VERSION "dbc-export 1 2026.26.6.5"

NS_ :

BS_:

BU_: APP APS BMS CC CMP CMPD CP DAS DI DIF DIR EPBL EPBR EVSE FC GTW HCML HCMR HVP ICR PCS PCS2 PLG PM PMF PMR PTC SCCM SCM SCS SDCR TAS UMC V2G VC VCBATT VCBATT0 VCBATT1 VCBATT2 VCFRONT VCFRONT1 VCFRONT2 VCLEFT VCRIGHT VCSEAT2L VCSEAT2R VCSEC

BO_ 946 BMS_log2: 8 BMS
 SG_ BMS_log2MuxId M : 0|7@1+ (1,0) [0|127] "" Vector__XXX
 SG_ BMS_maxChargeRestartNeededByVolt m0 : 7|1@1+ (1,0) [0|1] "" Vector__XXX
 SG_ BMS_cacAvg m0 : 8|13@1+ (0.1,0) [0|819.1] "Ah" Vector__XXX
 SG_ BMS_maxChargeNearComplete m0 : 21|1@1+ (1,0) [0|1] "" Vector__XXX
 SG_ BMS_cacMin m0 : 24|13@1+ (0.1,0) [0|819.1] "Ah" Vector__XXX
 SG_ BMS_cacMinBrickId m0 : 37|7@1+ (1,1) [1|128] "" Vector__XXX
 SG_ BMS_cacMax m0 : 44|13@1+ (0.1,0) [0|819.1] "Ah" Vector__XXX
 SG_ BMS_cacMaxBrickId m0 : 57|7@1+ (1,1) [1|128] "" Vector__XXX
 SG_ BMS_acRippleConfigNvramValid m18 : 7|1@1+ (1,0) [0|1] "" Vector__XXX
 SG_ BMS_hvChain_useLeakyBucket m18 : 8|1@1+ (1,0) [0|1] "" Vector__XXX
 SG_ BMS_hvChain_iLimit m18 : 9|14@1+ (0.2,0) [0|3275] "A" Vector__XXX
 SG_ BMS_hvChain_limitingState m18 : 23|9@1+ (1,1) [1|511] "" Vector__XXX
 SG_ BMS_hvChain_limitingStateTempera m18 : 32|13@1- (0.1,367.6) [-40|775] "DegC" Vector__XXX
 SG_ BMS_acRippleIsSupported m18 : 45|1@1+ (1,0) [0|1] "" Vector__XXX
 SG_ BMS_acRippleStartTemperatureMax m18 : 46|9@1+ (0.25,-25) [-25|100] "DegC" Vector__XXX
 SG_ BMS_acRippleStartTemperatureMin m18 : 55|9@1+ (0.25,-25) [-25|100] "DegC" Vector__XXX
 SG_ BMS_fcLinkTestDecayTime m20 : 8|10@1+ (2,0) [0|2044] "mS" Vector__XXX
 SG_ BMS_fcLinkTestTimeSinceLastRun m20 : 18|12@1+ (0.0175824183971,0) [0|71.99] "Hours" Vector__XXX
 SG_ BMS_pcsPrechargeRequest m20 : 30|2@1+ (1,0) [0|3] "" Vector__XXX
 SG_ BMS_pcsPrechargeTargetVoltage m20 : 32|16@1- (0.1,0) [-3276.8|3276.7] "V" Vector__XXX
 SG_ BMS_recentOvUvAlert m20 : 48|1@1+ (1,0) [0|1] "" Vector__XXX
 SG_ BMS_recentIsoAlert m20 : 49|1@1+ (1,0) [0|1] "" Vector__XXX
 SG_ BMS_recentBmbMiaAlert m20 : 50|1@1+ (1,0) [0|1] "" Vector__XXX
 SG_ BMS_cacBlendingConfigNvramValid m20 : 51|1@1+ (1,0) [0|1] "" Vector__XXX
 SG_ BMS_cacBlendingEnabled m20 : 52|1@1+ (1,0) [0|1] "" Vector__XXX
 SG_ BMS_cacBlendPercentPerCycle m20 : 53|10@1+ (0.001,0) [0|1.023] "%" Vector__XXX
 SG_ BMS_energyVariableChgRequested m21 : 8|1@1+ (1,0) [0|1] "" Vector__XXX
 SG_ BMS_packRestTime m21 : 9|12@1+ (0.0175824183971,0) [0|71.99] "Hours" Vector__XXX
 SG_ BMS_idealEnergyFloor m21 : 21|10@1+ (0.1,0) [0|102.2] "KWh" Vector__XXX
 SG_ BMS_thmGradientSlopeCondition m21 : 31|1@1+ (1,0) [0|1] "" Vector__XXX
 SG_ BMS_recentSlopeConditon m21 : 32|1@1+ (1,0) [0|1] "" Vector__XXX
 SG_ BMS_dynamicEnergyBuffer m21 : 33|10@1+ (0.1,0) [0|102.2] "KWh" Vector__XXX
 SG_ BMS_temperatureCondition m21 : 43|1@1+ (1,0) [0|1] "" Vector__XXX
 SG_ BMS_thmGradientSlope m21 : 44|10@1- (0.01,0) [-5.12|5.11] "C/min" Vector__XXX
 SG_ BMS_thmGradient m21 : 56|8@1+ (0.1,0) [0|25.5] "C" Vector__XXX
 SG_ BMS_epochTimeEstimate m29 : 8|32@1+ (1,0) [0|4294967295] "s" Vector__XXX
 SG_ BMS_histogramStartTimeIrrational m30 : 57|1@1+ (1,0) [0|1] "" Vector__XXX
 SG_ BMS_histogramDischargeThroughput m30 : 58|1@1+ (1,0) [0|1] "" Vector__XXX
 SG_ BMS_histogramChargeThroughputIrr m30 : 59|1@1+ (1,0) [0|1] "" Vector__XXX
 SG_ BMS_histogramTotalTimeIrrational m30 : 60|1@1+ (1,0) [0|1] "" Vector__XXX
 SG_ BMS_histogramStorageDataIsLow m30 : 61|1@1+ (1,0) [0|1] "" Vector__XXX
 SG_ BMS_tempVsSocTotalChgEnergy m31 : 7|25@1+ (0.000149011611938,0) [0|4999.99985097] "wh/wh" Vector__XXX
 SG_ BMS_powerVsVoltageTotalChgEnergy m31 : 32|25@1+ (0.000149011611938,0) [0|4999.99985097] "wh/wh" Vector__XXX
 SG_ BMS_lifeModelOutputsAreTrustwort m31 : 57|1@1+ (1,0) [0|1] "" Vector__XXX
 SG_ BMS_dSocNormalizedMin m33 : 8|12@1+ (0.0030517578125,-12.4969482422) [-12.4969482422|-0.003051757825] "%" Vector__XXX
 SG_ BMS_dSocNormalizedFiltMin m33 : 20|12@1+ (0.0030517578125,-12.4969482422) [-12.4969482422|-0.003051757825] "%" Vector__XXX
 SG_ BMS_dSocMinAlpha m33 : 32|12@1+ (0.0030517578125,-12.4969482422) [-12.4969482422|-0.003051757825] "%" Vector__XXX
 SG_ BMS_dSocMaxLowAlphaCounter m33 : 44|4@1+ (1,0) [0|15] "" Vector__XXX
 SG_ BMS_dSocMinAlphaBrickID m33 : 48|7@1+ (1,1) [1|128] "" Vector__XXX
 SG_ BMS_dSocCacMargin m33 : 55|9@1+ (0.0030517578125,0) [0|1.55639648438] "%" Vector__XXX
 SG_ BMS_lifeModelNoCurrentStorageCap m54 : 7|9@1+ (0.1,0) [0|51] "%" Vector__XXX
 SG_ BMS_lifeModelShortDcr m54 : 16|8@1+ (0.01,0) [0|2.54] "mOhm" Vector__XXX
 SG_ BMS_lifeModelLongDcr m54 : 24|13@1- (0.1,309.6) [-100|719] "mOhm" Vector__XXX
 SG_ BMS_lifeModelStorageCapacityLoss m54 : 37|9@1+ (0.1,0) [0|51] "%" Vector__XXX
 SG_ BMS_lifeModelThroughputCapacityL m54 : 46|9@1+ (0.1,0) [0|51] "%" Vector__XXX
 SG_ BMS_passiveCoolCellTargetT m54 : 55|9@1+ (0.25,-25) [-25|100] "DegC" Vector__XXX
 SG_ BMS_lifeModelAvgTempSeverity m55 : 8|5@1+ (0.1,0) [0|3] "-" Vector__XXX
 SG_ BMS_lifeModelDepthOfDischargeSev m55 : 16|8@1+ (0.01,0) [0|1.5] "-" Vector__XXX
 SG_ BMS_lifeModelHistogramCapacityLo m55 : 24|9@1+ (0.1,0) [0|51] "%" Vector__XXX
 SG_ BMS_lifeModelHistogramBrickCapac m55 : 33|13@1+ (0.1,0) [0|819] "Ah" Vector__XXX
 SG_ BMS_lifeModelDcrGrowthPercent m55 : 48|14@1- (0.1,200) [-100|500] "%" Vector__XXX
 SG_ BMS_nominalFullPackEnergyRaw m56 : 8|16@1+ (0.02,0) [0|1310.68] "kWh" Vector__XXX
 SG_ BMS_nominalEnergyRemainingBuffer m56 : 24|16@1+ (0.02,0) [0|1310.68] "kWh" Vector__XXX
 SG_ BMS_idealEnergyRemainingBuffered m56 : 40|16@1+ (0.02,0) [0|1310.68] "kWh" Vector__XXX
 SG_ BMS_largestSynchronizedCacErrorP m56 : 56|8@1+ (0.1,0) [0|25.4] "%" Vector__XXX
 SG_ BMS_lifeModelSpreadMinOffset m60 : 8|10@1- (0.1,0) [-51.1|51.1] "Ah" Vector__XXX
 SG_ BMS_lifeModelSpreadMaxOffset m60 : 18|10@1- (0.1,0) [-51.1|51.1] "Ah" Vector__XXX
 SG_ BMS_largestCacSpreadErrorLower m64 : 8|12@1+ (0.1,0) [0|409.4] "Ah" Vector__XXX
 SG_ BMS_lifeModelAverageCac m64 : 20|12@1+ (0.1,0) [0|409.4] "Ah" Vector__XXX
 SG_ BMS_lifeModelCacBrick1 m64 : 32|12@1+ (0.1,0) [0|409.4] "Ah" Vector__XXX
 SG_ BMS_lifeModelAverageOffset m64 : 44|10@1- (0.1,0) [-51.1|51.1] "Ah" Vector__XXX
 SG_ BMS_percentCacUpdatesInTimeWindo m64 : 54|10@1+ (0.1,0) [0|100] "%" Vector__XXX
 SG_ BMS_lifeModelMaxCacBrickId m65 : 8|8@1+ (1,1) [1|255] "" Vector__XXX
 SG_ BMS_lifeModelMaxCac m65 : 16|12@1+ (0.1,0) [0|409.4] "Ah" Vector__XXX
 SG_ BMS_lifeModelMinCacBrickId m65 : 28|8@1+ (1,1) [1|255] "" Vector__XXX
 SG_ BMS_lifeModelMinCac m65 : 36|12@1+ (0.1,0) [0|409.4] "Ah" Vector__XXX
 SG_ BMS_restingPointCacAvg m65 : 48|12@1+ (0.1,0) [0|409.4] "Ah" Vector__XXX
 SG_ BMS_cacEstimationSource m65 : 60|2@1+ (1,0) [0|3] "" Vector__XXX
 SG_ BMS_packCalibrationBirthDateBinn m67 : 26|32@1+ (1,0) [0|4294967295] "" Vector__XXX
 SG_ BMS_synchronizedCacMaxRaw m71 : 8|12@1+ (0.1,0) [0|409.4] "Ah" Vector__XXX
 SG_ BMS_synchronizedCacMinRaw m71 : 20|12@1+ (0.1,0) [0|409.4] "Ah" Vector__XXX
 SG_ BMS_largestSyncCacErrorStartSoc m71 : 32|10@1+ (0.1,0) [0|102.2] "%" Vector__XXX
 SG_ BMS_largestSyncCacErrorEndSoc m71 : 42|10@1+ (0.1,0) [0|102.2] "%" Vector__XXX
 SG_ BMS_runtimeSocConfigNvramValid m71 : 52|1@1+ (1,0) [0|1] "" Vector__XXX
 SG_ BMS_runtimeSocCorrectionsEnabled m71 : 53|1@1+ (1,0) [0|1] "" Vector__XXX
 SG_ BMS_rubberBandingEnabled m71 : 54|1@1+ (1,0) [0|1] "" Vector__XXX
 SG_ BMS_rubberBandingConfigNvramVali m71 : 55|1@1+ (1,0) [0|1] "" Vector__XXX
 SG_ BMS_runtimeSocMinTempForModel m71 : 56|6@1+ (0.5,0) [0|20] "DegC" Vector__XXX
 SG_ BMS_energyBufferConfigNvramValid m71 : 62|1@1+ (1,0) [0|1] "" Vector__XXX
 SG_ BMS_thermalEvent1pDetectConfigDi m71 : 63|1@1+ (1,0) [0|1] "" Vector__XXX
 SG_ BMS_sohEnergy m79 : 8|11@1+ (0.1,0) [0|204.6] "KWh" Vector__XXX
 SG_ BMS_fullCapacitySohEnergy m79 : 19|11@1+ (0.1,0) [0|204.6] "KWh" Vector__XXX
 SG_ BMS_calibratedCapacitySohEnergy m79 : 30|11@1+ (0.1,0) [0|204.6] "KWh" Vector__XXX
 SG_ BMS_estimatedCapacitySohEnergy m79 : 41|11@1+ (0.1,0) [0|204.6] "KWh" Vector__XXX
 SG_ BMS_prevUserFacingSohEnergy m79 : 52|11@1+ (0.1,0) [0|204.6] "KWh" Vector__XXX
 SG_ BMS_stateOfHealthMinCac m80 : 8|13@1+ (0.1,0) [0|819] "Ah" Vector__XXX
 SG_ BMS_lifeModelStorageLossPackAge m80 : 24|14@1+ (1,0) [0|16382] "days" Vector__XXX
 SG_ BMS_lifeModelThroughputDcrCycleC m80 : 38|12@1+ (1,0) [0|4094] "Cycles" Vector__XXX
 SG_ BMS_stateOfHealthMinCacLowerBoun m80 : 50|13@1+ (0.1,0) [0|819] "Ah" Vector__XXX
 SG_ BMS_energyWalkCounter m83 : 8|8@1+ (1,0) [0|255] "" Vector__XXX
 SG_ BMS_energyWalkTimeoutCounter m83 : 16|8@1+ (1,0) [0|255] "" Vector__XXX
 SG_ BMS_dynamicCcvEnabled m83 : 24|1@1+ (1,0) [0|1] "" Vector__XXX
 SG_ BMS_chargeTargetLookupSoc m83 : 25|10@1+ (0.1,0) [0|102.2] "%" Vector__XXX
 SG_ BMS_stateOfHealth m83 : 35|10@1+ (0.1,0) [0|100] "%" Vector__XXX
 SG_ BMS_avgShuntAsicCurrentOffset m83 : 48|15@1- (0.2,0) [-3276.6|3276.6] "mA" Vector__XXX
 SG_ BMS_cellAttributesGeneralAttribu m85 : 7|32@1+ (1,0) [1|4294967295] "" Vector__XXX
 SG_ BMS_cellAttributesPackManufactur m85 : 39|3@1+ (1,0) [1|7] "" Vector__XXX
 SG_ BMS_cellAttributesRemanufactured m85 : 42|1@1+ (1,0) [0|1] "" Vector__XXX
 SG_ BMS_cellAttributesConfigNvramVal m85 : 43|1@1+ (1,0) [0|1] "" Vector__XXX
 SG_ BMS_cellAttributesCellType m85 : 44|6@1+ (1,0) [1|63] "" Vector__XXX
 SG_ BMS_cellAttributesAutocloseAndSc m85 : 50|1@1+ (1,0) [0|1] "" Vector__XXX
 SG_ BMS_cellAttributesShipPackForFai m85 : 51|1@1+ (1,0) [0|1] "" Vector__XXX
 SG_ BMS_lifeModelThroughputCycleCoun m85 : 52|12@1+ (1,0) [0|4094] "Cycles" Vector__XXX
 SG_ BMS_limpChargeCurrentLimit m89 : 8|10@1+ (1,0) [0|1022] "A" Vector__XXX
 SG_ BMS_energyRemainingDisplayError m89 : 18|10@1- (0.1,0) [-50|50] "kWh" Vector__XXX
 SG_ BMS_energyRemainingTDisplayError m89 : 28|10@1- (0.1,0) [-50|50] "kWh" Vector__XXX
 SG_ BMS_numOfThermistors m89 : 38|5@1+ (1,0) [0|31] "" Vector__XXX
 SG_ BMS_numOfBricks m89 : 43|8@1+ (1,0) [0|255] "" Vector__XXX
 SG_ BMS_cellChargeDcCurrentLimit m89 : 51|12@1+ (0.5,0) [0|2047.5] "A" Vector__XXX
 SG_ BMS_socByDeltaVEnabled m90 : 8|1@1+ (1,0) [0|1] "" Vector__XXX
 SG_ BMS_socByDvMaxSocLimit m90 : 9|10@1+ (0.1,0) [0|102.2] "%" Vector__XXX
 SG_ BMS_socByDvVoltageChangeOverAh m90 : 19|9@1+ (0.002,0) [0|1] "V" Vector__XXX
 SG_ BMS_socByDvMaxSocByAhCorrected m90 : 28|10@1+ (0.1,0) [0|102.2] "%" Vector__XXX
 SG_ BMS_socByDvMaxBrickVoltage m90 : 40|12@1+ (0.002,0) [0|5] "V" Vector__XXX
 SG_ BMS_socByDvMaxBrickId m90 : 56|8@1+ (1,1) [1|256] "" Vector__XXX
 SG_ BMS_socByDvMaxSocByAhRaw m91 : 8|10@1+ (0.1,0) [0|102.2] "%" Vector__XXX
 SG_ BMS_voltageInstabilityExcessNois m91 : 18|12@1+ (0.1,0) [0|408] "counts" Vector__XXX
 SG_ BMS_maxModelThermistorTempDelta m91 : 30|10@1- (0.1,0) [-51.2|51.1] "C" Vector__XXX
 SG_ BMS_activeCoolCellTargetT m91 : 40|9@1+ (0.25,-25) [-25|100] "DegC" Vector__XXX
 SG_ BMS_cellTempTargetMode m91 : 49|4@1+ (1,0) [0|15] "" Vector__XXX
 SG_ BMS_minPackTempForChargeToStart m91 : 56|7@1+ (0.5,-40) [-40|23.5] "C" Vector__XXX

BO_ 914 BMS_packConfig: 8 BMS
 SG_ BMS_packConfigMultiplexer M : 0|8@1+ (1,0) [0|255] "" Vector__XXX
 SG_ BMS_reservedConfig_0 m0 : 8|6@1+ (1,0) [0|63] "" Vector__XXX
 SG_ BMS_moduleType m1 : 8|3@1+ (1,0) [0|7] "" Vector__XXX
 SG_ BMS_thermalPackType m1 : 11|4@1+ (1,0) [0|15] "" Vector__XXX
 SG_ BMS_packMass m1 : 16|8@1+ (1,300) [342|540] "kg" Vector__XXX
 SG_ BMS_platformMaxBusVoltage m1 : 24|10@1+ (1,300) [300|1300] "V" Vector__XXX
 SG_ BMS_standbySupplyContinuousPower m1 : 36|2@1+ (1,0) [0|3] "" Vector__XXX
 SG_ BMS_beginningOfLifePackEnergy m1 : 40|10@1+ (0.1,0) [0|102.2] "KWh" Vector__XXX

BO_ 1810 BMS_packTemperatureMeasurements: 8 BMS
 SG_ BMS_packTemperatureMultiplexer M : 0|8@1+ (1,0) [0|255] "" Vector__XXX
 SG_ BMS_packTemperatureCounter : 14|2@1+ (1,0) [0|3] "" Vector__XXX
 SG_ BMS_packTemperatureStatus1 m0 : 8|2@1+ (1,0) [0|3] "" Vector__XXX
 SG_ BMS_packTemperatureStatus2 m0 : 10|2@1+ (1,0) [0|3] "" Vector__XXX
 SG_ BMS_packTemperatureStatus3 m0 : 12|2@1+ (1,0) [0|3] "" Vector__XXX
 SG_ BMS_packTemperature1 m0 : 16|16@1- (0.01,0) [-327.68|327.67] "C" Vector__XXX
 SG_ BMS_packTemperature2 m0 : 32|16@1- (0.01,0) [-327.68|327.67] "C" Vector__XXX
 SG_ BMS_packTemperature3 m0 : 48|16@1- (0.01,0) [-327.68|327.67] "C" Vector__XXX
 SG_ BMS_packTemperatureStatus4 m1 : 8|2@1+ (1,0) [0|3] "" Vector__XXX
 SG_ BMS_packTemperatureStatus5 m1 : 10|2@1+ (1,0) [0|3] "" Vector__XXX
 SG_ BMS_packTemperatureStatus6 m1 : 12|2@1+ (1,0) [0|3] "" Vector__XXX
 SG_ BMS_packTemperature4 m1 : 16|16@1- (0.01,0) [-327.68|327.67] "C" Vector__XXX
 SG_ BMS_packTemperature5 m1 : 32|16@1- (0.01,0) [-327.68|327.67] "C" Vector__XXX
 SG_ BMS_packTemperature6 m1 : 48|16@1- (0.01,0) [-327.68|327.67] "C" Vector__XXX
 SG_ BMS_packTemperatureStatus7 m2 : 8|2@1+ (1,0) [0|3] "" Vector__XXX
 SG_ BMS_packTemperatureStatus8 m2 : 10|2@1+ (1,0) [0|3] "" Vector__XXX
 SG_ BMS_packTemperatureStatus9 m2 : 12|2@1+ (1,0) [0|3] "" Vector__XXX
 SG_ BMS_packTemperature7 m2 : 16|16@1- (0.01,0) [-327.68|327.67] "C" Vector__XXX
 SG_ BMS_packTemperature8 m2 : 32|16@1- (0.01,0) [-327.68|327.67] "C" Vector__XXX
 SG_ BMS_packTemperature9 m2 : 48|16@1- (0.01,0) [-327.68|327.67] "C" Vector__XXX
 SG_ BMS_packTemperatureStatus10 m3 : 8|2@1+ (1,0) [0|3] "" Vector__XXX
 SG_ BMS_packTemperatureStatus11 m3 : 10|2@1+ (1,0) [0|3] "" Vector__XXX
 SG_ BMS_packTemperatureStatus12 m3 : 12|2@1+ (1,0) [0|3] "" Vector__XXX
 SG_ BMS_packTemperature10 m3 : 16|16@1- (0.01,0) [-327.68|327.67] "C" Vector__XXX
 SG_ BMS_packTemperature11 m3 : 32|16@1- (0.01,0) [-327.68|327.67] "C" Vector__XXX
 SG_ BMS_packTemperature12 m3 : 48|16@1- (0.01,0) [-327.68|327.67] "C" Vector__XXX
 SG_ BMS_packTemperatureStatus13 m4 : 8|2@1+ (1,0) [0|3] "" Vector__XXX
 SG_ BMS_packTemperatureStatus14 m4 : 10|2@1+ (1,0) [0|3] "" Vector__XXX
 SG_ BMS_packTemperatureStatus15 m4 : 12|2@1+ (1,0) [0|3] "" Vector__XXX
 SG_ BMS_packTemperature13 m4 : 16|16@1- (0.01,0) [-327.68|327.67] "C" Vector__XXX
 SG_ BMS_packTemperature14 m4 : 32|16@1- (0.01,0) [-327.68|327.67] "C" Vector__XXX
 SG_ BMS_packTemperature15 m4 : 48|16@1- (0.01,0) [-327.68|327.67] "C" Vector__XXX
 SG_ BMS_packTemperatureStatus16 m5 : 8|2@1+ (1,0) [0|3] "" Vector__XXX
 SG_ BMS_packTemperatureStatus17 m5 : 10|2@1+ (1,0) [0|3] "" Vector__XXX
 SG_ BMS_packTemperatureStatus18 m5 : 12|2@1+ (1,0) [0|3] "" Vector__XXX
 SG_ BMS_packTemperature16 m5 : 16|16@1- (0.01,0) [-327.68|327.67] "C" Vector__XXX
 SG_ BMS_packTemperature17 m5 : 32|16@1- (0.01,0) [-327.68|327.67] "C" Vector__XXX
 SG_ BMS_packTemperature18 m5 : 48|16@1- (0.01,0) [-327.68|327.67] "C" Vector__XXX

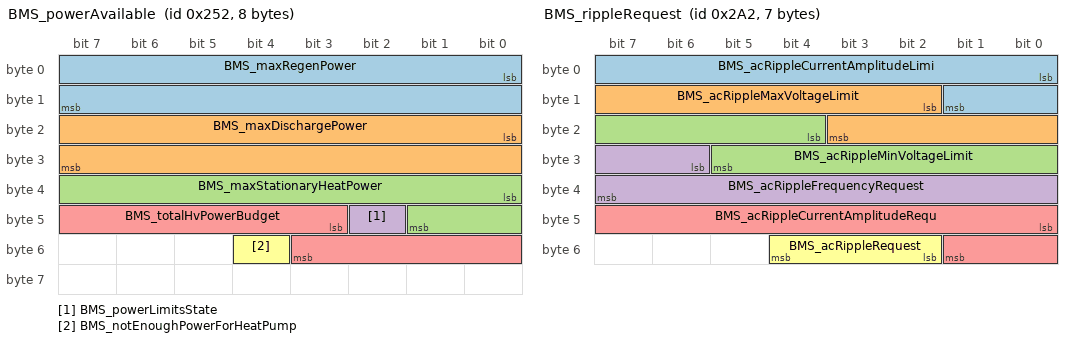
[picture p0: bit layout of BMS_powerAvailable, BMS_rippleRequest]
BO_ 594 BMS_powerAvailable: 8 BMS
 SG_ BMS_maxRegenPower : 0|16@1+ (0.01,0) [0|655.35] "kW" Vector__XXX
 SG_ BMS_maxDischargePower : 16|16@1+ (0.013,0) [0|850] "kW" Vector__XXX
 SG_ BMS_maxStationaryHeatPower : 32|10@1+ (0.01,0) [0|10.23] "kW" Vector__XXX
 SG_ BMS_powerLimitsState : 42|1@1+ (1,0) [0|1] "" Vector__XXX
 SG_ BMS_totalHvPowerBudget : 43|9@1+ (0.1,0) [0|51.1] "kW" Vector__XXX
 SG_ BMS_notEnoughPowerForHeatPump : 52|1@1+ (1,0) [0|1] "" Vector__XXX

BO_ 674 BMS_rippleRequest: 7 BMS
 SG_ BMS_acRippleCurrentAmplitudeLimi : 0|10@1+ (1,0) [0|1023] "A" Vector__XXX
 SG_ BMS_acRippleMaxVoltageLimit : 10|10@1+ (1,0) [0|1023] "V" Vector__XXX
 SG_ BMS_acRippleMinVoltageLimit : 20|10@1+ (1,0) [0|1023] "V" Vector__XXX
 SG_ BMS_acRippleFrequencyRequest : 30|10@1+ (1,0) [0|1022] "Hz" Vector__XXX
 SG_ BMS_acRippleCurrentAmplitudeRequ : 40|10@1+ (1,0) [0|1023] "A" Vector__XXX
 SG_ BMS_acRippleRequest : 50|3@1+ (1,0) [0|7] "" Vector__XXX

BO_ 1834 BMS_serialNumber: 8 BMS
 SG_ BMS_serialNumberMultiplexer M : 0|2@1+ (1,0) [0|2] "" Vector__XXX
 SG_ BMS_packSerialNumberByte01 m0 : 8|8@1+ (1,0) [0|255] "" Vector__XXX
 SG_ BMS_packSerialNumberByte02 m0 : 16|8@1+ (1,0) [0|255] "" Vector__XXX
 SG_ BMS_packSerialNumberByte03 m0 : 24|8@1+ (1,0) [0|255] "" Vector__XXX
 SG_ BMS_packSerialNumberByte04 m0 : 32|8@1+ (1,0) [0|255] "" Vector__XXX
 SG_ BMS_packSerialNumberByte05 m0 : 40|8@1+ (1,0) [0|255] "" Vector__XXX
 SG_ BMS_packSerialNumberByte06 m0 : 48|8@1+ (1,0) [0|255] "" Vector__XXX
 SG_ BMS_packSerialNumberByte07 m0 : 56|8@1+ (1,0) [0|255] "" Vector__XXX
 SG_ BMS_packSerialNumberByte08 m1 : 8|8@1+ (1,0) [0|255] "" Vector__XXX
 SG_ BMS_packSerialNumberByte09 m1 : 16|8@1+ (1,0) [0|255] "" Vector__XXX
 SG_ BMS_packSerialNumberByte10 m1 : 24|8@1+ (1,0) [0|255] "" Vector__XXX
 SG_ BMS_packSerialNumberByte11 m1 : 32|8@1+ (1,0) [0|255] "" Vector__XXX
 SG_ BMS_packSerialNumberByte12 m1 : 40|8@1+ (1,0) [0|255] "" Vector__XXX
 SG_ BMS_packSerialNumberByte13 m1 : 48|8@1+ (1,0) [0|255] "" Vector__XXX
 SG_ BMS_packSerialNumberByte14 m1 : 56|8@1+ (1,0) [0|255] "" Vector__XXX
 SG_ BMS_packSerialBirthDateBinned m2 : 8|32@1+ (1,0) [0|4294967295] "" Vector__XXX

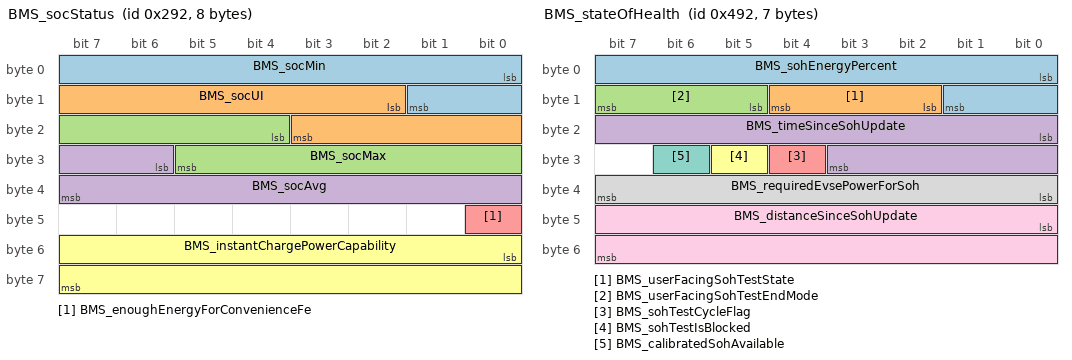
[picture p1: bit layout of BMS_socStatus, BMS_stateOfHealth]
BO_ 658 BMS_socStatus: 8 BMS
 SG_ BMS_socMin : 0|10@1+ (0.1,0) [0|102.2] "%" Vector__XXX
 SG_ BMS_socUI : 10|10@1+ (0.1,0) [0|100] "%" Vector__XXX
 SG_ BMS_socMax : 20|10@1+ (0.1,0) [0|102.2] "%" Vector__XXX
 SG_ BMS_socAvg : 30|10@1+ (0.1,0) [0|102.2] "%" Vector__XXX
 SG_ BMS_enoughEnergyForConvenienceFe : 40|1@1+ (1,0) [0|1] "" Vector__XXX
 SG_ BMS_instantChargePowerCapability : 48|16@1+ (0.05,0) [0|3276.7] "kW" Vector__XXX

BO_ 1170 BMS_stateOfHealth: 7 BMS
 SG_ BMS_sohEnergyPercent : 0|10@1+ (0.1,0) [0|100] "%" Vector__XXX
 SG_ BMS_userFacingSohTestState : 10|3@1+ (1,0) [0|7] "" Vector__XXX
 SG_ BMS_userFacingSohTestEndMode : 13|3@1+ (1,0) [0|7] "" Vector__XXX
 SG_ BMS_timeSinceSohUpdate : 16|12@1+ (1,0) [0|3650] "days" Vector__XXX
 SG_ BMS_sohTestCycleFlag : 28|1@1+ (1,0) [0|1] "" Vector__XXX
 SG_ BMS_sohTestIsBlocked : 29|1@1+ (1,0) [0|1] "" Vector__XXX
 SG_ BMS_calibratedSohAvailable : 30|1@1+ (1,0) [0|1] "" Vector__XXX
 SG_ BMS_requiredEvsePowerForSoh : 32|8@1+ (0.125,0) [0|31.75] "kW" Vector__XXX
 SG_ BMS_distanceSinceSohUpdate : 40|16@1+ (1,0) [0|65534] "km" Vector__XXX

BO_ 530 BMS_status: 8 BMS
 SG_ BMS_hvacPowerRequest : 0|1@1+ (1,0) [0|1] "" Vector__XXX
 SG_ BMS_notEnoughPowerForDrive : 1|1@1+ (1,0) [0|1] "" Vector__XXX
 SG_ BMS_notEnoughPowerForSupport : 2|1@1+ (1,0) [0|1] "" Vector__XXX
 SG_ BMS_preconditionAllowed : 3|1@1+ (1,0) [0|1] "" Vector__XXX
 SG_ BMS_updateAllowed : 4|1@1+ (1,0) [0|1] "" Vector__XXX
 SG_ BMS_cpMiaOnHvs : 5|1@1+ (1,0) [0|1] "" Vector__XXX
 SG_ BMS_pcsPwmEnabled : 6|1@1+ (1,0) [0|1] "" Vector__XXX
 SG_ BMS_contactorState : 8|3@1+ (1,0) [1|7] "" Vector__XXX
 SG_ BMS_userChargeStatus : 11|3@1+ (1,0) [0|7] "" Vector__XXX
 SG_ BMS_batteryInputPower : 14|16@1+ (0.05,0) [0|3276.7] "kW" Vector__XXX
 SG_ BMS_chargeRequest : 30|1@1+ (1,0) [0|1] "" Vector__XXX
 SG_ BMS_state : 32|4@1+ (1,0) [0|15] "" Vector__XXX
 SG_ BMS_diLimpRequest : 36|1@1+ (1,0) [0|1] "" Vector__XXX
 SG_ BMS_okToShipByAir : 37|1@1+ (1,0) [0|1] "" Vector__XXX
 SG_ BMS_okToShipByLand : 38|1@1+ (1,0) [0|1] "" Vector__XXX
 SG_ BMS_chgPowerAvailable : 39|12@1+ (0.125,0) [0|511.75] "kW" Vector__XXX
 SG_ BMS_acManagerState : 52|4@1+ (1,0) [0|15] "" Vector__XXX
 SG_ BMS_conditioningRequest : 56|1@1+ (1,0) [0|1] "" Vector__XXX
 SG_ BMS_smStateRequest : 57|4@1+ (1,0) [0|15] "" Vector__XXX
 SG_ BMS_hvState : 61|3@1+ (1,0) [0|7] "" Vector__XXX

BO_ 786 BMS_thermalStatus: 8 BMS
 SG_ BMS_thermalStatusMultiplexer M : 0|2@1+ (1,0) [0|3] "" Vector__XXX
 SG_ BMS_inletActiveCoolTargetT m0 : 2|9@1+ (0.25,-25) [-25|100] "DegC" Vector__XXX
 SG_ BMS_inletPassiveTargetT m0 : 11|9@1+ (0.25,-25) [-25|100] "DegC" Vector__XXX
 SG_ BMS_inletActiveHeatTargetT m0 : 20|9@1+ (0.25,-25) [-25|100] "DegC" Vector__XXX
 SG_ BMS_requestDischarge m0 : 29|1@1+ (1,0) [0|1] "" Vector__XXX
 SG_ BMS_activeHeatingWorthwhile m0 : 30|1@1+ (1,0) [0|1] "" Vector__XXX
 SG_ BMS_pcsNoFlowRequest m0 : 31|1@1+ (1,0) [0|1] "" Vector__XXX
 SG_ BMS_minPackTemperature m0 : 32|10@1+ (0.2,-40) [-40|164.6] "DegC" Vector__XXX
 SG_ BMS_noFlowRequest m0 : 42|1@1+ (1,0) [0|1] "" Vector__XXX
 SG_ BMS_maxPackTemperature m0 : 43|11@1+ (0.1,-40) [-40|164.7] "DegC" Vector__XXX
 SG_ BMS_flowRequest m0 : 56|8@1+ (0.25,0) [0|60] "LPM" Vector__XXX
 SG_ BMS_coldStagnationLimit m1 : 2|9@1+ (0.25,-25) [-25|100] "DegC" Vector__XXX
 SG_ BMS_hotStagnationLimit m1 : 11|9@1+ (0.25,-25) [-25|100] "DegC" Vector__XXX
 SG_ BMS_hotCellTempLimit m1 : 20|9@1+ (0.25,-25) [-25|100] "DegC" Vector__XXX
 SG_ BMS_i2tDeratingEnabled m1 : 29|1@1+ (1,0) [0|1] "" Vector__XXX
 SG_ BMS_activeCoolCellReferenceT m1 : 32|9@1+ (0.25,-25) [-25|100] "DegC" Vector__XXX
 SG_ BMS_activeHeatCellTargetT m1 : 41|9@1+ (0.25,-25) [-25|100] "DegC" Vector__XXX
 SG_ BMS_powerDissipation m1 : 50|10@1+ (0.02,0) [0|20] "kW" Vector__XXX

BO_ 1554 BMS_udsResponse: 8 BMS
 SG_ BMS_udsResponseData : 7|64@0+ (1,0) [0|1.84467440737e+19] "" Vector__XXX

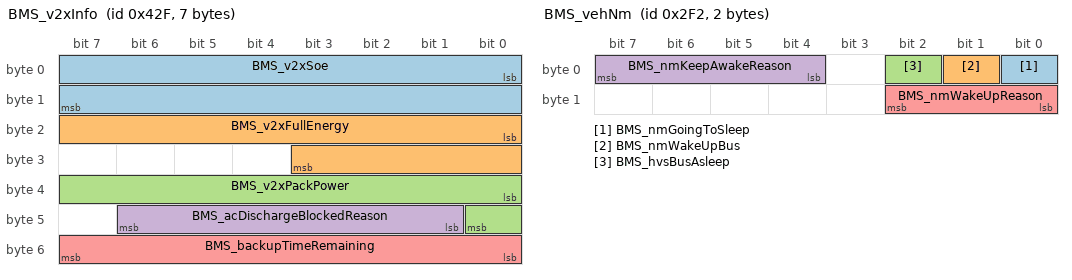
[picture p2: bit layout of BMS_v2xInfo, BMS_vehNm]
BO_ 1071 BMS_v2xInfo: 7 BMS
 SG_ BMS_v2xSoe : 0|16@1+ (0.002,0) [0|100] "%" Vector__XXX
 SG_ BMS_v2xFullEnergy : 16|12@1+ (0.05,0) [0|200] "kWh" Vector__XXX
 SG_ BMS_v2xPackPower : 32|9@1+ (0.1,-25) [-25|25] "kW" Vector__XXX
 SG_ BMS_acDischargeBlockedReason : 41|6@1+ (1,0) [0|63] "" Vector__XXX
 SG_ BMS_backupTimeRemaining : 48|8@1+ (1,0) [0|254] "Hours" Vector__XXX

BO_ 754 BMS_vehNm: 2 BMS
 SG_ BMS_nmGoingToSleep : 0|1@1+ (1,0) [0|1] "" Vector__XXX
 SG_ BMS_nmWakeUpBus : 1|1@1+ (1,0) [0|1] "" Vector__XXX
 SG_ BMS_hvsBusAsleep : 2|1@1+ (1,0) [0|1] "" Vector__XXX
 SG_ BMS_nmKeepAwakeReason : 4|4@1+ (1,0) [1|15] "" Vector__XXX
 SG_ BMS_nmWakeUpReason : 8|3@1+ (1,0) [0|7] "" Vector__XXX

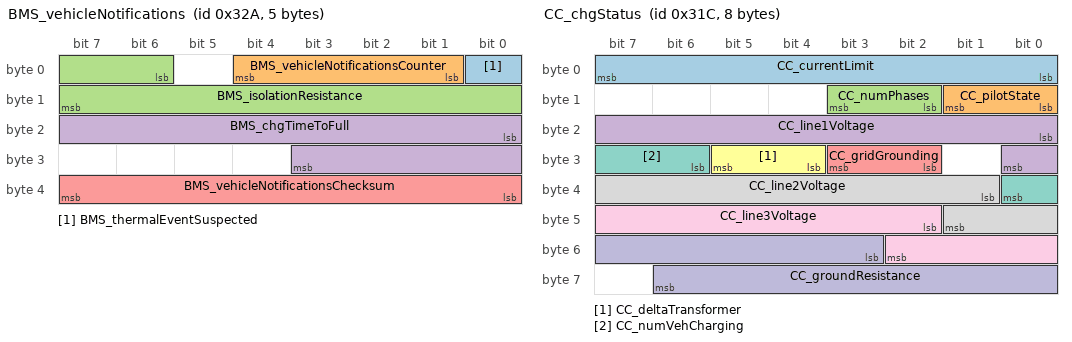
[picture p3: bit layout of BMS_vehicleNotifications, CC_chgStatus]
BO_ 810 BMS_vehicleNotifications: 5 BMS
 SG_ BMS_thermalEventSuspected : 0|1@1+ (1,0) [0|1] "" Vector__XXX
 SG_ BMS_vehicleNotificationsCounter : 1|4@1+ (1,0) [0|15] "" Vector__XXX
 SG_ BMS_isolationResistance : 6|10@1+ (10,0) [0|10000] "kOhm" Vector__XXX
 SG_ BMS_chgTimeToFull : 16|12@1+ (0.01666667,0) [0|68.23334698] "Hours" Vector__XXX
 SG_ BMS_vehicleNotificationsChecksum : 32|8@1+ (1,0) [0|255] "" Vector__XXX

BO_ 1116 CC_alertLog: 8 CC
 SG_ CC_alertID M : 0|15@1+ (1,0) [0|32767] "" Vector__XXX
 SG_ CC_alertType : 15|1@1+ (1,0) [0|1] "" Vector__XXX
 SG_ CC_a001_groundResistance m1 : 16|12@1+ (1000,0) [0|4094000] "Ohm" Vector__XXX
 SG_ CC_a003_gfciRmsCurrent m3 : 16|12@1+ (0.001,0) [0|4.095] "A" Vector__XXX
 SG_ CC_a003_gfciRmsCurrentAvg m3 : 28|12@1+ (0.001,0) [0|4.095] "A" Vector__XXX
 SG_ CC_a003_dcGfciCurrent m3 : 40|10@1- (0.001,0) [-0.512|0.511] "A" Vector__XXX
 SG_ CC_a003_gfciFaultReason m3 : 50|4@1+ (1,0) [1|15] "" Vector__XXX
 SG_ CC_a003_gfciFaultBucket m3 : 56|4@1+ (1,0) [0|15] "" Vector__XXX
 SG_ CC_a004_gfciErrorReason m4 : 16|8@1+ (1,0) [1|255] "" Vector__XXX
 SG_ CC_a004_gfciAsicErrorBitfield m4 : 24|8@1+ (1,0) [0|255] "" Vector__XXX
 SG_ CC_a004_gfciSelfTestDuty m4 : 32|16@1- (0.0001,50) [46.7232|53.2767] "A" Vector__XXX
 SG_ CC_a004_gfciSelfTestCurrent m4 : 48|16@1- (0.0001,0) [-3.2768|3.2767] "A" Vector__XXX
 SG_ CC_a006_line1Current m6 : 16|16@1+ (0.01,0) [0|655.35] "A" Vector__XXX
 SG_ CC_a006_line2Current m6 : 32|16@1+ (0.01,0) [0|655.35] "A" Vector__XXX
 SG_ CC_a006_line3Current m6 : 48|16@1+ (0.01,0) [0|655.35] "A" Vector__XXX
 SG_ CC_a007_inputVoltage m7 : 16|16@1+ (0.01,0) [0|655.35] "V" Vector__XXX
 SG_ CC_a007_inputLineVoltage m7 : 32|16@1+ (0.01,0) [0|655.35] "V" Vector__XXX
 SG_ CC_a007_inputNeutralVoltage m7 : 48|16@1+ (0.01,0) [0|655.35] "V" Vector__XXX
 SG_ CC_a008_inputVoltage m8 : 16|16@1+ (0.01,0) [0|655.35] "V" Vector__XXX
 SG_ CC_a008_inputLineVoltage m8 : 32|16@1+ (0.01,0) [0|655.35] "V" Vector__XXX
 SG_ CC_a008_inputNeutralVoltage m8 : 48|16@1+ (0.01,0) [0|655.35] "V" Vector__XXX
 SG_ CC_a010_line1Voltage m10 : 16|12@1+ (0.1,0) [0|409.5] "V" Vector__XXX
 SG_ CC_a010_line2Voltage m10 : 28|12@1+ (0.1,0) [0|409.5] "V" Vector__XXX
 SG_ CC_a010_line3Voltage m10 : 40|12@1+ (0.1,0) [0|409.5] "V" Vector__XXX
 SG_ CC_a010_line1StuckClosed m10 : 52|1@1+ (1,0) [0|1] "" Vector__XXX
 SG_ CC_a010_line2StuckClosed m10 : 53|1@1+ (1,0) [0|1] "" Vector__XXX
 SG_ CC_a010_line3StuckClosed m10 : 54|1@1+ (1,0) [0|1] "" Vector__XXX
 SG_ CC_a011_pcbaTemp m11 : 16|9@1- (1,88) [-168|343] "DegC" Vector__XXX
 SG_ CC_a012_inputThermopile m12 : 16|12@1+ (1.0e-06,0) [0|0.004095] "V" Vector__XXX
 SG_ CC_a012_inputThermopileDvdt m12 : 28|12@1+ (1.0e-06,0) [0|0.004095] "V/sec" Vector__XXX
 SG_ CC_a013_handleTemp m13 : 16|9@1- (1,88) [-168|343] "DegC" Vector__XXX
 SG_ CC_a014_failureCause m14 : 16|9@1+ (1,0) [0|511] "" Vector__XXX
 SG_ CC_a014_meterFaultAddress m14 : 25|16@1+ (1,0) [0|65535] "" Vector__XXX
 SG_ CC_a014_meterFaultData m14 : 41|16@1+ (1,0) [0|65535] "" Vector__XXX
 SG_ CC_a014_meterRetryCount m14 : 57|4@1+ (1,0) [0|15] "" Vector__XXX
 SG_ CC_a015_pilotHighVolage m15 : 16|16@1+ (0.001,0) [0|65.535] "V" Vector__XXX
 SG_ CC_a015_smState m15 : 32|8@1+ (1,0) [0|255] "" Vector__XXX
 SG_ CC_a027_handleTemperature m27 : 16|12@1- (0.1,0) [-204.8|204.7] "DegC" Vector__XXX
 SG_ CC_a027_handleTempFaultReason m27 : 28|4@1+ (1,0) [0|15] "" Vector__XXX
 SG_ CC_a032_meteringSpiCommsFailure m32 : 16|1@1+ (1,0) [0|1] "" Vector__XXX
 SG_ CC_a032_meteringConfigMismatch m32 : 17|1@1+ (1,0) [0|1] "" Vector__XXX
 SG_ CC_a033_nominalVoltage m33 : 16|9@1+ (0.01,0) [0|5.11] "V" Vector__XXX
 SG_ CC_a033_measuredVoltage m33 : 25|9@1+ (0.01,0) [0|5.11] "V" Vector__XXX
 SG_ CC_a036_line1Voltage m36 : 16|12@1+ (0.1,0) [0|409.5] "V" Vector__XXX
 SG_ CC_a036_line2Voltage m36 : 28|12@1+ (0.1,0) [0|409.5] "V" Vector__XXX
 SG_ CC_a036_line3Voltage m36 : 40|12@1+ (0.1,0) [0|409.5] "V" Vector__XXX
 SG_ CC_a036_line1StuckOpen m36 : 52|1@1+ (1,0) [0|1] "" Vector__XXX
 SG_ CC_a036_line2StuckOpen m36 : 53|1@1+ (1,0) [0|1] "" Vector__XXX
 SG_ CC_a036_line3StuckOpen m36 : 54|1@1+ (1,0) [0|1] "" Vector__XXX
 SG_ CC_a037_expiredWatchdogModuleId m37 : 16|8@1+ (1,0) [0|255] "" Vector__XXX
 SG_ CC_a037_expiredWatchdogTaskId m37 : 24|8@1+ (1,0) [0|255] "" Vector__XXX
 SG_ CC_a037_expiredWatchdogAppCRC m37 : 32|32@1+ (1,0) [0|4294967295] "" Vector__XXX
 SG_ CC_a038_moduleMiaModuleId m38 : 16|8@1+ (1,0) [0|255] "" Vector__XXX
 SG_ CC_a038_moduleMiaTaskId m38 : 24|8@1+ (1,0) [0|255] "" Vector__XXX
 SG_ CC_a038_moduleMiaAppCRC m38 : 32|32@1+ (1,0) [0|4294967295] "" Vector__XXX
 SG_ CC_a039_intModuleTemperature m39 : 16|9@1- (1,88) [-168|343] "DegC" Vector__XXX
 SG_ CC_a040_handleTemperature m40 : 16|9@1- (1,88) [-168|343] "DegC" Vector__XXX
 SG_ CC_a041_inputThermopile m41 : 16|16@1- (1.0e-06,0) [-0.032768|0.032767] "V" Vector__XXX
 SG_ CC_a041_inputThermopileDvdt m41 : 32|16@1- (1.0e-06,0) [-0.032768|0.032767] "V/sec" Vector__XXX
 SG_ CC_a042_pcbaTemperature m42 : 16|9@1- (1,88) [-168|343] "DegC" Vector__XXX
 SG_ CC_a044_relayCoilVoltage m44 : 16|8@1+ (0.14,0) [0|35.7] "V" Vector__XXX
 SG_ CC_a044_pcbaTemperature m44 : 24|9@1- (1,88) [-168|343] "DegC" Vector__XXX

BO_ 1132 CC_alertMatrix1: 8 CC
 SG_ CC_a001_gndMonIntrptLineSide : 0|1@1+ (1,0) [0|1] "" Vector__XXX
 SG_ CC_a002_gndMonIntrptLoadSide : 1|1@1+ (1,0) [0|1] "" Vector__XXX
 SG_ CC_a003_CCIDTripped : 2|1@1+ (1,0) [0|1] "" Vector__XXX
 SG_ CC_a004_CCIDSelfTestFault : 3|1@1+ (1,0) [0|1] "" Vector__XXX
 SG_ CC_a005_groundedNeutral : 4|1@1+ (1,0) [0|1] "" Vector__XXX
 SG_ CC_a006_inputOverCurrent : 5|1@1+ (1,0) [0|1] "" Vector__XXX
 SG_ CC_a007_inputOverVoltage : 6|1@1+ (1,0) [0|1] "" Vector__XXX
 SG_ CC_a008_inputUnderVoltage : 7|1@1+ (1,0) [0|1] "" Vector__XXX
 SG_ CC_a009_inputMiswired : 8|1@1+ (1,0) [0|1] "" Vector__XXX
 SG_ CC_a010_contactorWelded : 9|1@1+ (1,0) [0|1] "" Vector__XXX
 SG_ CC_a011_ambientOT : 10|1@1+ (1,0) [0|1] "" Vector__XXX
 SG_ CC_a012_wallPlugOT : 11|1@1+ (1,0) [0|1] "" Vector__XXX
 SG_ CC_a013_vehConnOT : 12|1@1+ (1,0) [0|1] "" Vector__XXX
 SG_ CC_a014_mcuSelfTestFault : 13|1@1+ (1,0) [0|1] "" Vector__XXX
 SG_ CC_a015_PilotAFault : 14|1@1+ (1,0) [0|1] "" Vector__XXX
 SG_ CC_a016_PilotBFault : 15|1@1+ (1,0) [0|1] "" Vector__XXX
 SG_ CC_a017_PilotCFault : 16|1@1+ (1,0) [0|1] "" Vector__XXX
 SG_ CC_a018_PilotDFault : 17|1@1+ (1,0) [0|1] "" Vector__XXX
 SG_ CC_a019_proxDisconnected : 18|1@1+ (1,0) [0|1] "" Vector__XXX
 SG_ CC_a020_3vRailIncorrect : 19|1@1+ (1,0) [0|1] "" Vector__XXX
 SG_ CC_a021_CB_noMaster : 20|1@1+ (1,0) [0|1] "" Vector__XXX
 SG_ CC_a022_CB_tooManyMasters : 21|1@1+ (1,0) [0|1] "" Vector__XXX
 SG_ CC_a023_CB_tooManySlaves : 22|1@1+ (1,0) [0|1] "" Vector__XXX
 SG_ CC_a024_CB_masterISetTooLow : 23|1@1+ (1,0) [0|1] "" Vector__XXX
 SG_ CC_a025_evseTemp : 24|1@1+ (1,0) [0|1] "" Vector__XXX
 SG_ CC_a026_wallPlugTemp : 25|1@1+ (1,0) [0|1] "" Vector__XXX
 SG_ CC_a027_vehicleHandleTemp : 26|1@1+ (1,0) [0|1] "" Vector__XXX
 SG_ CC_a028_CB_rotarySelect : 27|1@1+ (1,0) [0|1] "" Vector__XXX
 SG_ CC_a029_PilotFFault : 28|1@1+ (1,0) [0|1] "" Vector__XXX
 SG_ CC_a030_masterSlaveMismatch : 29|1@1+ (1,0) [0|1] "" Vector__XXX
 SG_ CC_a031_pllLockLost : 30|1@1+ (1,0) [0|1] "" Vector__XXX
 SG_ CC_a032_meteringFailure : 31|1@1+ (1,0) [0|1] "" Vector__XXX
 SG_ CC_a033_vRefOutOfRange : 32|1@1+ (1,0) [0|1] "" Vector__XXX
 SG_ CC_a034_bootAlert : 33|1@1+ (1,0) [0|1] "" Vector__XXX
 SG_ CC_a035_CCIDCalibration : 34|1@1+ (1,0) [0|1] "" Vector__XXX
 SG_ CC_a036_contactorStuckOpen : 35|1@1+ (1,0) [0|1] "" Vector__XXX
 SG_ CC_a037_internalModuleWatchdogEx : 36|1@1+ (1,0) [0|1] "" Vector__XXX
 SG_ CC_a038_internalModuleMia : 37|1@1+ (1,0) [0|1] "" Vector__XXX
 SG_ CC_a039_internalModuleOverTemp : 38|1@1+ (1,0) [0|1] "" Vector__XXX
 SG_ CC_a040_handleTempFoldback : 39|1@1+ (1,0) [0|1] "" Vector__XXX
 SG_ CC_a041_inputWiringFoldback : 40|1@1+ (1,0) [0|1] "" Vector__XXX
 SG_ CC_a042_pcbaTempFoldback : 41|1@1+ (1,0) [0|1] "" Vector__XXX
 SG_ CC_a043_configurationRequired : 42|1@1+ (1,0) [0|1] "" Vector__XXX
 SG_ CC_a044_relayCoilVoltageRational : 43|1@1+ (1,0) [0|1] "" Vector__XXX
 SG_ CC_a045_ACPowerLoss : 44|1@1+ (1,0) [0|1] "" Vector__XXX
 SG_ CC_a046_GFCIConfigInvalid : 45|1@1+ (1,0) [0|1] "" Vector__XXX
 SG_ CC_a047_MDMotorContFault : 46|1@1+ (1,0) [0|1] "" Vector__XXX
 SG_ CC_a048_ACMDAdapterFault : 47|1@1+ (1,0) [0|1] "" Vector__XXX
 SG_ CC_a049_rs485Fault : 48|1@1+ (1,0) [0|1] "" Vector__XXX
 SG_ CC_a050_eFuseFault : 49|1@1+ (1,0) [0|1] "" Vector__XXX
 SG_ CC_a051_chcCriticalFault : 50|1@1+ (1,0) [0|1] "" Vector__XXX
 SG_ CC_a052_vRefOutOfRangePWM : 51|1@1+ (1,0) [0|1] "" Vector__XXX
 SG_ CC_a057_chcVitalsRequestFailure : 56|1@1+ (1,0) [0|1] "" Vector__XXX
 SG_ CC_a060_persistenceFault : 59|1@1+ (1,0) [0|1] "" Vector__XXX
 SG_ CC_a061_unfinishedCommissioning : 60|1@1+ (1,0) [0|1] "" Vector__XXX

BO_ 796 CC_chgStatus: 8 CC
 SG_ CC_currentLimit : 0|8@1+ (0.5,0) [0|127] "A" Vector__XXX
 SG_ CC_pilotState : 8|2@1+ (1,0) [0|2] "" Vector__XXX
 SG_ CC_numPhases : 10|2@1+ (1,0) [1|3] "" Vector__XXX
 SG_ CC_line1Voltage : 16|9@1+ (1,0) [0|510] "V" Vector__XXX
 SG_ CC_gridGrounding : 26|2@1+ (1,0) [0|3] "" Vector__XXX
 SG_ CC_deltaTransformer : 28|2@1+ (1,0) [0|3] "" Vector__XXX
 SG_ CC_numVehCharging : 30|3@1+ (1,0) [0|7] "" Vector__XXX
 SG_ CC_line2Voltage : 33|9@1+ (1,0) [0|510] "V" Vector__XXX
 SG_ CC_line3Voltage : 42|9@1+ (1,0) [0|510] "V" Vector__XXX
 SG_ CC_groundResistance : 51|12@1+ (1,0) [0|4094] "kOhm" Vector__XXX

BO_ 797 CC_chgStatus2: 8 CC
 SG_ CC_chgStatus2Index M : 0|8@1+ (1,0) [0|255] "" Vector__XXX
 SG_ CC_buttonState m0 : 8|1@1+ (1,0) [0|1] "" Vector__XXX
 SG_ EVSE_v2xSupport m0 : 9|2@1+ (1,0) [0|3] "" Vector__XXX
 SG_ EVSE_v2xHandshakeStart m0 : 12|1@1+ (1,0) [0|1] "" Vector__XXX
 SG_ EVSE_v2xSessionType m0 : 13|2@1+ (1,0) [1|3] "" Vector__XXX

BO_ 812 CC_logData: 8 CC
 SG_ CC_logIndex M : 0|8@1+ (1,0) [0|255] "" Vector__XXX
 SG_ CC_activeConnectorID m0 : 8|8@1+ (1,0) [0|255] "" Vector__XXX
 SG_ CC_temperature1 m0 : 16|8@1- (1,88) [-40|215] "DegC" Vector__XXX
 SG_ CC_temperature2 m0 : 24|8@1- (1,88) [-40|215] "DegC" Vector__XXX
 SG_ CC_temperature3 m0 : 32|8@1- (1,88) [-40|215] "DegC" Vector__XXX
 SG_ CC_contactor1Closed m0 : 40|2@1+ (1,0) [0|3] "" Vector__XXX
 SG_ CC_contactor2Closed m0 : 42|2@1+ (1,0) [0|3] "" Vector__XXX
 SG_ CC_temperature4 m0 : 44|8@1- (1,88) [-40|215] "DegC" Vector__XXX
 SG_ CC_conn1Current m1 : 8|8@1+ (0.5,0) [0|127] "A" Vector__XXX
 SG_ CC_conn2Current m2 : 8|8@1+ (0.5,0) [0|127] "A" Vector__XXX
 SG_ CC_conn3Current m3 : 8|8@1+ (0.5,0) [0|127] "A" Vector__XXX
 SG_ CC_conn4Current m4 : 8|8@1+ (0.5,0) [0|127] "A" Vector__XXX
 SG_ CC_lifetimei2t m10 : 32|32@1+ (0.1,0) [0|429496729.5] "A2h" Vector__XXX
 SG_ CC_lifetimeCtrCycles m11 : 8|28@1+ (1,0) [0|268435455] "" Vector__XXX
 SG_ CC_lifetimeCtrCyclesLoaded m11 : 36|28@1+ (1,0) [0|268435455] "" Vector__XXX
 SG_ CC_lifetimeAlertCount m12 : 8|28@1+ (1,0) [0|268435455] "" Vector__XXX
 SG_ CC_lifetimeThermalFoldbacks m12 : 36|28@1+ (1,0) [0|268435455] "" Vector__XXX
 SG_ CC_lifetimeAvgStartupTemp m13 : 36|28@1- (0.1,0) [-13421772.8|13421772.7] "degC" Vector__XXX

BO_ 870 CMPD_info: 8 CMPD
 SG_ CMPD_infoIndex M : 0|8@1+ (1,0) [0|255] "" Vector__XXX
 SG_ CMPD_infoBuildType m10 : 8|8@1+ (1,0) [0|255] "" Vector__XXX
 SG_ CMPD_infoBuildConfigId m10 : 16|16@1+ (1,0) [0|65535] "" Vector__XXX
 SG_ CMPD_infoHardwareId m10 : 32|16@1+ (1,0) [0|65535] "" Vector__XXX
 SG_ CMPD_infoComponentId m10 : 48|16@1+ (1,0) [0|65535] "" Vector__XXX
 SG_ CMPD_infoPcbaId m11 : 16|8@1+ (1,0) [0|255] "" Vector__XXX
 SG_ CMPD_infoAssemblyId m11 : 24|8@1+ (1,0) [0|254] "" Vector__XXX
 SG_ CMPD_infoUsageId m11 : 32|16@1+ (1,0) [0|65535] "" Vector__XXX
 SG_ CMPD_infoSubUsageId m11 : 48|16@1+ (1,0) [0|65535] "" Vector__XXX

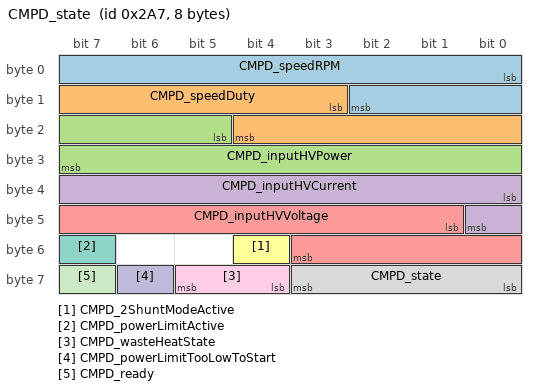
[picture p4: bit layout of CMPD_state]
BO_ 679 CMPD_state: 8 CMPD
 SG_ CMPD_speedRPM : 0|11@1+ (10,0) [0|20000] "RPM" Vector__XXX
 SG_ CMPD_speedDuty : 11|10@1+ (0.1,0) [0|100] "%" Vector__XXX
 SG_ CMPD_inputHVPower : 21|11@1+ (10,0) [0|20000] "W" Vector__XXX
 SG_ CMPD_inputHVCurrent : 32|9@1+ (0.1,0) [0|50] "A" Vector__XXX
 SG_ CMPD_inputHVVoltage : 41|11@1+ (0.5,0) [0|1000] "V" Vector__XXX
 SG_ CMPD_2ShuntModeActive : 52|1@1+ (1,0) [0|1] "" Vector__XXX
 SG_ CMPD_powerLimitActive : 55|1@1+ (1,0) [0|1] "" Vector__XXX
 SG_ CMPD_state : 56|4@1+ (1,0) [0|14] "" Vector__XXX
 SG_ CMPD_wasteHeatState : 60|2@1+ (1,0) [0|3] "" Vector__XXX
 SG_ CMPD_powerLimitTooLowToStart : 62|1@1+ (1,0) [0|1] "" Vector__XXX
 SG_ CMPD_ready : 63|1@1+ (1,0) [0|1] "" Vector__XXX

BO_ 1559 CMPD_udsResponse: 8 CMPD
 SG_ CMPD_udsResponseData : 7|64@0+ (1,0) [0|1.84467440737e+19] "" Vector__XXX

BO_ 867 CMP_info: 8 CMP
 SG_ CMP_infoIndex M : 0|8@1+ (1,0) [0|255] "" Vector__XXX
 SG_ CMP_infoBuildType m10 : 8|8@1+ (1,0) [0|255] "" Vector__XXX
 SG_ CMP_infoBuildConfigId m10 : 16|16@1+ (1,0) [0|65535] "" Vector__XXX
 SG_ CMP_infoHardwareId m10 : 32|16@1+ (1,0) [0|65535] "" Vector__XXX
 SG_ CMP_infoComponentId m10 : 48|16@1+ (1,0) [0|65535] "" Vector__XXX
 SG_ CMP_infoPcbaId m11 : 16|8@1+ (1,0) [0|255] "" Vector__XXX
 SG_ CMP_infoAssemblyId m11 : 24|8@1+ (1,0) [0|254] "" Vector__XXX
 SG_ CMP_infoUsageId m11 : 32|16@1+ (1,0) [0|65535] "" Vector__XXX
 SG_ CMP_infoSubUsageId m11 : 48|16@1+ (1,0) [0|65535] "" Vector__XXX
 SG_ CMP_infoPlatformType m13 : 8|8@1+ (1,0) [0|255] "" Vector__XXX
 SG_ CMP_infoAppCrc m13 : 32|32@1+ (1,0) [0|4294967295] "" Vector__XXX
 SG_ CMP_infoBootUdsProtoVersion m20 : 8|8@1+ (1,0) [0|255] "" Vector__XXX
 SG_ CMP_infoBootCrc m20 : 32|32@1+ (1,0) [0|4294967295] "" Vector__XXX

BO_ 1555 CMP_udsResponse: 8 CMP
 SG_ CMP_udsResponseData : 7|64@0+ (1,0) [0|1.84467440737e+19] "" Vector__XXX

BO_ 1767 CP_IsoTpPipeToPncd: 8 CP
 SG_ CP_isoTpToPncdData : 0|64@1+ (1,0) [0|1.84467440737e+19] "" Vector__XXX

BO_TX_BU_ 946 : BMS;
BO_TX_BU_ 914 : BMS;
BO_TX_BU_ 1810 : BMS;
BO_TX_BU_ 594 : BMS;
BO_TX_BU_ 674 : BMS;
BO_TX_BU_ 1834 : BMS;
BO_TX_BU_ 658 : BMS;
BO_TX_BU_ 1170 : BMS;
BO_TX_BU_ 530 : BMS;
BO_TX_BU_ 786 : BMS;
BO_TX_BU_ 1554 : BMS;
BO_TX_BU_ 1071 : BMS;
BO_TX_BU_ 754 : BMS;
BO_TX_BU_ 810 : BMS;
BO_TX_BU_ 1116 : CC;
BO_TX_BU_ 1132 : CC;
BO_TX_BU_ 796 : CC;
BO_TX_BU_ 797 : CC;
BO_TX_BU_ 812 : CC;
BO_TX_BU_ 870 : CMPD;
BO_TX_BU_ 679 : CMPD;
BO_TX_BU_ 1559 : CMPD;
BO_TX_BU_ 867 : CMP;
BO_TX_BU_ 1555 : CMP;
BO_TX_BU_ 1767 : CP;
CM_ BO_ 946 "High-voltage battery management system message: log2; frame length from the layout, not yet observed on a vehicle bus";
CM_ SG_ 946 BMS_log2MuxId "High-voltage battery management system: log2 mux id";
CM_ SG_ 946 BMS_maxChargeRestartNeededByVolt "High-voltage battery management system: max charge restart needed by voltage";
CM_ SG_ 946 BMS_cacAvg "BMS Calculated Ah Capacity (CAC). This is the average of all the brick CACs";
CM_ SG_ 946 BMS_maxChargeNearComplete "High-voltage battery management system: max charge near complete";
CM_ SG_ 946 BMS_cacMin "BMS Calculated Ah Capacity (CAC). This is the min of all the brick CACs";
CM_ SG_ 946 BMS_cacMinBrickId "High-voltage battery management system: cac min brick id";
CM_ SG_ 946 BMS_cacMax "BMS Calculated Ah Capacity (CAC). This is the max of all the brick CACs";
CM_ SG_ 946 BMS_cacMaxBrickId "High-voltage battery management system: cac max brick id";
CM_ SG_ 946 BMS_acRippleConfigNvramValid "High-voltage battery management system: ac ripple config nvram valid";
CM_ SG_ 946 BMS_hvChain_useLeakyBucket "Is the leaky bucket being used - an indicator of the HV Chain Model health";
CM_ SG_ 946 BMS_hvChain_iLimit "High-voltage battery management system: hv chain i limit; raw 16383 = signal not available (SNA)";
CM_ SG_ 946 BMS_hvChain_limitingState "High-voltage battery management system: hv chain limiting state; raw 511 = signal not available (SNA)";
CM_ SG_ 946 BMS_hvChain_limitingStateTempera "High-voltage battery management system: hv chain limiting state temperature; raw 4096 = signal not available (SNA)";
CM_ SG_ 946 BMS_acRippleIsSupported "High-voltage battery management system: ac ripple is supported";
CM_ SG_ 946 BMS_acRippleStartTemperatureMax "High-voltage battery management system: ac ripple start temperature max";
CM_ SG_ 946 BMS_acRippleStartTemperatureMin "High-voltage battery management system: ac ripple start temperature min";
CM_ SG_ 946 BMS_fcLinkTestDecayTime "High-voltage battery management system: fc link test decay time; raw 1023 = signal not available (SNA)";
CM_ SG_ 946 BMS_fcLinkTestTimeSinceLastRun "High-voltage battery management system: fc link test time since last run";
CM_ SG_ 946 BMS_pcsPrechargeRequest "Enum indicating the active precharge request type from BMS to PCS";
CM_ SG_ 946 BMS_pcsPrechargeTargetVoltage "Target voltage for precharging HV bus";
CM_ SG_ 946 BMS_recentOvUvAlert "At least one of the Brick OV or UV alerts has been active recently; consumed by BMS_a049_SW_Thermal_Event set condition";
CM_ SG_ 946 BMS_recentIsoAlert "At least one of the isolation alerts has been active recently; consumed by BMS_a049_SW_Thermal_Event set condition";
CM_ SG_ 946 BMS_recentBmbMiaAlert "At least one of the BMB communication alerts has been active recently; consumed by BMS_a049_SW_Thermal_Event set condition";
CM_ SG_ 946 BMS_cacBlendingConfigNvramValid "High-voltage battery management system: cac blending config nvram valid";
CM_ SG_ 946 BMS_cacBlendingEnabled "High-voltage battery management system: cac blending enabled";
CM_ SG_ 946 BMS_cacBlendPercentPerCycle "High-voltage battery management system: cac blend percent per cycle";
CM_ SG_ 946 BMS_energyVariableChgRequested "High-voltage battery management system: energy variable chg requested";
CM_ SG_ 946 BMS_packRestTime "Minimum resting time of all bricks";
CM_ SG_ 946 BMS_idealEnergyFloor "Ideal energy estimate based on the min bounded SOC that accounts for accumulated shunt error; raw 1023 = signal not available (SNA)";
CM_ SG_ 946 BMS_thmGradientSlopeCondition "High-voltage battery management system: thm gradient slope condition";
CM_ SG_ 946 BMS_recentSlopeConditon "High-voltage battery management system: recent slope conditon";
CM_ SG_ 946 BMS_dynamicEnergyBuffer "BMS estimate of energy error based on SOC measurement inaccuracy; raw 1023 = signal not available (SNA)";
CM_ SG_ 946 BMS_temperatureCondition "High-voltage battery management system: temperature condition";
CM_ SG_ 946 BMS_thmGradientSlope "High-voltage battery management system: thm gradient slope";
CM_ SG_ 946 BMS_thmGradient "High-voltage battery management system: thm gradient";
CM_ SG_ 946 BMS_epochTimeEstimate "High-voltage battery management system: epoch time estimate";
CM_ SG_ 946 BMS_histogramStartTimeIrrational "High-voltage battery management system: histogram start time irrational";
CM_ SG_ 946 BMS_histogramDischargeThroughput "High-voltage battery management system: histogram discharge throughput irrational";
CM_ SG_ 946 BMS_histogramChargeThroughputIrr "High-voltage battery management system: histogram charge throughput irrational";
CM_ SG_ 946 BMS_histogramTotalTimeIrrational "High-voltage battery management system: histogram total time irrational";
CM_ SG_ 946 BMS_histogramStorageDataIsLow "High-voltage battery management system: histogram storage data is low";
CM_ SG_ 946 BMS_tempVsSocTotalChgEnergy "High-voltage battery management system: temp vs soc total chg energy";
CM_ SG_ 946 BMS_powerVsVoltageTotalChgEnergy "High-voltage battery management system: power vs voltage total chg energy";
CM_ SG_ 946 BMS_lifeModelOutputsAreTrustwort "High-voltage battery management system: life model outputs are trustworthy";
CM_ SG_ 946 BMS_dSocNormalizedMin "High-voltage battery management system: d soc normalized min; raw 4095 = signal not available (SNA)";
CM_ SG_ 946 BMS_dSocNormalizedFiltMin "High-voltage battery management system: d soc normalized filt min; raw 4095 = signal not available (SNA)";
CM_ SG_ 946 BMS_dSocMinAlpha "minimum calculated alpha value across all bricks and all dSOC calculations; raw 4095 = signal not available (SNA)";
CM_ SG_ 946 BMS_dSocMaxLowAlphaCounter "High-voltage battery management system: d soc max low alpha counter";
CM_ SG_ 946 BMS_dSocMinAlphaBrickID "High-voltage battery management system: d soc min alpha brick ID";
CM_ SG_ 946 BMS_dSocCacMargin "High-voltage battery management system: d soc cac margin; raw 511 = signal not available (SNA)";
CM_ SG_ 946 BMS_lifeModelNoCurrentStorageCap "High-voltage battery management system: life model no current storage capacity loss; raw 511 = signal not available (SNA)";
CM_ SG_ 946 BMS_lifeModelShortDcr "High-voltage battery management system: life model short dcr; raw 255 = signal not available (SNA)";
CM_ SG_ 946 BMS_lifeModelLongDcr "High-voltage battery management system: life model long dcr; raw 4096 = signal not available (SNA)";
CM_ SG_ 946 BMS_lifeModelStorageCapacityLoss "High-voltage battery management system: life model storage capacity loss; raw 511 = signal not available (SNA)";
CM_ SG_ 946 BMS_lifeModelThroughputCapacityL "High-voltage battery management system: life model throughput capacity loss; raw 511 = signal not available (SNA)";
CM_ SG_ 946 BMS_passiveCoolCellTargetT "High-voltage battery management system: passive cool cell target t";
CM_ SG_ 946 BMS_lifeModelAvgTempSeverity "High-voltage battery management system: life model avg temp severity; raw 31 = signal not available (SNA)";
CM_ SG_ 946 BMS_lifeModelDepthOfDischargeSev "High-voltage battery management system: life model depth of discharge severity; raw 255 = signal not available (SNA)";
CM_ SG_ 946 BMS_lifeModelHistogramCapacityLo "High-voltage battery management system: life model histogram capacity loss; raw 511 = signal not available (SNA)";
CM_ SG_ 946 BMS_lifeModelHistogramBrickCapac "High-voltage battery management system: life model histogram brick capacity; raw 8191 = signal not available (SNA)";
CM_ SG_ 946 BMS_lifeModelDcrGrowthPercent "High-voltage battery management system: life model dcr growth percent; raw 8192 = signal not available (SNA)";
CM_ SG_ 946 BMS_nominalFullPackEnergyRaw "Non-latched version of BMS_nominalEnergyRemaining; raw 65535 = signal not available (SNA)";
CM_ SG_ 946 BMS_nominalEnergyRemainingBuffer "Buffered version of BMS_nominalEnergyRemaining; raw 65535 = signal not available (SNA)";
CM_ SG_ 946 BMS_idealEnergyRemainingBuffered "Buffered version of BMS_idealEnergyRemaining; raw 65535 = signal not available (SNA)";
CM_ SG_ 946 BMS_largestSynchronizedCacErrorP "High-voltage battery management system: largest synchronized cac error pct; raw 255 = signal not available (SNA)";
CM_ SG_ 946 BMS_lifeModelSpreadMinOffset "High-voltage battery management system: life model spread min offset";
CM_ SG_ 946 BMS_lifeModelSpreadMaxOffset "High-voltage battery management system: life model spread max offset";
CM_ SG_ 946 BMS_largestCacSpreadErrorLower "High-voltage battery management system: largest cac spread error lower; raw 4095 = signal not available (SNA)";
CM_ SG_ 946 BMS_lifeModelAverageCac "High-voltage battery management system: life model average cac; raw 4095 = signal not available (SNA)";
CM_ SG_ 946 BMS_lifeModelCacBrick1 "High-voltage battery management system: life model cac brick1; raw 4095 = signal not available (SNA)";
CM_ SG_ 946 BMS_lifeModelAverageOffset "High-voltage battery management system: life model average offset; raw 512 = signal not available (SNA)";
CM_ SG_ 946 BMS_percentCacUpdatesInTimeWindo "High-voltage battery management system: percent cac updates in time window";
CM_ SG_ 946 BMS_lifeModelMaxCacBrickId "High-voltage battery management system: life model max cac brick id; raw 255 = signal not available (SNA)";
CM_ SG_ 946 BMS_lifeModelMaxCac "High-voltage battery management system: life model max cac; raw 4095 = signal not available (SNA)";
CM_ SG_ 946 BMS_lifeModelMinCacBrickId "High-voltage battery management system: life model min cac brick id; raw 255 = signal not available (SNA)";
CM_ SG_ 946 BMS_lifeModelMinCac "High-voltage battery management system: life model min cac; raw 4095 = signal not available (SNA)";
CM_ SG_ 946 BMS_restingPointCacAvg "High-voltage battery management system: resting point cac avg; raw 4095 = signal not available (SNA)";
CM_ SG_ 946 BMS_cacEstimationSource "High-voltage battery management system: cac estimation source";
CM_ SG_ 946 BMS_packCalibrationBirthDateBinn "High-voltage battery management system: pack calibration birth date binned";
CM_ SG_ 946 BMS_synchronizedCacMaxRaw "High-voltage battery management system: synchronized cac max raw; raw 4095 = signal not available (SNA)";
CM_ SG_ 946 BMS_synchronizedCacMinRaw "High-voltage battery management system: synchronized cac min raw; raw 4095 = signal not available (SNA)";
CM_ SG_ 946 BMS_largestSyncCacErrorStartSoc "Start SOC for CAC update from the brick with the highest synchronized CAC error";
CM_ SG_ 946 BMS_largestSyncCacErrorEndSoc "Start SOC for CAC update from the brick with the highest synchronized CAC error";
CM_ SG_ 946 BMS_runtimeSocConfigNvramValid "High-voltage battery management system: runtime soc config nvram valid";
CM_ SG_ 946 BMS_runtimeSocCorrectionsEnabled "High-voltage battery management system: runtime soc corrections enabled";
CM_ SG_ 946 BMS_rubberBandingEnabled "Reports whether rubber banding of output energy corrections is enabled.";
CM_ SG_ 946 BMS_rubberBandingConfigNvramVali "High-voltage battery management system: rubber banding config nvram valid";
CM_ SG_ 946 BMS_runtimeSocMinTempForModel "High-voltage battery management system: runtime soc min temp for model";
CM_ SG_ 946 BMS_energyBufferConfigNvramValid "High-voltage battery management system: energy buffer config nvram valid";
CM_ SG_ 946 BMS_thermalEvent1pDetectConfigDi "High-voltage battery management system: thermal event1p detect config disabled";
CM_ SG_ 946 BMS_sohEnergy "Battery SOH energy estimate. If calibrated SOH capacity is unavailable, this value is a filtered result from brick CACs; raw 2047 = signal not available (SNA)";
CM_ SG_ 946 BMS_fullCapacitySohEnergy "Energy estimate using nominal brick capacity at maximum SOC using SOH retention test conditions; raw 2047 = signal not available (SNA)";
CM_ SG_ 946 BMS_calibratedCapacitySohEnergy "Energy estimate using CAC from the most recent valid SOH test at maximum SOC using SOH retention test conditions; raw 2047 = signal not available (SNA)";
CM_ SG_ 946 BMS_estimatedCapacitySohEnergy "Energy estimate using filtered brick capacities at maximum SOC using SOH retention test conditions; raw 2047 = signal not available (SNA)";
CM_ SG_ 946 BMS_prevUserFacingSohEnergy "The last soh energy stored in NVM for rate limiting purposes; raw 2047 = signal not available (SNA)";
CM_ SG_ 946 BMS_stateOfHealthMinCac "Reports the minimum Calculated Amp-hour Capacity (CAC) by aged Open Circuit Voltage (OCV) raw values across bricks that could be used in State of Health (SOH) calculations; raw 8191 = signal not available (SNA)";
CM_ SG_ 946 BMS_lifeModelStorageLossPackAge "High-voltage battery management system: life model storage loss pack age; raw 16383 = signal not available (SNA)";
CM_ SG_ 946 BMS_lifeModelThroughputDcrCycleC "High-voltage battery management system: life model throughput dcr cycle count; raw 4095 = signal not available (SNA)";
CM_ SG_ 946 BMS_stateOfHealthMinCacLowerBoun "Reports the minimum Calculated Amp-hour Capacity (CAC) by aged Open Circuit Voltage (OCV) raw lower bound values across bricks that could be used in State of Health (SOH) calculations; raw 8191 = signal not available (SNA)";
CM_ SG_ 946 BMS_energyWalkCounter "High-voltage battery management system: energy walk counter";
CM_ SG_ 946 BMS_energyWalkTimeoutCounter "High-voltage battery management system: energy walk timeout counter";
CM_ SG_ 946 BMS_dynamicCcvEnabled "High-voltage battery management system: dynamic ccv enabled";
CM_ SG_ 946 BMS_chargeTargetLookupSoc "High-voltage battery management system: charge target lookup soc";
CM_ SG_ 946 BMS_stateOfHealth "Most recent battery capacity estimate, from a successful SOH test in %; raw 1023 = signal not available (SNA)";
CM_ SG_ 946 BMS_avgShuntAsicCurrentOffset "High-voltage battery management system: avg shunt asic current offset; raw 16384 = signal not available (SNA)";
CM_ SG_ 946 BMS_cellAttributesGeneralAttribu "High-voltage battery management system: cell attributes general attributes; raw 0 = signal not available (SNA)";
CM_ SG_ 946 BMS_cellAttributesPackManufactur "High-voltage battery management system: cell attributes pack manufacturing location; raw 0 = signal not available (SNA)";
CM_ SG_ 946 BMS_cellAttributesRemanufactured "High-voltage battery management system: cell attributes remanufactured pack";
CM_ SG_ 946 BMS_cellAttributesConfigNvramVal "High-voltage battery management system: cell attributes config nvram valid";
CM_ SG_ 946 BMS_cellAttributesCellType "High-voltage battery management system: cell attributes cell type; raw 0 = signal not available (SNA)";
CM_ SG_ 946 BMS_cellAttributesAutocloseAndSc "High-voltage battery management system: cell attributes autoclose and scrap pack on field return";
CM_ SG_ 946 BMS_cellAttributesShipPackForFai "High-voltage battery management system: cell attributes ship pack for failure analysis";
CM_ SG_ 946 BMS_lifeModelThroughputCycleCoun "High-voltage battery management system: life model throughput cycle count; raw 4095 = signal not available (SNA)";
CM_ SG_ 946 BMS_limpChargeCurrentLimit "DC current limit based on limp mode; raw 1023 = signal not available (SNA)";
CM_ SG_ 946 BMS_energyRemainingDisplayError "High-voltage battery management system: energy remaining display error";
CM_ SG_ 946 BMS_energyRemainingTDisplayError "High-voltage battery management system: energy remaining t display error";
CM_ SG_ 946 BMS_numOfThermistors "Measures the number of thermistors in the battery pack for temperature monitoring.";
CM_ SG_ 946 BMS_numOfBricks "Measures the number of battery bricks (modules or cell groups) in the pack.";
CM_ SG_ 946 BMS_cellChargeDcCurrentLimit "DC current target based on cell voltage & temp tables";
CM_ SG_ 946 BMS_socByDeltaVEnabled "High-voltage battery management system: soc by delta v enabled";
CM_ SG_ 946 BMS_socByDvMaxSocLimit "High-voltage battery management system: soc by dv max soc limit";
CM_ SG_ 946 BMS_socByDvVoltageChangeOverAh "High-voltage battery management system: soc by dv voltage change over ah";
CM_ SG_ 946 BMS_socByDvMaxSocByAhCorrected "High-voltage battery management system: soc by dv max soc by ah corrected";
CM_ SG_ 946 BMS_socByDvMaxBrickVoltage "High-voltage battery management system: soc by dv max brick voltage";
CM_ SG_ 946 BMS_socByDvMaxBrickId "High-voltage battery management system: soc by dv max brick id";
CM_ SG_ 946 BMS_socByDvMaxSocByAhRaw "High-voltage battery management system: soc by dv max soc by ah raw";
CM_ SG_ 946 BMS_voltageInstabilityExcessNois "High-voltage battery management system: voltage instability excess noise log";
CM_ SG_ 946 BMS_maxModelThermistorTempDelta "High-voltage battery management system: max model thermistor temp delta; raw 512 = signal not available (SNA)";
CM_ SG_ 946 BMS_activeCoolCellTargetT "High-voltage battery management system: active cool cell target t";
CM_ SG_ 946 BMS_cellTempTargetMode "Operating mode of the thermal controls for the Battery Management System (BMS)";
CM_ SG_ 946 BMS_minPackTempForChargeToStart "High-voltage battery management system: min pack temp for charge to start";
CM_ BO_ 914 "High-voltage battery management system message: pack config; frame length from the layout, not yet observed on a vehicle bus";
CM_ SG_ 914 BMS_packConfigMultiplexer "High-voltage battery management system: pack config multiplexer";
CM_ SG_ 914 BMS_reservedConfig_0 "High-voltage battery management system: reserved config 0";
CM_ SG_ 914 BMS_moduleType "High-voltage battery management system: module type";
CM_ SG_ 914 BMS_thermalPackType "High-voltage battery management system: thermal pack type";
CM_ SG_ 914 BMS_packMass "High-voltage battery management system: pack mass";
CM_ SG_ 914 BMS_platformMaxBusVoltage "High-voltage battery management system: platform max bus voltage";
CM_ SG_ 914 BMS_standbySupplyContinuousPower "High-voltage battery management system: standby supply continuous power limit";
CM_ SG_ 914 BMS_beginningOfLifePackEnergy "High-voltage battery management system: beginning of life pack energy; raw 1023 = signal not available (SNA)";
CM_ BO_ 1810 "High-voltage battery management system message: pack temperature measurements; frame length from the layout, not yet observed on a vehicle bus";
CM_ SG_ 1810 BMS_packTemperatureMultiplexer "High-voltage battery management system: pack temperature multiplexer";
CM_ SG_ 1810 BMS_packTemperatureCounter "High-voltage battery management system: pack temperature counter";
CM_ SG_ 1810 BMS_packTemperatureStatus1 "High-voltage battery management system: pack temperature status1";
CM_ SG_ 1810 BMS_packTemperatureStatus2 "High-voltage battery management system: pack temperature status2";
CM_ SG_ 1810 BMS_packTemperatureStatus3 "High-voltage battery management system: pack temperature status3";
CM_ SG_ 1810 BMS_packTemperature1 "Measured temperature of location within the pack";
CM_ SG_ 1810 BMS_packTemperature2 "Measured temperature of location within the pack";
CM_ SG_ 1810 BMS_packTemperature3 "Measured temperature of location within the pack";
CM_ SG_ 1810 BMS_packTemperatureStatus4 "High-voltage battery management system: pack temperature status4";
CM_ SG_ 1810 BMS_packTemperatureStatus5 "High-voltage battery management system: pack temperature status5";
CM_ SG_ 1810 BMS_packTemperatureStatus6 "High-voltage battery management system: pack temperature status6";
CM_ SG_ 1810 BMS_packTemperature4 "Measured temperature of location within the pack";
CM_ SG_ 1810 BMS_packTemperature5 "Measured temperature of location within the pack";
CM_ SG_ 1810 BMS_packTemperature6 "Measured temperature of location within the pack";
CM_ SG_ 1810 BMS_packTemperatureStatus7 "High-voltage battery management system: pack temperature status7";
CM_ SG_ 1810 BMS_packTemperatureStatus8 "High-voltage battery management system: pack temperature status8";
CM_ SG_ 1810 BMS_packTemperatureStatus9 "High-voltage battery management system: pack temperature status9";
CM_ SG_ 1810 BMS_packTemperature7 "Measured temperature of location within the pack";
CM_ SG_ 1810 BMS_packTemperature8 "Measured temperature of location within the pack";
CM_ SG_ 1810 BMS_packTemperature9 "Measured temperature of location within the pack";
CM_ SG_ 1810 BMS_packTemperatureStatus10 "High-voltage battery management system: pack temperature status10";
CM_ SG_ 1810 BMS_packTemperatureStatus11 "High-voltage battery management system: pack temperature status11";
CM_ SG_ 1810 BMS_packTemperatureStatus12 "High-voltage battery management system: pack temperature status12";
CM_ SG_ 1810 BMS_packTemperature10 "Measured temperature of location within the pack";
CM_ SG_ 1810 BMS_packTemperature11 "Measured temperature of location within the pack";
CM_ SG_ 1810 BMS_packTemperature12 "Measured temperature of location within the pack";
CM_ SG_ 1810 BMS_packTemperatureStatus13 "High-voltage battery management system: pack temperature status13";
CM_ SG_ 1810 BMS_packTemperatureStatus14 "High-voltage battery management system: pack temperature status14";
CM_ SG_ 1810 BMS_packTemperatureStatus15 "High-voltage battery management system: pack temperature status15";
CM_ SG_ 1810 BMS_packTemperature13 "Measured temperature of location within the pack";
CM_ SG_ 1810 BMS_packTemperature14 "Measured temperature of location within the pack";
CM_ SG_ 1810 BMS_packTemperature15 "Measured temperature of location within the pack";
CM_ SG_ 1810 BMS_packTemperatureStatus16 "High-voltage battery management system: pack temperature status16";
CM_ SG_ 1810 BMS_packTemperatureStatus17 "High-voltage battery management system: pack temperature status17";
CM_ SG_ 1810 BMS_packTemperatureStatus18 "High-voltage battery management system: pack temperature status18";
CM_ SG_ 1810 BMS_packTemperature16 "Measured temperature of location within the pack";
CM_ SG_ 1810 BMS_packTemperature17 "Measured temperature of location within the pack";
CM_ SG_ 1810 BMS_packTemperature18 "Measured temperature of location within the pack";
CM_ BO_ 594 "High-voltage battery management system message: power available; frame length from the layout, not yet observed on a vehicle bus";
CM_ SG_ 594 BMS_maxRegenPower "Calculated max regen power";
CM_ SG_ 594 BMS_maxDischargePower "Calculated max discharge power possible based on max discharge current and sum of loaded voltages";
CM_ SG_ 594 BMS_maxStationaryHeatPower "Maximum heating power the DI can produce when in stationary heating mode";
CM_ SG_ 594 BMS_powerLimitsState "High-voltage battery management system: power limits state";
CM_ SG_ 594 BMS_totalHvPowerBudget "Maximum total power that the High Voltage (HV) battery and Electric Vehicle Supply Equipment (EVSE) (if present) can safely produce";
CM_ SG_ 594 BMS_notEnoughPowerForHeatPump "Flag indicating the min pack power is lower than specified threshold to support heating with the heat pump";
CM_ BO_ 674 "High-voltage battery management system message: ripple request; frame length from the layout, not yet observed on a vehicle bus";
CM_ SG_ 674 BMS_acRippleCurrentAmplitudeLimi "Transmits the Battery Management System (BMS) AC ripple current amplitude limit to the Electric Vehicle Supply Equipment (EVSE).";
CM_ SG_ 674 BMS_acRippleMaxVoltageLimit "Reports the maximum voltage limit when the Electric Vehicle Supply Equipment (EVSE) is performing the AC ripple.";
CM_ SG_ 674 BMS_acRippleMinVoltageLimit "Reports the minimum voltage limit when the Electric Vehicle Supply Equipment (EVSE) is performing the AC ripple.";
CM_ SG_ 674 BMS_acRippleFrequencyRequest "Transmits the Battery Management System (BMS) AC ripple frequency request to the Electric Vehicle Supply Equipment (EVSE); raw 1023 = signal not available (SNA)";
CM_ SG_ 674 BMS_acRippleCurrentAmplitudeRequ "Transmits the Battery Management System (BMS) AC ripple current amplitude request to the Electric Vehicle Supply Equipment (EVSE).";
CM_ SG_ 674 BMS_acRippleRequest "High-voltage battery management system: ac ripple request";
CM_ BO_ 1834 "High-voltage battery management system message: serial number; frame length from the layout, not yet observed on a vehicle bus";
CM_ SG_ 1834 BMS_serialNumberMultiplexer "High-voltage battery management system: serial number multiplexer";
CM_ SG_ 1834 BMS_packSerialNumberByte01 "Pack serial number, character 1 (ASCII)";
CM_ SG_ 1834 BMS_packSerialNumberByte02 "Pack serial number, character 2 (ASCII)";
CM_ SG_ 1834 BMS_packSerialNumberByte03 "Pack serial number, character 3 (ASCII)";
CM_ SG_ 1834 BMS_packSerialNumberByte04 "Pack serial number, character 4 (ASCII)";
CM_ SG_ 1834 BMS_packSerialNumberByte05 "Pack serial number, character 5 (ASCII)";
CM_ SG_ 1834 BMS_packSerialNumberByte06 "Pack serial number, character 6 (ASCII)";
CM_ SG_ 1834 BMS_packSerialNumberByte07 "Pack serial number, character 7 (ASCII)";
CM_ SG_ 1834 BMS_packSerialNumberByte08 "Pack serial number, character 8 (ASCII)";
CM_ SG_ 1834 BMS_packSerialNumberByte09 "Pack serial number, character 9 (ASCII)";
CM_ SG_ 1834 BMS_packSerialNumberByte10 "Pack serial number, character 10 (ASCII)";
CM_ SG_ 1834 BMS_packSerialNumberByte11 "Pack serial number, character 11 (ASCII)";
CM_ SG_ 1834 BMS_packSerialNumberByte12 "Pack serial number, character 12 (ASCII)";
CM_ SG_ 1834 BMS_packSerialNumberByte13 "Pack serial number, character 13 (ASCII)";
CM_ SG_ 1834 BMS_packSerialNumberByte14 "Pack serial number, character 14 (ASCII)";
CM_ SG_ 1834 BMS_packSerialBirthDateBinned "High-voltage battery management system: pack serial birth date binned";
CM_ BO_ 658 "High-voltage battery management system message: soc status; frame length from the layout, not yet observed on a vehicle bus";
CM_ SG_ 658 BMS_socMin "BMS State Of Charge (SOC). This is the minimum brick SOC.";
CM_ SG_ 658 BMS_socUI "BMS State Of Energy (SOE) for the UI. This is ideal discharge energy from present state / ideal discharge energy from full.";
CM_ SG_ 658 BMS_socMax "BMS State Of Charge (SOC). This is the maximum brick SOC.";
CM_ SG_ 658 BMS_socAvg "BMS State Of Charge (SOC). This is the average of all the brick SOCs";
CM_ SG_ 658 BMS_enoughEnergyForConvenienceFe "Flag to indicate if there is enough energy for user facing features that are function of the UI discharge limit";
CM_ SG_ 658 BMS_instantChargePowerCapability "Indicates the instantaneous charge power capability of the high voltage battery; raw 65535 = signal not available (SNA)";
CM_ BO_ 1170 "High-voltage battery management system message: state of health; frame length from the layout, not yet observed on a vehicle bus";
CM_ SG_ 1170 BMS_sohEnergyPercent "Estimate of battery SOH Energy % based on the most accurate capacity estimates the BMS has available; raw 1023 = signal not available (SNA)";
CM_ SG_ 1170 BMS_userFacingSohTestState "High-voltage battery management system: user facing soh test state";
CM_ SG_ 1170 BMS_userFacingSohTestEndMode "High-voltage battery management system: user facing soh test end mode";
CM_ SG_ 1170 BMS_timeSinceSohUpdate "Days since last successful SOH test; raw 4095 = signal not available (SNA)";
CM_ SG_ 1170 BMS_sohTestCycleFlag "Flag that is True from the start of an SOH test until it ends and all relevant signals have been logged";
CM_ SG_ 1170 BMS_sohTestIsBlocked "High-voltage battery management system: soh test is blocked";
CM_ SG_ 1170 BMS_calibratedSohAvailable "SOH Energy is based on valid results from the SOH capacity test";
CM_ SG_ 1170 BMS_requiredEvsePowerForSoh "High-voltage battery management system: required evse power for soh; raw 255 = signal not available (SNA)";
CM_ SG_ 1170 BMS_distanceSinceSohUpdate "Distance since the last State of Health update in km; raw 65535 = signal not available (SNA)";
CM_ BO_ 530 "High-voltage battery management system message: status; frame length from the layout, not yet observed on a vehicle bus";
CM_ SG_ 530 BMS_hvacPowerRequest "High-voltage battery management system: hvac power request";
CM_ SG_ 530 BMS_notEnoughPowerForDrive "Flag indicating the min pack power is lower than specified threshold to support drive";
CM_ SG_ 530 BMS_notEnoughPowerForSupport "Flag indicating if the system can support a new request for 12V battery support";
CM_ SG_ 530 BMS_preconditionAllowed "High-voltage battery management system: precondition allowed";
CM_ SG_ 530 BMS_updateAllowed "High-voltage battery management system: update allowed";
CM_ SG_ 530 BMS_cpMiaOnHvs "Flag indicating that BMS is no longer receiving comms from CP on HVS bus";
CM_ SG_ 530 BMS_pcsPwmEnabled "Reports the state of the PCS_PWM_ENABLE input on the HVBMS, which is derived from the P1-12-DCDC-ENABLE input, which comes from VCFRONT";
CM_ SG_ 530 BMS_contactorState "BMS Contactor Status; raw 0 = signal not available (SNA)";
CM_ SG_ 530 BMS_userChargeStatus "BMS charge status for UI display. Renamed from BMS_uiChargeStatus";
CM_ SG_ 530 BMS_batteryInputPower "High-voltage battery management system: battery input power; raw 65535 = signal not available (SNA)";
CM_ SG_ 530 BMS_chargeRequest "Indicates charge is available and charge is desired";
CM_ SG_ 530 BMS_state "BMS operating state; raw 9 = signal not available (SNA)";
CM_ SG_ 530 BMS_diLimpRequest "BMS request to DI to enter limp mode";
CM_ SG_ 530 BMS_okToShipByAir "High-voltage battery management system: ok to ship by air";
CM_ SG_ 530 BMS_okToShipByLand "High-voltage battery management system: ok to ship by land";
CM_ SG_ 530 BMS_chgPowerAvailable "BMS available charge power; raw 4095 = signal not available (SNA)";
CM_ SG_ 530 BMS_acManagerState "High-voltage battery management system: ac manager state";
CM_ SG_ 530 BMS_conditioningRequest "BMS request to enable conditioning so it can attempt FEIM recovery";
CM_ SG_ 530 BMS_smStateRequest "BMS high level state request; raw 9 = signal not available (SNA)";
CM_ SG_ 530 BMS_hvState "BMS high voltage state";
CM_ BO_ 786 "High-voltage battery management system message: thermal status; frame length from the layout, not yet observed on a vehicle bus";
CM_ SG_ 786 BMS_thermalStatusMultiplexer "High-voltage battery management system: thermal status multiplexer";
CM_ SG_ 786 BMS_inletActiveCoolTargetT "Calculated active cooling temperature target at the inlet";
CM_ SG_ 786 BMS_inletPassiveTargetT "Calculated passive temperature target at the inlet";
CM_ SG_ 786 BMS_inletActiveHeatTargetT "Calculated active heating temperature target at the inlet";
CM_ SG_ 786 BMS_requestDischarge "Flag identifying when the Battery Management System (BMS) is requesting the battery pack to be discharged";
CM_ SG_ 786 BMS_activeHeatingWorthwhile "Determination by the Battery Management System (BMS) if active heating is worthwhile";
CM_ SG_ 786 BMS_pcsNoFlowRequest "High-voltage battery management system: pcs no flow request";
CM_ SG_ 786 BMS_minPackTemperature "Minimum pack temperature for consumption by external entities";
CM_ SG_ 786 BMS_noFlowRequest "High-voltage battery management system: no flow request";
CM_ SG_ 786 BMS_maxPackTemperature "Maximum pack temperature for consumption by external entities";
CM_ SG_ 786 BMS_flowRequest "Requested coolant flow rate in liters per minute (LPM) from the Battery Management System (BMS) to the thermal module";
CM_ SG_ 786 BMS_coldStagnationLimit "Minimum temperature at which the pack is allowed to be used as a heat-energy source";
CM_ SG_ 786 BMS_hotStagnationLimit "Maximum temperature at which we allow the pack to be used for heat-energy storage";
CM_ SG_ 786 BMS_hotCellTempLimit "Maximum temperature at which the pack will allow limp mode levels of current";
CM_ SG_ 786 BMS_i2tDeratingEnabled "High-voltage battery management system: i2t derating enabled";
CM_ SG_ 786 BMS_activeCoolCellReferenceT "Desired cell temperature reference which composes the temperature trajectory portion of the active cooling target temperature controls";
CM_ SG_ 786 BMS_activeHeatCellTargetT "Desired cell temperature which feeds as an input to the active heating target temperature, before any additional controls calculations";
CM_ SG_ 786 BMS_powerDissipation "High-voltage battery management system: power dissipation";
CM_ BO_ 1554 "High-voltage battery management system message: uds response; frame length from the layout, not yet observed on a vehicle bus";
CM_ SG_ 1554 BMS_udsResponseData "High-voltage battery management system: uds response data";
CM_ BO_ 1071 "High-voltage battery management system message: v2x info; frame length from the layout, not yet observed on a vehicle bus";
CM_ SG_ 1071 BMS_v2xSoe "High-voltage battery management system: v2x soe; raw 65535 = signal not available (SNA)";
CM_ SG_ 1071 BMS_v2xFullEnergy "High-voltage battery management system: v2x full energy; raw 4095 = signal not available (SNA)";
CM_ SG_ 1071 BMS_v2xPackPower "High-voltage battery management system: v2x pack power; raw 511 = signal not available (SNA)";
CM_ SG_ 1071 BMS_acDischargeBlockedReason "The enumerated reason why the ECU is blocking AC discharge";
CM_ SG_ 1071 BMS_backupTimeRemaining "High-voltage battery management system: backup time remaining; raw 255 = signal not available (SNA)";
CM_ BO_ 754 "High-voltage battery management system message: veh nm; frame length from the layout, not yet observed on a vehicle bus";
CM_ SG_ 754 BMS_nmGoingToSleep "High-voltage battery management system: nm going to sleep";
CM_ SG_ 754 BMS_nmWakeUpBus "High-voltage battery management system: nm wake up bus";
CM_ SG_ 754 BMS_hvsBusAsleep "HVS bus reported as off";
CM_ SG_ 754 BMS_nmKeepAwakeReason "BMS' determined reason to keep CAN awake; raw 0 = signal not available (SNA)";
CM_ SG_ 754 BMS_nmWakeUpReason "BMS' determined reason to wake up CAN";
CM_ BO_ 810 "High-voltage battery management system message: vehicle notifications; frame length from the layout, not yet observed on a vehicle bus";
CM_ SG_ 810 BMS_thermalEventSuspected "Indicates the Battery Management System (BMS) has detected conditions that reflect a possible battery thermal event";
CM_ SG_ 810 BMS_vehicleNotificationsCounter "High-voltage battery management system: vehicle notifications counter";
CM_ SG_ 810 BMS_isolationResistance "Resistance between HV bus and chassis; raw 1023 = signal not available (SNA)";
CM_ SG_ 810 BMS_chgTimeToFull "Estimated time remaining until charge termination percent will be reached; raw 4095 = signal not available (SNA)";
CM_ SG_ 810 BMS_vehicleNotificationsChecksum "High-voltage battery management system: vehicle notifications checksum";
CM_ BO_ 1116 "Charge cable controller message: alert log; frame length from the layout, not yet observed on a vehicle bus";
CM_ SG_ 1116 CC_alertID "Charge cable controller: alert ID";
CM_ SG_ 1116 CC_alertType "Charge cable controller: alert type";
CM_ SG_ 1116 CC_a001_groundResistance "Charge cable controller: a001 ground resistance; raw 4095 = signal not available (SNA)";
CM_ SG_ 1116 CC_a003_gfciRmsCurrent "Charge cable controller: a003 gfci rms current";
CM_ SG_ 1116 CC_a003_gfciRmsCurrentAvg "Charge cable controller: a003 gfci rms current avg";
CM_ SG_ 1116 CC_a003_dcGfciCurrent "Charge cable controller: a003 dc gfci current";
CM_ SG_ 1116 CC_a003_gfciFaultReason "Charge cable controller: a003 gfci fault reason; raw 0 = signal not available (SNA)";
CM_ SG_ 1116 CC_a003_gfciFaultBucket "Charge cable controller: a003 gfci fault bucket";
CM_ SG_ 1116 CC_a004_gfciErrorReason "Charge cable controller: a004 gfci error reason; raw 0 = signal not available (SNA)";
CM_ SG_ 1116 CC_a004_gfciAsicErrorBitfield "Charge cable controller: a004 gfci asic error bitfield";
CM_ SG_ 1116 CC_a004_gfciSelfTestDuty "Charge cable controller: a004 gfci self test duty";
CM_ SG_ 1116 CC_a004_gfciSelfTestCurrent "Charge cable controller: a004 gfci self test current";
CM_ SG_ 1116 CC_a006_line1Current "Charge cable controller: a006 line1 current";
CM_ SG_ 1116 CC_a006_line2Current "Charge cable controller: a006 line2 current";
CM_ SG_ 1116 CC_a006_line3Current "Charge cable controller: a006 line3 current";
CM_ SG_ 1116 CC_a007_inputVoltage "Charge cable controller: a007 input voltage";
CM_ SG_ 1116 CC_a007_inputLineVoltage "Charge cable controller: a007 input line voltage";
CM_ SG_ 1116 CC_a007_inputNeutralVoltage "Charge cable controller: a007 input neutral voltage";
CM_ SG_ 1116 CC_a008_inputVoltage "Charge cable controller: a008 input voltage";
CM_ SG_ 1116 CC_a008_inputLineVoltage "Charge cable controller: a008 input line voltage";
CM_ SG_ 1116 CC_a008_inputNeutralVoltage "Charge cable controller: a008 input neutral voltage";
CM_ SG_ 1116 CC_a010_line1Voltage "Charge cable controller: a010 line1 voltage";
CM_ SG_ 1116 CC_a010_line2Voltage "Charge cable controller: a010 line2 voltage";
CM_ SG_ 1116 CC_a010_line3Voltage "Charge cable controller: a010 line3 voltage";
CM_ SG_ 1116 CC_a010_line1StuckClosed "Charge cable controller: a010 line1 stuck closed";
CM_ SG_ 1116 CC_a010_line2StuckClosed "Charge cable controller: a010 line2 stuck closed";
CM_ SG_ 1116 CC_a010_line3StuckClosed "Charge cable controller: a010 line3 stuck closed";
CM_ SG_ 1116 CC_a011_pcbaTemp "Charge cable controller: a011 pcba temp";
CM_ SG_ 1116 CC_a012_inputThermopile "Charge cable controller: a012 input thermopile";
CM_ SG_ 1116 CC_a012_inputThermopileDvdt "Charge cable controller: a012 input thermopile dvdt";
CM_ SG_ 1116 CC_a013_handleTemp "Charge cable controller: a013 handle temp";
CM_ SG_ 1116 CC_a014_failureCause "Charge cable controller: a014 failure cause";
CM_ SG_ 1116 CC_a014_meterFaultAddress "Charge cable controller: a014 meter fault address";
CM_ SG_ 1116 CC_a014_meterFaultData "Charge cable controller: a014 meter fault data";
CM_ SG_ 1116 CC_a014_meterRetryCount "Charge cable controller: a014 meter retry count";
CM_ SG_ 1116 CC_a015_pilotHighVolage "Charge cable controller: a015 pilot high volage";
CM_ SG_ 1116 CC_a015_smState "Charge cable controller: a015 sm state";
CM_ SG_ 1116 CC_a027_handleTemperature "Charge cable controller: a027 handle temperature";
CM_ SG_ 1116 CC_a027_handleTempFaultReason "Charge cable controller: a027 handle temp fault reason";
CM_ SG_ 1116 CC_a032_meteringSpiCommsFailure "Charge cable controller: a032 metering spi comms failure";
CM_ SG_ 1116 CC_a032_meteringConfigMismatch "Charge cable controller: a032 metering config mismatch";
CM_ SG_ 1116 CC_a033_nominalVoltage "Charge cable controller: a033 nominal voltage";
CM_ SG_ 1116 CC_a033_measuredVoltage "Charge cable controller: a033 measured voltage";
CM_ SG_ 1116 CC_a036_line1Voltage "Charge cable controller: a036 line1 voltage";
CM_ SG_ 1116 CC_a036_line2Voltage "Charge cable controller: a036 line2 voltage";
CM_ SG_ 1116 CC_a036_line3Voltage "Charge cable controller: a036 line3 voltage";
CM_ SG_ 1116 CC_a036_line1StuckOpen "Charge cable controller: a036 line1 stuck open";
CM_ SG_ 1116 CC_a036_line2StuckOpen "Charge cable controller: a036 line2 stuck open";
CM_ SG_ 1116 CC_a036_line3StuckOpen "Charge cable controller: a036 line3 stuck open";
CM_ SG_ 1116 CC_a037_expiredWatchdogModuleId "Charge cable controller: a037 expired watchdog module id";
CM_ SG_ 1116 CC_a037_expiredWatchdogTaskId "Charge cable controller: a037 expired watchdog task id";
CM_ SG_ 1116 CC_a037_expiredWatchdogAppCRC "Charge cable controller: a037 expired watchdog app CRC";
CM_ SG_ 1116 CC_a038_moduleMiaModuleId "Charge cable controller: a038 module mia module id";
CM_ SG_ 1116 CC_a038_moduleMiaTaskId "Charge cable controller: a038 module mia task id";
CM_ SG_ 1116 CC_a038_moduleMiaAppCRC "Charge cable controller: a038 module mia app CRC";
CM_ SG_ 1116 CC_a039_intModuleTemperature "Charge cable controller: a039 int module temperature";
CM_ SG_ 1116 CC_a040_handleTemperature "Charge cable controller: a040 handle temperature";
CM_ SG_ 1116 CC_a041_inputThermopile "Charge cable controller: a041 input thermopile";
CM_ SG_ 1116 CC_a041_inputThermopileDvdt "Charge cable controller: a041 input thermopile dvdt";
CM_ SG_ 1116 CC_a042_pcbaTemperature "Charge cable controller: a042 pcba temperature";
CM_ SG_ 1116 CC_a044_relayCoilVoltage "Charge cable controller: a044 relay coil voltage";
CM_ SG_ 1116 CC_a044_pcbaTemperature "Charge cable controller: a044 pcba temperature";
CM_ BO_ 1132 "Charge cable controller message: alert matrix1; frame length from the layout, not yet observed on a vehicle bus";
CM_ SG_ 1132 CC_a001_gndMonIntrptLineSide "Charge cable controller: a001 gnd mon intrpt line side";
CM_ SG_ 1132 CC_a002_gndMonIntrptLoadSide "Charge cable controller: a002 gnd mon intrpt load side";
CM_ SG_ 1132 CC_a003_CCIDTripped "Charge cable controller: a003 CCID tripped";
CM_ SG_ 1132 CC_a004_CCIDSelfTestFault "Charge cable controller: a004 CCID self test fault";
CM_ SG_ 1132 CC_a005_groundedNeutral "Charge cable controller: a005 grounded neutral";
CM_ SG_ 1132 CC_a006_inputOverCurrent "Charge cable controller: a006 input over current";
CM_ SG_ 1132 CC_a007_inputOverVoltage "Charge cable controller: a007 input over voltage";
CM_ SG_ 1132 CC_a008_inputUnderVoltage "Charge cable controller: a008 input under voltage";
CM_ SG_ 1132 CC_a009_inputMiswired "Charge cable controller: a009 input miswired";
CM_ SG_ 1132 CC_a010_contactorWelded "Charge cable controller: a010 contactor welded";
CM_ SG_ 1132 CC_a011_ambientOT "Charge cable controller: a011 ambient OT";
CM_ SG_ 1132 CC_a012_wallPlugOT "Charge cable controller: a012 wall plug OT";
CM_ SG_ 1132 CC_a013_vehConnOT "Charge cable controller: a013 veh conn OT";
CM_ SG_ 1132 CC_a014_mcuSelfTestFault "Charge cable controller: a014 mcu self test fault";
CM_ SG_ 1132 CC_a015_PilotAFault "Charge cable controller: a015 pilot a fault";
CM_ SG_ 1132 CC_a016_PilotBFault "Charge cable controller: a016 pilot b fault";
CM_ SG_ 1132 CC_a017_PilotCFault "Charge cable controller: a017 pilot c fault";
CM_ SG_ 1132 CC_a018_PilotDFault "Charge cable controller: a018 pilot d fault";
CM_ SG_ 1132 CC_a019_proxDisconnected "Charge cable controller: a019 prox disconnected";
CM_ SG_ 1132 CC_a020_3vRailIncorrect "Charge cable controller: a020 3v rail incorrect";
CM_ SG_ 1132 CC_a021_CB_noMaster "Charge cable controller: a021 CB no master";
CM_ SG_ 1132 CC_a022_CB_tooManyMasters "Charge cable controller: a022 CB too many masters";
CM_ SG_ 1132 CC_a023_CB_tooManySlaves "Charge cable controller: a023 CB too many slaves";
CM_ SG_ 1132 CC_a024_CB_masterISetTooLow "Charge cable controller: a024 CB master i set too low";
CM_ SG_ 1132 CC_a025_evseTemp "Charge cable controller: a025 evse temp";
CM_ SG_ 1132 CC_a026_wallPlugTemp "Charge cable controller: a026 wall plug temp";
CM_ SG_ 1132 CC_a027_vehicleHandleTemp "Charge cable controller: a027 vehicle handle temp";
CM_ SG_ 1132 CC_a028_CB_rotarySelect "Charge cable controller: a028 CB rotary select";
CM_ SG_ 1132 CC_a029_PilotFFault "Charge cable controller: a029 pilot f fault";
CM_ SG_ 1132 CC_a030_masterSlaveMismatch "Charge cable controller: a030 master slave mismatch";
CM_ SG_ 1132 CC_a031_pllLockLost "Charge cable controller: a031 pll lock lost";
CM_ SG_ 1132 CC_a032_meteringFailure "Charge cable controller: a032 metering failure";
CM_ SG_ 1132 CC_a033_vRefOutOfRange "Charge cable controller: a033 v ref out of range";
CM_ SG_ 1132 CC_a034_bootAlert "Charge cable controller: a034 boot alert";
CM_ SG_ 1132 CC_a035_CCIDCalibration "Charge cable controller: a035 CCID calibration";
CM_ SG_ 1132 CC_a036_contactorStuckOpen "Charge cable controller: a036 contactor stuck open";
CM_ SG_ 1132 CC_a037_internalModuleWatchdogEx "Charge cable controller: a037 internal module watchdog expired";
CM_ SG_ 1132 CC_a038_internalModuleMia "Charge cable controller: a038 internal module mia";
CM_ SG_ 1132 CC_a039_internalModuleOverTemp "Charge cable controller: a039 internal module over temp";
CM_ SG_ 1132 CC_a040_handleTempFoldback "Charge cable controller: a040 handle temp foldback";
CM_ SG_ 1132 CC_a041_inputWiringFoldback "Charge cable controller: a041 input wiring foldback";
CM_ SG_ 1132 CC_a042_pcbaTempFoldback "Charge cable controller: a042 pcba temp foldback";
CM_ SG_ 1132 CC_a043_configurationRequired "Charge cable controller: a043 configuration required";
CM_ SG_ 1132 CC_a044_relayCoilVoltageRational "Charge cable controller: a044 relay coil voltage rationality";
CM_ SG_ 1132 CC_a045_ACPowerLoss "Charge cable controller: a045 AC power loss";
CM_ SG_ 1132 CC_a046_GFCIConfigInvalid "Charge cable controller: a046 GFCI config invalid";
CM_ SG_ 1132 CC_a047_MDMotorContFault "Charge cable controller: a047 MD motor cont fault";
CM_ SG_ 1132 CC_a048_ACMDAdapterFault "Charge cable controller: a048 ACMD adapter fault";
CM_ SG_ 1132 CC_a049_rs485Fault "Charge cable controller: a049 rs485 fault";
CM_ SG_ 1132 CC_a050_eFuseFault "Charge cable controller: a050 e fuse fault";
CM_ SG_ 1132 CC_a051_chcCriticalFault "Charge cable controller: a051 chc critical fault";
CM_ SG_ 1132 CC_a052_vRefOutOfRangePWM "Charge cable controller: a052 v ref out of range PWM";
CM_ SG_ 1132 CC_a057_chcVitalsRequestFailure "Charge cable controller: a057 chc vitals request failure";
CM_ SG_ 1132 CC_a060_persistenceFault "Charge cable controller: a060 persistence fault";
CM_ SG_ 1132 CC_a061_unfinishedCommissioning "Charge cable controller: a061 unfinished commissioning";
CM_ BO_ 796 "Charge cable controller message: chg status; frame length from the layout, not yet observed on a vehicle bus";
CM_ SG_ 796 CC_currentLimit "Maximum allowable AC current the wall connector is willing to provide; raw 255 = signal not available (SNA)";
CM_ SG_ 796 CC_pilotState "State of pilot signal reported by the wall connector; raw 3 = signal not available (SNA)";
CM_ SG_ 796 CC_numPhases "Number of AC phases expected by wall connector; raw 0 = signal not available (SNA)";
CM_ SG_ 796 CC_line1Voltage "RMS voltage on L1 terminal of wall connector; raw 511 = signal not available (SNA)";
CM_ SG_ 796 CC_gridGrounding "Grouding scheme expected by the wall connector; raw 2 = signal not available (SNA)";
CM_ SG_ 796 CC_deltaTransformer "Grid configuration expected by the wall connector";
CM_ SG_ 796 CC_numVehCharging "Number of vehicles charging in wall connector load sharing group";
CM_ SG_ 796 CC_line2Voltage "RMS voltage on L2 terminal of wall connector; raw 511 = signal not available (SNA)";
CM_ SG_ 796 CC_line3Voltage "RMS voltage on L3 terminal of wall connector; raw 511 = signal not available (SNA)";
CM_ SG_ 796 CC_groundResistance "Charge cable controller: ground resistance; raw 4095 = signal not available (SNA)";
CM_ BO_ 797 "Charge cable controller message: chg status2; frame length from the layout, not yet observed on a vehicle bus";
CM_ SG_ 797 CC_chgStatus2Index "Charge cable controller: chg status2 index";
CM_ SG_ 797 CC_buttonState "Charge cable controller: button state";
CM_ SG_ 797 EVSE_v2xSupport "Charge cable controller: v2x support";
CM_ SG_ 797 EVSE_v2xHandshakeStart "Charge cable controller: v2x handshake start";
CM_ SG_ 797 EVSE_v2xSessionType "Charge cable controller: v2x session type; raw 0 = signal not available (SNA)";
CM_ BO_ 812 "Charge cable controller message: log data; frame length from the layout, not yet observed on a vehicle bus";
CM_ SG_ 812 CC_logIndex "Charge cable controller: log index";
CM_ SG_ 812 CC_activeConnectorID "Site identifier of active charge connector";
CM_ SG_ 812 CC_temperature1 "Charge cable vehicle connector temperature";
CM_ SG_ 812 CC_temperature2 "Charge cable vehicle connector temperature";
CM_ SG_ 812 CC_temperature3 "Charge cable vehicle connector temperature";
CM_ SG_ 812 CC_contactor1Closed "State of contactor 1 in wall connector";
CM_ SG_ 812 CC_contactor2Closed "State of contactor 1 in wall connector";
CM_ SG_ 812 CC_temperature4 "Charge cable vehicle connector temperature";
CM_ SG_ 812 CC_conn1Current "AC current on connector 1 in wall charger load sharing group; raw 255 = signal not available (SNA)";
CM_ SG_ 812 CC_conn2Current "AC current on connector 2 in wall charger load sharing group; raw 255 = signal not available (SNA)";
CM_ SG_ 812 CC_conn3Current "AC current on connector 3 in wall charger load sharing group; raw 255 = signal not available (SNA)";
CM_ SG_ 812 CC_conn4Current "AC current on connector 4 in wall charger load sharing group; raw 255 = signal not available (SNA)";
CM_ SG_ 812 CC_lifetimei2t "Charge cable controller: lifetimei2t";
CM_ SG_ 812 CC_lifetimeCtrCycles "Charge cable controller: lifetime ctr cycles";
CM_ SG_ 812 CC_lifetimeCtrCyclesLoaded "Charge cable controller: lifetime ctr cycles loaded";
CM_ SG_ 812 CC_lifetimeAlertCount "Charge cable controller: lifetime alert count";
CM_ SG_ 812 CC_lifetimeThermalFoldbacks "Charge cable controller: lifetime thermal foldbacks";
CM_ SG_ 812 CC_lifetimeAvgStartupTemp "Charge cable controller: lifetime avg startup temp";
CM_ BO_ 870 "CMPD ECU message: info; frame length from the layout, not yet observed on a vehicle bus";
CM_ SG_ 870 CMPD_infoIndex "CMPD ECU: info index";
CM_ SG_ 870 CMPD_infoBuildType "CMPD ECU: info build type";
CM_ SG_ 870 CMPD_infoBuildConfigId "CMPD ECU: info build config id";
CM_ SG_ 870 CMPD_infoHardwareId "CMPD ECU: info hardware id";
CM_ SG_ 870 CMPD_infoComponentId "CMPD ECU: info component id";
CM_ SG_ 870 CMPD_infoPcbaId "CMPD ECU: info pcba id";
CM_ SG_ 870 CMPD_infoAssemblyId "CMPD ECU: info assembly id; raw 255 = signal not available (SNA)";
CM_ SG_ 870 CMPD_infoUsageId "CMPD ECU: info usage id";
CM_ SG_ 870 CMPD_infoSubUsageId "CMPD ECU: info sub usage id";
CM_ BO_ 679 "CMPD ECU message: state; frame length from the layout, not yet observed on a vehicle bus";
CM_ SG_ 679 CMPD_speedRPM "Reports compressor speed.";
CM_ SG_ 679 CMPD_speedDuty "Reports compressor speed duty cycle percentage.";
CM_ SG_ 679 CMPD_inputHVPower "Measures compressor input high voltage (HV) power consumption.";
CM_ SG_ 679 CMPD_inputHVCurrent "Measures compressor input high voltage (HV) current draw.";
CM_ SG_ 679 CMPD_inputHVVoltage "Measures compressor input high voltage (HV) level.";
CM_ SG_ 679 CMPD_2ShuntModeActive "Indicates the compressor motor control is running using only two current shunt resistors instead of three.";
CM_ SG_ 679 CMPD_powerLimitActive "Indicates the compressor power limit is active.";
CM_ SG_ 679 CMPD_state "Reports compressor operational state; raw 15 = signal not available (SNA)";
CM_ SG_ 679 CMPD_wasteHeatState "Reports compressor waste heat recovery state.";
CM_ SG_ 679 CMPD_powerLimitTooLowToStart "Indicates the compressor power limit is too low to start the compressor.";
CM_ SG_ 679 CMPD_ready "Indicates the compressor is ready to start.";
CM_ BO_ 1559 "CMPD ECU message: uds response; frame length from the layout, not yet observed on a vehicle bus";
CM_ SG_ 1559 CMPD_udsResponseData "CMPD ECU: uds response data";
CM_ BO_ 867 "A/C compressor message: info; frame length from the layout, not yet observed on a vehicle bus";
CM_ SG_ 867 CMP_infoIndex "A/C compressor: info index";
CM_ SG_ 867 CMP_infoBuildType "A/C compressor: info build type";
CM_ SG_ 867 CMP_infoBuildConfigId "A/C compressor: info build config id";
CM_ SG_ 867 CMP_infoHardwareId "A/C compressor: info hardware id";
CM_ SG_ 867 CMP_infoComponentId "A/C compressor: info component id";
CM_ SG_ 867 CMP_infoPcbaId "A/C compressor: info pcba id";
CM_ SG_ 867 CMP_infoAssemblyId "A/C compressor: info assembly id; raw 255 = signal not available (SNA)";
CM_ SG_ 867 CMP_infoUsageId "A/C compressor: info usage id";
CM_ SG_ 867 CMP_infoSubUsageId "A/C compressor: info sub usage id";
CM_ SG_ 867 CMP_infoPlatformType "A/C compressor: info platform type";
CM_ SG_ 867 CMP_infoAppCrc "A/C compressor: info app crc";
CM_ SG_ 867 CMP_infoBootUdsProtoVersion "A/C compressor: info boot uds proto version";
CM_ SG_ 867 CMP_infoBootCrc "A/C compressor: info boot crc";
CM_ BO_ 1555 "A/C compressor message: uds response; frame length from the layout, not yet observed on a vehicle bus";
CM_ SG_ 1555 CMP_udsResponseData "A/C compressor: uds response data";
CM_ BO_ 1767 "Charge port controller message: iso tp pipe to pncd; frame length from the layout, not yet observed on a vehicle bus";
CM_ SG_ 1767 CP_isoTpToPncdData "Charge port controller: iso tp to pncd data";
BA_DEF_ BO_ "GenMsgCycleTime" INT 0 3600000;
BA_DEF_ BO_ "GenMsgSendType" ENUM "Cyclic","NotUsed","NotUsed","NotUsed","NotUsed","NotUsed","NotUsed","IfActive","NoMsgSendType","NotUsed";
BA_DEF_ BO_ "VFrameFormat" ENUM "StandardCAN","ExtendedCAN","reserved","J1939PG","reserved","reserved","reserved","reserved","reserved","reserved","reserved","reserved","reserved","reserved","StandardCAN_FD","ExtendedCAN_FD";
BA_DEF_ BO_ "CANFD_BRS" ENUM "0","1";
BA_DEF_ SG_ "GenSigSNA" STRING;
BA_DEF_ SG_ "SystemSignalLongSymbol" STRING;
BA_DEF_ SG_ "Confidence" ENUM "validated","plausible","layout-only","contradicted";
BA_DEF_DEF_ "GenMsgCycleTime" 0;
BA_DEF_DEF_ "GenMsgSendType" "NoMsgSendType";
BA_DEF_DEF_ "VFrameFormat" "StandardCAN";
BA_DEF_DEF_ "CANFD_BRS" "1";
BA_DEF_DEF_ "GenSigSNA" "";
BA_DEF_DEF_ "SystemSignalLongSymbol" "";
BA_DEF_DEF_ "Confidence" "layout-only";
BA_ "GenMsgCycleTime" BO_ 946 30000;
BA_ "GenMsgSendType" BO_ 946 0;
BA_ "GenMsgCycleTime" BO_ 914 1000;
BA_ "GenMsgSendType" BO_ 914 0;
BA_ "GenMsgCycleTime" BO_ 1810 1000;
BA_ "GenMsgSendType" BO_ 1810 0;
BA_ "GenMsgCycleTime" BO_ 594 100;
BA_ "GenMsgSendType" BO_ 594 0;
BA_ "GenMsgCycleTime" BO_ 674 1000;
BA_ "GenMsgSendType" BO_ 674 0;
BA_ "GenMsgCycleTime" BO_ 658 100;
BA_ "GenMsgSendType" BO_ 658 0;
BA_ "GenMsgCycleTime" BO_ 1170 1000;
BA_ "GenMsgSendType" BO_ 1170 0;
BA_ "GenMsgCycleTime" BO_ 530 100;
BA_ "GenMsgSendType" BO_ 530 0;
BA_ "GenMsgCycleTime" BO_ 786 1000;
BA_ "GenMsgSendType" BO_ 786 0;
BA_ "GenMsgCycleTime" BO_ 1071 1000;
BA_ "GenMsgSendType" BO_ 1071 0;
BA_ "GenMsgCycleTime" BO_ 754 100;
BA_ "GenMsgSendType" BO_ 754 0;
BA_ "GenMsgCycleTime" BO_ 810 5000;
BA_ "GenMsgSendType" BO_ 810 0;
BA_ "GenMsgCycleTime" BO_ 1132 1000;
BA_ "GenMsgSendType" BO_ 1132 0;
BA_ "GenMsgCycleTime" BO_ 796 100;
BA_ "GenMsgSendType" BO_ 796 0;
BA_ "GenMsgCycleTime" BO_ 797 100;
BA_ "GenMsgSendType" BO_ 797 0;
BA_ "GenMsgCycleTime" BO_ 812 1000;
BA_ "GenMsgSendType" BO_ 812 0;
BA_ "GenMsgCycleTime" BO_ 870 1000;
BA_ "GenMsgSendType" BO_ 870 0;
BA_ "GenMsgCycleTime" BO_ 679 100;
BA_ "GenMsgSendType" BO_ 679 0;
BA_ "GenMsgCycleTime" BO_ 867 1000;
BA_ "GenMsgSendType" BO_ 867 0;
BA_ "Confidence" SG_ 946 BMS_log2MuxId 1;
BA_ "Confidence" SG_ 946 BMS_maxChargeRestartNeededByVolt 0;
BA_ "SystemSignalLongSymbol" SG_ 946 BMS_maxChargeRestartNeededByVolt "BMS_maxChargeRestartNeededByVoltage";
BA_ "Confidence" SG_ 946 BMS_cacAvg 0;
BA_ "Confidence" SG_ 946 BMS_maxChargeNearComplete 0;
BA_ "Confidence" SG_ 946 BMS_cacMin 0;
BA_ "Confidence" SG_ 946 BMS_cacMinBrickId 0;
BA_ "Confidence" SG_ 946 BMS_cacMax 0;
BA_ "Confidence" SG_ 946 BMS_cacMaxBrickId 0;
BA_ "Confidence" SG_ 946 BMS_acRippleConfigNvramValid 0;
BA_ "Confidence" SG_ 946 BMS_hvChain_useLeakyBucket 0;
BA_ "Confidence" SG_ 946 BMS_hvChain_iLimit 0;
BA_ "GenSigSNA" SG_ 946 BMS_hvChain_iLimit "16383";
BA_ "Confidence" SG_ 946 BMS_hvChain_limitingState 0;
BA_ "GenSigSNA" SG_ 946 BMS_hvChain_limitingState "511";
BA_ "Confidence" SG_ 946 BMS_hvChain_limitingStateTempera 3;
BA_ "GenSigSNA" SG_ 946 BMS_hvChain_limitingStateTempera "4096";
BA_ "SystemSignalLongSymbol" SG_ 946 BMS_hvChain_limitingStateTempera "BMS_hvChain_limitingStateTemperature";
BA_ "Confidence" SG_ 946 BMS_acRippleIsSupported 0;
BA_ "Confidence" SG_ 946 BMS_acRippleStartTemperatureMax 0;
BA_ "Confidence" SG_ 946 BMS_acRippleStartTemperatureMin 0;
BA_ "Confidence" SG_ 946 BMS_fcLinkTestDecayTime 0;
BA_ "GenSigSNA" SG_ 946 BMS_fcLinkTestDecayTime "1023";
BA_ "Confidence" SG_ 946 BMS_fcLinkTestTimeSinceLastRun 0;
BA_ "Confidence" SG_ 946 BMS_pcsPrechargeRequest 0;
BA_ "Confidence" SG_ 946 BMS_pcsPrechargeTargetVoltage 0;
BA_ "Confidence" SG_ 946 BMS_recentOvUvAlert 0;
BA_ "Confidence" SG_ 946 BMS_recentIsoAlert 0;
BA_ "Confidence" SG_ 946 BMS_recentBmbMiaAlert 0;
BA_ "Confidence" SG_ 946 BMS_cacBlendingConfigNvramValid 0;
BA_ "Confidence" SG_ 946 BMS_cacBlendingEnabled 0;
BA_ "Confidence" SG_ 946 BMS_cacBlendPercentPerCycle 0;
BA_ "Confidence" SG_ 946 BMS_energyVariableChgRequested 0;
BA_ "Confidence" SG_ 946 BMS_packRestTime 0;
BA_ "Confidence" SG_ 946 BMS_idealEnergyFloor 0;
BA_ "GenSigSNA" SG_ 946 BMS_idealEnergyFloor "1023";
BA_ "Confidence" SG_ 946 BMS_thmGradientSlopeCondition 0;
BA_ "Confidence" SG_ 946 BMS_recentSlopeConditon 0;
BA_ "Confidence" SG_ 946 BMS_dynamicEnergyBuffer 0;
BA_ "GenSigSNA" SG_ 946 BMS_dynamicEnergyBuffer "1023";
BA_ "Confidence" SG_ 946 BMS_temperatureCondition 0;
BA_ "Confidence" SG_ 946 BMS_thmGradientSlope 0;
BA_ "Confidence" SG_ 946 BMS_thmGradient 0;
BA_ "Confidence" SG_ 946 BMS_epochTimeEstimate 1;
BA_ "Confidence" SG_ 946 BMS_histogramStartTimeIrrational 1;
BA_ "Confidence" SG_ 946 BMS_histogramDischargeThroughput 1;
BA_ "SystemSignalLongSymbol" SG_ 946 BMS_histogramDischargeThroughput "BMS_histogramDischargeThroughputIrrational";
BA_ "Confidence" SG_ 946 BMS_histogramChargeThroughputIrr 1;
BA_ "SystemSignalLongSymbol" SG_ 946 BMS_histogramChargeThroughputIrr "BMS_histogramChargeThroughputIrrational";
BA_ "Confidence" SG_ 946 BMS_histogramTotalTimeIrrational 1;
BA_ "Confidence" SG_ 946 BMS_histogramStorageDataIsLow 1;
BA_ "Confidence" SG_ 946 BMS_tempVsSocTotalChgEnergy 0;
BA_ "Confidence" SG_ 946 BMS_powerVsVoltageTotalChgEnergy 0;
BA_ "Confidence" SG_ 946 BMS_lifeModelOutputsAreTrustwort 0;
BA_ "SystemSignalLongSymbol" SG_ 946 BMS_lifeModelOutputsAreTrustwort "BMS_lifeModelOutputsAreTrustworthy";
BA_ "Confidence" SG_ 946 BMS_dSocNormalizedMin 0;
BA_ "GenSigSNA" SG_ 946 BMS_dSocNormalizedMin "4095";
BA_ "Confidence" SG_ 946 BMS_dSocNormalizedFiltMin 0;
BA_ "GenSigSNA" SG_ 946 BMS_dSocNormalizedFiltMin "4095";
BA_ "Confidence" SG_ 946 BMS_dSocMinAlpha 0;
BA_ "GenSigSNA" SG_ 946 BMS_dSocMinAlpha "4095";
BA_ "Confidence" SG_ 946 BMS_dSocMaxLowAlphaCounter 0;
BA_ "Confidence" SG_ 946 BMS_dSocMinAlphaBrickID 0;
BA_ "Confidence" SG_ 946 BMS_dSocCacMargin 0;
BA_ "GenSigSNA" SG_ 946 BMS_dSocCacMargin "511";
BA_ "Confidence" SG_ 946 BMS_lifeModelNoCurrentStorageCap 0;
BA_ "GenSigSNA" SG_ 946 BMS_lifeModelNoCurrentStorageCap "511";
BA_ "SystemSignalLongSymbol" SG_ 946 BMS_lifeModelNoCurrentStorageCap "BMS_lifeModelNoCurrentStorageCapacityLoss";
BA_ "Confidence" SG_ 946 BMS_lifeModelShortDcr 0;
BA_ "GenSigSNA" SG_ 946 BMS_lifeModelShortDcr "255";
BA_ "Confidence" SG_ 946 BMS_lifeModelLongDcr 0;
BA_ "GenSigSNA" SG_ 946 BMS_lifeModelLongDcr "4096";
BA_ "Confidence" SG_ 946 BMS_lifeModelStorageCapacityLoss 0;
BA_ "GenSigSNA" SG_ 946 BMS_lifeModelStorageCapacityLoss "511";
BA_ "Confidence" SG_ 946 BMS_lifeModelThroughputCapacityL 0;
BA_ "GenSigSNA" SG_ 946 BMS_lifeModelThroughputCapacityL "511";
BA_ "SystemSignalLongSymbol" SG_ 946 BMS_lifeModelThroughputCapacityL "BMS_lifeModelThroughputCapacityLoss";
BA_ "Confidence" SG_ 946 BMS_passiveCoolCellTargetT 0;
BA_ "Confidence" SG_ 946 BMS_lifeModelAvgTempSeverity 0;
BA_ "GenSigSNA" SG_ 946 BMS_lifeModelAvgTempSeverity "31";
BA_ "Confidence" SG_ 946 BMS_lifeModelDepthOfDischargeSev 0;
BA_ "GenSigSNA" SG_ 946 BMS_lifeModelDepthOfDischargeSev "255";
BA_ "SystemSignalLongSymbol" SG_ 946 BMS_lifeModelDepthOfDischargeSev "BMS_lifeModelDepthOfDischargeSeverity";
BA_ "Confidence" SG_ 946 BMS_lifeModelHistogramCapacityLo 0;
BA_ "GenSigSNA" SG_ 946 BMS_lifeModelHistogramCapacityLo "511";
BA_ "SystemSignalLongSymbol" SG_ 946 BMS_lifeModelHistogramCapacityLo "BMS_lifeModelHistogramCapacityLoss";
BA_ "Confidence" SG_ 946 BMS_lifeModelHistogramBrickCapac 0;
BA_ "GenSigSNA" SG_ 946 BMS_lifeModelHistogramBrickCapac "8191";
BA_ "SystemSignalLongSymbol" SG_ 946 BMS_lifeModelHistogramBrickCapac "BMS_lifeModelHistogramBrickCapacity";
BA_ "Confidence" SG_ 946 BMS_lifeModelDcrGrowthPercent 0;
BA_ "GenSigSNA" SG_ 946 BMS_lifeModelDcrGrowthPercent "8192";
BA_ "Confidence" SG_ 946 BMS_nominalFullPackEnergyRaw 0;
BA_ "GenSigSNA" SG_ 946 BMS_nominalFullPackEnergyRaw "65535";
BA_ "Confidence" SG_ 946 BMS_nominalEnergyRemainingBuffer 0;
BA_ "GenSigSNA" SG_ 946 BMS_nominalEnergyRemainingBuffer "65535";
BA_ "SystemSignalLongSymbol" SG_ 946 BMS_nominalEnergyRemainingBuffer "BMS_nominalEnergyRemainingBuffered";
BA_ "Confidence" SG_ 946 BMS_idealEnergyRemainingBuffered 0;
BA_ "GenSigSNA" SG_ 946 BMS_idealEnergyRemainingBuffered "65535";
BA_ "Confidence" SG_ 946 BMS_largestSynchronizedCacErrorP 0;
BA_ "GenSigSNA" SG_ 946 BMS_largestSynchronizedCacErrorP "255";
BA_ "SystemSignalLongSymbol" SG_ 946 BMS_largestSynchronizedCacErrorP "BMS_largestSynchronizedCacErrorPct";
BA_ "Confidence" SG_ 946 BMS_lifeModelSpreadMinOffset 1;
BA_ "Confidence" SG_ 946 BMS_lifeModelSpreadMaxOffset 1;
BA_ "Confidence" SG_ 946 BMS_largestCacSpreadErrorLower 0;
BA_ "GenSigSNA" SG_ 946 BMS_largestCacSpreadErrorLower "4095";
BA_ "Confidence" SG_ 946 BMS_lifeModelAverageCac 0;
BA_ "GenSigSNA" SG_ 946 BMS_lifeModelAverageCac "4095";
BA_ "Confidence" SG_ 946 BMS_lifeModelCacBrick1 0;
BA_ "GenSigSNA" SG_ 946 BMS_lifeModelCacBrick1 "4095";
BA_ "Confidence" SG_ 946 BMS_lifeModelAverageOffset 0;
BA_ "GenSigSNA" SG_ 946 BMS_lifeModelAverageOffset "512";
BA_ "Confidence" SG_ 946 BMS_percentCacUpdatesInTimeWindo 0;
BA_ "SystemSignalLongSymbol" SG_ 946 BMS_percentCacUpdatesInTimeWindo "BMS_percentCacUpdatesInTimeWindow";
BA_ "Confidence" SG_ 946 BMS_lifeModelMaxCacBrickId 0;
BA_ "GenSigSNA" SG_ 946 BMS_lifeModelMaxCacBrickId "255";
BA_ "Confidence" SG_ 946 BMS_lifeModelMaxCac 0;
BA_ "GenSigSNA" SG_ 946 BMS_lifeModelMaxCac "4095";
BA_ "Confidence" SG_ 946 BMS_lifeModelMinCacBrickId 0;
BA_ "GenSigSNA" SG_ 946 BMS_lifeModelMinCacBrickId "255";
BA_ "Confidence" SG_ 946 BMS_lifeModelMinCac 0;
BA_ "GenSigSNA" SG_ 946 BMS_lifeModelMinCac "4095";
BA_ "Confidence" SG_ 946 BMS_restingPointCacAvg 0;
BA_ "GenSigSNA" SG_ 946 BMS_restingPointCacAvg "4095";
BA_ "Confidence" SG_ 946 BMS_cacEstimationSource 0;
BA_ "Confidence" SG_ 946 BMS_packCalibrationBirthDateBinn 1;
BA_ "SystemSignalLongSymbol" SG_ 946 BMS_packCalibrationBirthDateBinn "BMS_packCalibrationBirthDateBinned";
BA_ "Confidence" SG_ 946 BMS_synchronizedCacMaxRaw 0;
BA_ "GenSigSNA" SG_ 946 BMS_synchronizedCacMaxRaw "4095";
BA_ "Confidence" SG_ 946 BMS_synchronizedCacMinRaw 0;
BA_ "GenSigSNA" SG_ 946 BMS_synchronizedCacMinRaw "4095";
BA_ "Confidence" SG_ 946 BMS_largestSyncCacErrorStartSoc 0;
BA_ "Confidence" SG_ 946 BMS_largestSyncCacErrorEndSoc 0;
BA_ "Confidence" SG_ 946 BMS_runtimeSocConfigNvramValid 0;
BA_ "Confidence" SG_ 946 BMS_runtimeSocCorrectionsEnabled 0;
BA_ "Confidence" SG_ 946 BMS_rubberBandingEnabled 0;
BA_ "Confidence" SG_ 946 BMS_rubberBandingConfigNvramVali 0;
BA_ "SystemSignalLongSymbol" SG_ 946 BMS_rubberBandingConfigNvramVali "BMS_rubberBandingConfigNvramValid";
BA_ "Confidence" SG_ 946 BMS_runtimeSocMinTempForModel 0;
BA_ "Confidence" SG_ 946 BMS_energyBufferConfigNvramValid 0;
BA_ "Confidence" SG_ 946 BMS_thermalEvent1pDetectConfigDi 0;
BA_ "SystemSignalLongSymbol" SG_ 946 BMS_thermalEvent1pDetectConfigDi "BMS_thermalEvent1pDetectConfigDisabled";
BA_ "Confidence" SG_ 946 BMS_sohEnergy 0;
BA_ "GenSigSNA" SG_ 946 BMS_sohEnergy "2047";
BA_ "Confidence" SG_ 946 BMS_fullCapacitySohEnergy 0;
BA_ "GenSigSNA" SG_ 946 BMS_fullCapacitySohEnergy "2047";
BA_ "Confidence" SG_ 946 BMS_calibratedCapacitySohEnergy 0;
BA_ "GenSigSNA" SG_ 946 BMS_calibratedCapacitySohEnergy "2047";
BA_ "Confidence" SG_ 946 BMS_estimatedCapacitySohEnergy 0;
BA_ "GenSigSNA" SG_ 946 BMS_estimatedCapacitySohEnergy "2047";
BA_ "Confidence" SG_ 946 BMS_prevUserFacingSohEnergy 0;
BA_ "GenSigSNA" SG_ 946 BMS_prevUserFacingSohEnergy "2047";
BA_ "Confidence" SG_ 946 BMS_stateOfHealthMinCac 0;
BA_ "GenSigSNA" SG_ 946 BMS_stateOfHealthMinCac "8191";
BA_ "Confidence" SG_ 946 BMS_lifeModelStorageLossPackAge 0;
BA_ "GenSigSNA" SG_ 946 BMS_lifeModelStorageLossPackAge "16383";
BA_ "Confidence" SG_ 946 BMS_lifeModelThroughputDcrCycleC 0;
BA_ "GenSigSNA" SG_ 946 BMS_lifeModelThroughputDcrCycleC "4095";
BA_ "SystemSignalLongSymbol" SG_ 946 BMS_lifeModelThroughputDcrCycleC "BMS_lifeModelThroughputDcrCycleCount";
BA_ "Confidence" SG_ 946 BMS_stateOfHealthMinCacLowerBoun 0;
BA_ "GenSigSNA" SG_ 946 BMS_stateOfHealthMinCacLowerBoun "8191";
BA_ "SystemSignalLongSymbol" SG_ 946 BMS_stateOfHealthMinCacLowerBoun "BMS_stateOfHealthMinCacLowerBound";
BA_ "Confidence" SG_ 946 BMS_energyWalkCounter 0;
BA_ "Confidence" SG_ 946 BMS_energyWalkTimeoutCounter 0;
BA_ "Confidence" SG_ 946 BMS_dynamicCcvEnabled 0;
BA_ "Confidence" SG_ 946 BMS_chargeTargetLookupSoc 0;
BA_ "Confidence" SG_ 946 BMS_stateOfHealth 0;
BA_ "GenSigSNA" SG_ 946 BMS_stateOfHealth "1023";
BA_ "Confidence" SG_ 946 BMS_avgShuntAsicCurrentOffset 0;
BA_ "GenSigSNA" SG_ 946 BMS_avgShuntAsicCurrentOffset "16384";
BA_ "Confidence" SG_ 946 BMS_cellAttributesGeneralAttribu 0;
BA_ "GenSigSNA" SG_ 946 BMS_cellAttributesGeneralAttribu "0";
BA_ "SystemSignalLongSymbol" SG_ 946 BMS_cellAttributesGeneralAttribu "BMS_cellAttributesGeneralAttributes";
BA_ "Confidence" SG_ 946 BMS_cellAttributesPackManufactur 0;
BA_ "GenSigSNA" SG_ 946 BMS_cellAttributesPackManufactur "0";
BA_ "SystemSignalLongSymbol" SG_ 946 BMS_cellAttributesPackManufactur "BMS_cellAttributesPackManufacturingLocation";
BA_ "Confidence" SG_ 946 BMS_cellAttributesRemanufactured 0;
BA_ "SystemSignalLongSymbol" SG_ 946 BMS_cellAttributesRemanufactured "BMS_cellAttributesRemanufacturedPack";
BA_ "Confidence" SG_ 946 BMS_cellAttributesConfigNvramVal 0;
BA_ "SystemSignalLongSymbol" SG_ 946 BMS_cellAttributesConfigNvramVal "BMS_cellAttributesConfigNvramValid";
BA_ "Confidence" SG_ 946 BMS_cellAttributesCellType 0;
BA_ "GenSigSNA" SG_ 946 BMS_cellAttributesCellType "0";
BA_ "Confidence" SG_ 946 BMS_cellAttributesAutocloseAndSc 0;
BA_ "SystemSignalLongSymbol" SG_ 946 BMS_cellAttributesAutocloseAndSc "BMS_cellAttributesAutocloseAndScrapPackOnFieldReturn";
BA_ "Confidence" SG_ 946 BMS_cellAttributesShipPackForFai 0;
BA_ "SystemSignalLongSymbol" SG_ 946 BMS_cellAttributesShipPackForFai "BMS_cellAttributesShipPackForFailureAnalysis";
BA_ "Confidence" SG_ 946 BMS_lifeModelThroughputCycleCoun 0;
BA_ "GenSigSNA" SG_ 946 BMS_lifeModelThroughputCycleCoun "4095";
BA_ "SystemSignalLongSymbol" SG_ 946 BMS_lifeModelThroughputCycleCoun "BMS_lifeModelThroughputCycleCount";
BA_ "Confidence" SG_ 946 BMS_limpChargeCurrentLimit 0;
BA_ "GenSigSNA" SG_ 946 BMS_limpChargeCurrentLimit "1023";
BA_ "Confidence" SG_ 946 BMS_energyRemainingDisplayError 0;
BA_ "Confidence" SG_ 946 BMS_energyRemainingTDisplayError 0;
BA_ "Confidence" SG_ 946 BMS_numOfThermistors 0;
BA_ "Confidence" SG_ 946 BMS_numOfBricks 0;
BA_ "Confidence" SG_ 946 BMS_cellChargeDcCurrentLimit 0;
BA_ "Confidence" SG_ 946 BMS_socByDeltaVEnabled 0;
BA_ "Confidence" SG_ 946 BMS_socByDvMaxSocLimit 0;
BA_ "Confidence" SG_ 946 BMS_socByDvVoltageChangeOverAh 0;
BA_ "Confidence" SG_ 946 BMS_socByDvMaxSocByAhCorrected 0;
BA_ "Confidence" SG_ 946 BMS_socByDvMaxBrickVoltage 0;
BA_ "Confidence" SG_ 946 BMS_socByDvMaxBrickId 0;
BA_ "Confidence" SG_ 946 BMS_socByDvMaxSocByAhRaw 0;
BA_ "Confidence" SG_ 946 BMS_voltageInstabilityExcessNois 0;
BA_ "SystemSignalLongSymbol" SG_ 946 BMS_voltageInstabilityExcessNois "BMS_voltageInstabilityExcessNoiseLog";
BA_ "Confidence" SG_ 946 BMS_maxModelThermistorTempDelta 0;
BA_ "GenSigSNA" SG_ 946 BMS_maxModelThermistorTempDelta "512";
BA_ "Confidence" SG_ 946 BMS_activeCoolCellTargetT 0;
BA_ "Confidence" SG_ 946 BMS_cellTempTargetMode 0;
BA_ "Confidence" SG_ 946 BMS_minPackTempForChargeToStart 0;
BA_ "Confidence" SG_ 914 BMS_packConfigMultiplexer 1;
BA_ "Confidence" SG_ 914 BMS_reservedConfig_0 0;
BA_ "Confidence" SG_ 914 BMS_moduleType 0;
BA_ "Confidence" SG_ 914 BMS_thermalPackType 0;
BA_ "Confidence" SG_ 914 BMS_packMass 0;
BA_ "Confidence" SG_ 914 BMS_platformMaxBusVoltage 0;
BA_ "Confidence" SG_ 914 BMS_standbySupplyContinuousPower 0;
BA_ "SystemSignalLongSymbol" SG_ 914 BMS_standbySupplyContinuousPower "BMS_standbySupplyContinuousPowerLimit";
BA_ "Confidence" SG_ 914 BMS_beginningOfLifePackEnergy 0;
BA_ "GenSigSNA" SG_ 914 BMS_beginningOfLifePackEnergy "1023";
BA_ "Confidence" SG_ 1810 BMS_packTemperatureMultiplexer 1;
BA_ "Confidence" SG_ 1810 BMS_packTemperatureCounter 0;
BA_ "Confidence" SG_ 1810 BMS_packTemperatureStatus1 0;
BA_ "Confidence" SG_ 1810 BMS_packTemperatureStatus2 0;
BA_ "Confidence" SG_ 1810 BMS_packTemperatureStatus3 0;
BA_ "Confidence" SG_ 1810 BMS_packTemperature1 0;
BA_ "Confidence" SG_ 1810 BMS_packTemperature2 0;
BA_ "Confidence" SG_ 1810 BMS_packTemperature3 0;
BA_ "Confidence" SG_ 1810 BMS_packTemperatureStatus4 0;
BA_ "Confidence" SG_ 1810 BMS_packTemperatureStatus5 0;
BA_ "Confidence" SG_ 1810 BMS_packTemperatureStatus6 0;
BA_ "Confidence" SG_ 1810 BMS_packTemperature4 0;
BA_ "Confidence" SG_ 1810 BMS_packTemperature5 0;
BA_ "Confidence" SG_ 1810 BMS_packTemperature6 0;
BA_ "Confidence" SG_ 1810 BMS_packTemperatureStatus7 0;
BA_ "Confidence" SG_ 1810 BMS_packTemperatureStatus8 0;
BA_ "Confidence" SG_ 1810 BMS_packTemperatureStatus9 0;
BA_ "Confidence" SG_ 1810 BMS_packTemperature7 0;
BA_ "Confidence" SG_ 1810 BMS_packTemperature8 0;
BA_ "Confidence" SG_ 1810 BMS_packTemperature9 0;
BA_ "Confidence" SG_ 1810 BMS_packTemperatureStatus10 0;
BA_ "Confidence" SG_ 1810 BMS_packTemperatureStatus11 0;
BA_ "Confidence" SG_ 1810 BMS_packTemperatureStatus12 0;
BA_ "Confidence" SG_ 1810 BMS_packTemperature10 0;
BA_ "Confidence" SG_ 1810 BMS_packTemperature11 0;
BA_ "Confidence" SG_ 1810 BMS_packTemperature12 0;
BA_ "Confidence" SG_ 1810 BMS_packTemperatureStatus13 0;
BA_ "Confidence" SG_ 1810 BMS_packTemperatureStatus14 0;
BA_ "Confidence" SG_ 1810 BMS_packTemperatureStatus15 0;
BA_ "Confidence" SG_ 1810 BMS_packTemperature13 0;
BA_ "Confidence" SG_ 1810 BMS_packTemperature14 0;
BA_ "Confidence" SG_ 1810 BMS_packTemperature15 0;
BA_ "Confidence" SG_ 1810 BMS_packTemperatureStatus16 0;
BA_ "Confidence" SG_ 1810 BMS_packTemperatureStatus17 0;
BA_ "Confidence" SG_ 1810 BMS_packTemperatureStatus18 0;
BA_ "Confidence" SG_ 1810 BMS_packTemperature16 0;
BA_ "Confidence" SG_ 1810 BMS_packTemperature17 0;
BA_ "Confidence" SG_ 1810 BMS_packTemperature18 0;
BA_ "Confidence" SG_ 594 BMS_maxRegenPower 0;
BA_ "Confidence" SG_ 594 BMS_maxDischargePower 0;
BA_ "Confidence" SG_ 594 BMS_maxStationaryHeatPower 0;
BA_ "Confidence" SG_ 594 BMS_powerLimitsState 0;
BA_ "Confidence" SG_ 594 BMS_totalHvPowerBudget 0;
BA_ "Confidence" SG_ 594 BMS_notEnoughPowerForHeatPump 0;
BA_ "Confidence" SG_ 674 BMS_acRippleCurrentAmplitudeLimi 0;
BA_ "SystemSignalLongSymbol" SG_ 674 BMS_acRippleCurrentAmplitudeLimi "BMS_acRippleCurrentAmplitudeLimit";
BA_ "Confidence" SG_ 674 BMS_acRippleMaxVoltageLimit 0;
BA_ "Confidence" SG_ 674 BMS_acRippleMinVoltageLimit 0;
BA_ "Confidence" SG_ 674 BMS_acRippleFrequencyRequest 0;
BA_ "GenSigSNA" SG_ 674 BMS_acRippleFrequencyRequest "1023";
BA_ "Confidence" SG_ 674 BMS_acRippleCurrentAmplitudeRequ 0;
BA_ "SystemSignalLongSymbol" SG_ 674 BMS_acRippleCurrentAmplitudeRequ "BMS_acRippleCurrentAmplitudeRequest";
BA_ "Confidence" SG_ 674 BMS_acRippleRequest 0;
BA_ "Confidence" SG_ 1834 BMS_serialNumberMultiplexer 1;
BA_ "Confidence" SG_ 1834 BMS_packSerialNumberByte01 0;
BA_ "Confidence" SG_ 1834 BMS_packSerialNumberByte02 0;
BA_ "Confidence" SG_ 1834 BMS_packSerialNumberByte03 0;
BA_ "Confidence" SG_ 1834 BMS_packSerialNumberByte04 0;
BA_ "Confidence" SG_ 1834 BMS_packSerialNumberByte05 0;
BA_ "Confidence" SG_ 1834 BMS_packSerialNumberByte06 0;
BA_ "Confidence" SG_ 1834 BMS_packSerialNumberByte07 0;
BA_ "Confidence" SG_ 1834 BMS_packSerialNumberByte08 0;
BA_ "Confidence" SG_ 1834 BMS_packSerialNumberByte09 0;
BA_ "Confidence" SG_ 1834 BMS_packSerialNumberByte10 0;
BA_ "Confidence" SG_ 1834 BMS_packSerialNumberByte11 0;
BA_ "Confidence" SG_ 1834 BMS_packSerialNumberByte12 0;
BA_ "Confidence" SG_ 1834 BMS_packSerialNumberByte13 0;
BA_ "Confidence" SG_ 1834 BMS_packSerialNumberByte14 0;
BA_ "Confidence" SG_ 1834 BMS_packSerialBirthDateBinned 1;
BA_ "Confidence" SG_ 658 BMS_socMin 0;
BA_ "Confidence" SG_ 658 BMS_socUI 0;
BA_ "Confidence" SG_ 658 BMS_socMax 0;
BA_ "Confidence" SG_ 658 BMS_socAvg 0;
BA_ "Confidence" SG_ 658 BMS_enoughEnergyForConvenienceFe 0;
BA_ "SystemSignalLongSymbol" SG_ 658 BMS_enoughEnergyForConvenienceFe "BMS_enoughEnergyForConvenienceFeatures";
BA_ "Confidence" SG_ 658 BMS_instantChargePowerCapability 0;
BA_ "GenSigSNA" SG_ 658 BMS_instantChargePowerCapability "65535";
BA_ "Confidence" SG_ 1170 BMS_sohEnergyPercent 0;
BA_ "GenSigSNA" SG_ 1170 BMS_sohEnergyPercent "1023";
BA_ "Confidence" SG_ 1170 BMS_userFacingSohTestState 0;
BA_ "Confidence" SG_ 1170 BMS_userFacingSohTestEndMode 0;
BA_ "Confidence" SG_ 1170 BMS_timeSinceSohUpdate 0;
BA_ "GenSigSNA" SG_ 1170 BMS_timeSinceSohUpdate "4095";
BA_ "Confidence" SG_ 1170 BMS_sohTestCycleFlag 0;
BA_ "Confidence" SG_ 1170 BMS_sohTestIsBlocked 0;
BA_ "Confidence" SG_ 1170 BMS_calibratedSohAvailable 0;
BA_ "Confidence" SG_ 1170 BMS_requiredEvsePowerForSoh 0;
BA_ "GenSigSNA" SG_ 1170 BMS_requiredEvsePowerForSoh "255";
BA_ "Confidence" SG_ 1170 BMS_distanceSinceSohUpdate 0;
BA_ "GenSigSNA" SG_ 1170 BMS_distanceSinceSohUpdate "65535";
BA_ "Confidence" SG_ 530 BMS_hvacPowerRequest 0;
BA_ "Confidence" SG_ 530 BMS_notEnoughPowerForDrive 0;
BA_ "Confidence" SG_ 530 BMS_notEnoughPowerForSupport 0;
BA_ "Confidence" SG_ 530 BMS_preconditionAllowed 0;
BA_ "Confidence" SG_ 530 BMS_updateAllowed 0;
BA_ "Confidence" SG_ 530 BMS_cpMiaOnHvs 0;
BA_ "Confidence" SG_ 530 BMS_pcsPwmEnabled 0;
BA_ "Confidence" SG_ 530 BMS_contactorState 0;
BA_ "GenSigSNA" SG_ 530 BMS_contactorState "0";
BA_ "Confidence" SG_ 530 BMS_userChargeStatus 0;
BA_ "Confidence" SG_ 530 BMS_batteryInputPower 0;
BA_ "GenSigSNA" SG_ 530 BMS_batteryInputPower "65535";
BA_ "Confidence" SG_ 530 BMS_chargeRequest 0;
BA_ "Confidence" SG_ 530 BMS_state 0;
BA_ "GenSigSNA" SG_ 530 BMS_state "9";
BA_ "Confidence" SG_ 530 BMS_diLimpRequest 0;
BA_ "Confidence" SG_ 530 BMS_okToShipByAir 0;
BA_ "Confidence" SG_ 530 BMS_okToShipByLand 0;
BA_ "Confidence" SG_ 530 BMS_chgPowerAvailable 0;
BA_ "GenSigSNA" SG_ 530 BMS_chgPowerAvailable "4095";
BA_ "Confidence" SG_ 530 BMS_acManagerState 0;
BA_ "Confidence" SG_ 530 BMS_conditioningRequest 0;
BA_ "Confidence" SG_ 530 BMS_smStateRequest 0;
BA_ "GenSigSNA" SG_ 530 BMS_smStateRequest "9";
BA_ "Confidence" SG_ 530 BMS_hvState 0;
BA_ "Confidence" SG_ 786 BMS_thermalStatusMultiplexer 1;
BA_ "Confidence" SG_ 786 BMS_inletActiveCoolTargetT 0;
BA_ "Confidence" SG_ 786 BMS_inletPassiveTargetT 0;
BA_ "Confidence" SG_ 786 BMS_inletActiveHeatTargetT 0;
BA_ "Confidence" SG_ 786 BMS_requestDischarge 0;
BA_ "Confidence" SG_ 786 BMS_activeHeatingWorthwhile 0;
BA_ "Confidence" SG_ 786 BMS_pcsNoFlowRequest 0;
BA_ "Confidence" SG_ 786 BMS_minPackTemperature 0;
BA_ "Confidence" SG_ 786 BMS_noFlowRequest 0;
BA_ "Confidence" SG_ 786 BMS_maxPackTemperature 0;
BA_ "Confidence" SG_ 786 BMS_flowRequest 0;
BA_ "Confidence" SG_ 786 BMS_coldStagnationLimit 0;
BA_ "Confidence" SG_ 786 BMS_hotStagnationLimit 0;
BA_ "Confidence" SG_ 786 BMS_hotCellTempLimit 0;
BA_ "Confidence" SG_ 786 BMS_i2tDeratingEnabled 0;
BA_ "Confidence" SG_ 786 BMS_activeCoolCellReferenceT 0;
BA_ "Confidence" SG_ 786 BMS_activeHeatCellTargetT 0;
BA_ "Confidence" SG_ 786 BMS_powerDissipation 0;
BA_ "Confidence" SG_ 1554 BMS_udsResponseData 1;
BA_ "Confidence" SG_ 1071 BMS_v2xSoe 0;
BA_ "GenSigSNA" SG_ 1071 BMS_v2xSoe "65535";
BA_ "Confidence" SG_ 1071 BMS_v2xFullEnergy 0;
BA_ "GenSigSNA" SG_ 1071 BMS_v2xFullEnergy "4095";
BA_ "Confidence" SG_ 1071 BMS_v2xPackPower 0;
BA_ "GenSigSNA" SG_ 1071 BMS_v2xPackPower "511";
BA_ "Confidence" SG_ 1071 BMS_acDischargeBlockedReason 0;
BA_ "Confidence" SG_ 1071 BMS_backupTimeRemaining 0;
BA_ "GenSigSNA" SG_ 1071 BMS_backupTimeRemaining "255";
BA_ "Confidence" SG_ 754 BMS_nmGoingToSleep 0;
BA_ "Confidence" SG_ 754 BMS_nmWakeUpBus 0;
BA_ "Confidence" SG_ 754 BMS_hvsBusAsleep 0;
BA_ "Confidence" SG_ 754 BMS_nmKeepAwakeReason 0;
BA_ "GenSigSNA" SG_ 754 BMS_nmKeepAwakeReason "0";
BA_ "Confidence" SG_ 754 BMS_nmWakeUpReason 0;
BA_ "Confidence" SG_ 810 BMS_thermalEventSuspected 0;
BA_ "Confidence" SG_ 810 BMS_vehicleNotificationsCounter 0;
BA_ "Confidence" SG_ 810 BMS_isolationResistance 0;
BA_ "GenSigSNA" SG_ 810 BMS_isolationResistance "1023";
BA_ "Confidence" SG_ 810 BMS_chgTimeToFull 0;
BA_ "GenSigSNA" SG_ 810 BMS_chgTimeToFull "4095";
BA_ "Confidence" SG_ 810 BMS_vehicleNotificationsChecksum 0;
BA_ "Confidence" SG_ 1116 CC_alertID 1;
BA_ "Confidence" SG_ 1116 CC_alertType 1;
BA_ "Confidence" SG_ 1116 CC_a001_groundResistance 1;
BA_ "GenSigSNA" SG_ 1116 CC_a001_groundResistance "4095";
BA_ "Confidence" SG_ 1116 CC_a003_gfciRmsCurrent 1;
BA_ "Confidence" SG_ 1116 CC_a003_gfciRmsCurrentAvg 1;
BA_ "Confidence" SG_ 1116 CC_a003_dcGfciCurrent 1;
BA_ "Confidence" SG_ 1116 CC_a003_gfciFaultReason 1;
BA_ "GenSigSNA" SG_ 1116 CC_a003_gfciFaultReason "0";
BA_ "Confidence" SG_ 1116 CC_a004_gfciErrorReason 1;
BA_ "GenSigSNA" SG_ 1116 CC_a004_gfciErrorReason "0";
BA_ "Confidence" SG_ 1116 CC_a004_gfciSelfTestDuty 1;
BA_ "Confidence" SG_ 1116 CC_a004_gfciSelfTestCurrent 1;
BA_ "Confidence" SG_ 1116 CC_a006_line1Current 1;
BA_ "Confidence" SG_ 1116 CC_a006_line2Current 1;
BA_ "Confidence" SG_ 1116 CC_a006_line3Current 1;
BA_ "Confidence" SG_ 1116 CC_a007_inputVoltage 1;
BA_ "Confidence" SG_ 1116 CC_a007_inputLineVoltage 1;
BA_ "Confidence" SG_ 1116 CC_a007_inputNeutralVoltage 1;
BA_ "Confidence" SG_ 1116 CC_a008_inputVoltage 1;
BA_ "Confidence" SG_ 1116 CC_a008_inputLineVoltage 1;
BA_ "Confidence" SG_ 1116 CC_a008_inputNeutralVoltage 1;
BA_ "Confidence" SG_ 1116 CC_a010_line1Voltage 1;
BA_ "Confidence" SG_ 1116 CC_a010_line2Voltage 1;
BA_ "Confidence" SG_ 1116 CC_a010_line3Voltage 1;
BA_ "Confidence" SG_ 1116 CC_a011_pcbaTemp 1;
BA_ "Confidence" SG_ 1116 CC_a012_inputThermopile 1;
BA_ "Confidence" SG_ 1116 CC_a012_inputThermopileDvdt 1;
BA_ "Confidence" SG_ 1116 CC_a013_handleTemp 1;
BA_ "Confidence" SG_ 1116 CC_a014_failureCause 1;
BA_ "Confidence" SG_ 1116 CC_a015_pilotHighVolage 1;
BA_ "Confidence" SG_ 1116 CC_a027_handleTemperature 1;
BA_ "Confidence" SG_ 1116 CC_a027_handleTempFaultReason 1;
BA_ "Confidence" SG_ 1116 CC_a033_nominalVoltage 1;
BA_ "Confidence" SG_ 1116 CC_a033_measuredVoltage 1;
BA_ "Confidence" SG_ 1116 CC_a036_line1Voltage 1;
BA_ "Confidence" SG_ 1116 CC_a036_line2Voltage 1;
BA_ "Confidence" SG_ 1116 CC_a036_line3Voltage 1;
BA_ "Confidence" SG_ 1116 CC_a039_intModuleTemperature 1;
BA_ "Confidence" SG_ 1116 CC_a040_handleTemperature 1;
BA_ "Confidence" SG_ 1116 CC_a041_inputThermopile 1;
BA_ "Confidence" SG_ 1116 CC_a041_inputThermopileDvdt 1;
BA_ "Confidence" SG_ 1116 CC_a042_pcbaTemperature 1;
BA_ "Confidence" SG_ 1116 CC_a044_relayCoilVoltage 1;
BA_ "Confidence" SG_ 1116 CC_a044_pcbaTemperature 1;
BA_ "SystemSignalLongSymbol" SG_ 1132 CC_a037_internalModuleWatchdogEx "CC_a037_internalModuleWatchdogExpired";
BA_ "SystemSignalLongSymbol" SG_ 1132 CC_a044_relayCoilVoltageRational "CC_a044_relayCoilVoltageRationality";
BA_ "Confidence" SG_ 796 CC_currentLimit 0;
BA_ "GenSigSNA" SG_ 796 CC_currentLimit "255";
BA_ "Confidence" SG_ 796 CC_pilotState 0;
BA_ "GenSigSNA" SG_ 796 CC_pilotState "3";
BA_ "Confidence" SG_ 796 CC_numPhases 0;
BA_ "GenSigSNA" SG_ 796 CC_numPhases "0";
BA_ "Confidence" SG_ 796 CC_line1Voltage 0;
BA_ "GenSigSNA" SG_ 796 CC_line1Voltage "511";
BA_ "Confidence" SG_ 796 CC_gridGrounding 0;
BA_ "GenSigSNA" SG_ 796 CC_gridGrounding "2";
BA_ "Confidence" SG_ 796 CC_deltaTransformer 0;
BA_ "Confidence" SG_ 796 CC_numVehCharging 0;
BA_ "Confidence" SG_ 796 CC_line2Voltage 0;
BA_ "GenSigSNA" SG_ 796 CC_line2Voltage "511";
BA_ "Confidence" SG_ 796 CC_line3Voltage 0;
BA_ "GenSigSNA" SG_ 796 CC_line3Voltage "511";
BA_ "Confidence" SG_ 796 CC_groundResistance 0;
BA_ "GenSigSNA" SG_ 796 CC_groundResistance "4095";
BA_ "Confidence" SG_ 797 CC_chgStatus2Index 1;
BA_ "Confidence" SG_ 797 CC_buttonState 0;
BA_ "Confidence" SG_ 797 EVSE_v2xSupport 0;
BA_ "Confidence" SG_ 797 EVSE_v2xHandshakeStart 0;
BA_ "Confidence" SG_ 797 EVSE_v2xSessionType 0;
BA_ "GenSigSNA" SG_ 797 EVSE_v2xSessionType "0";
BA_ "Confidence" SG_ 812 CC_logIndex 1;
BA_ "Confidence" SG_ 812 CC_activeConnectorID 0;
BA_ "Confidence" SG_ 812 CC_temperature1 0;
BA_ "Confidence" SG_ 812 CC_temperature2 0;
BA_ "Confidence" SG_ 812 CC_temperature3 0;
BA_ "Confidence" SG_ 812 CC_contactor1Closed 0;
BA_ "Confidence" SG_ 812 CC_contactor2Closed 0;
BA_ "Confidence" SG_ 812 CC_temperature4 0;
BA_ "Confidence" SG_ 812 CC_conn1Current 0;
BA_ "GenSigSNA" SG_ 812 CC_conn1Current "255";
BA_ "Confidence" SG_ 812 CC_conn2Current 0;
BA_ "GenSigSNA" SG_ 812 CC_conn2Current "255";
BA_ "Confidence" SG_ 812 CC_conn3Current 0;
BA_ "GenSigSNA" SG_ 812 CC_conn3Current "255";
BA_ "Confidence" SG_ 812 CC_conn4Current 0;
BA_ "GenSigSNA" SG_ 812 CC_conn4Current "255";
BA_ "Confidence" SG_ 812 CC_lifetimei2t 0;
BA_ "Confidence" SG_ 812 CC_lifetimeCtrCycles 0;
BA_ "Confidence" SG_ 812 CC_lifetimeCtrCyclesLoaded 0;
BA_ "Confidence" SG_ 812 CC_lifetimeAlertCount 0;
BA_ "Confidence" SG_ 812 CC_lifetimeThermalFoldbacks 0;
BA_ "Confidence" SG_ 812 CC_lifetimeAvgStartupTemp 0;
BA_ "Confidence" SG_ 870 CMPD_infoIndex 1;
BA_ "Confidence" SG_ 870 CMPD_infoBuildType 0;
BA_ "Confidence" SG_ 870 CMPD_infoBuildConfigId 0;
BA_ "Confidence" SG_ 870 CMPD_infoHardwareId 0;
BA_ "Confidence" SG_ 870 CMPD_infoComponentId 0;
BA_ "Confidence" SG_ 870 CMPD_infoPcbaId 0;
BA_ "Confidence" SG_ 870 CMPD_infoAssemblyId 0;
BA_ "GenSigSNA" SG_ 870 CMPD_infoAssemblyId "255";
BA_ "Confidence" SG_ 870 CMPD_infoUsageId 0;
BA_ "Confidence" SG_ 870 CMPD_infoSubUsageId 0;
BA_ "Confidence" SG_ 679 CMPD_speedRPM 0;
BA_ "Confidence" SG_ 679 CMPD_speedDuty 0;
BA_ "Confidence" SG_ 679 CMPD_inputHVPower 0;
BA_ "Confidence" SG_ 679 CMPD_inputHVCurrent 0;
BA_ "Confidence" SG_ 679 CMPD_inputHVVoltage 0;
BA_ "Confidence" SG_ 679 CMPD_2ShuntModeActive 0;
BA_ "Confidence" SG_ 679 CMPD_powerLimitActive 0;
BA_ "Confidence" SG_ 679 CMPD_state 0;
BA_ "GenSigSNA" SG_ 679 CMPD_state "15";
BA_ "Confidence" SG_ 679 CMPD_wasteHeatState 0;
BA_ "Confidence" SG_ 679 CMPD_powerLimitTooLowToStart 0;
BA_ "Confidence" SG_ 679 CMPD_ready 0;
BA_ "Confidence" SG_ 1559 CMPD_udsResponseData 1;
BA_ "Confidence" SG_ 867 CMP_infoIndex 1;
BA_ "Confidence" SG_ 867 CMP_infoBuildType 0;
BA_ "Confidence" SG_ 867 CMP_infoBuildConfigId 0;
BA_ "Confidence" SG_ 867 CMP_infoHardwareId 0;
BA_ "Confidence" SG_ 867 CMP_infoComponentId 0;
BA_ "Confidence" SG_ 867 CMP_infoPcbaId 0;
BA_ "Confidence" SG_ 867 CMP_infoAssemblyId 0;
BA_ "GenSigSNA" SG_ 867 CMP_infoAssemblyId "255";
BA_ "Confidence" SG_ 867 CMP_infoUsageId 0;
BA_ "Confidence" SG_ 867 CMP_infoSubUsageId 0;
BA_ "Confidence" SG_ 867 CMP_infoPlatformType 0;
BA_ "Confidence" SG_ 867 CMP_infoAppCrc 0;
BA_ "Confidence" SG_ 867 CMP_infoBootUdsProtoVersion 0;
BA_ "Confidence" SG_ 867 CMP_infoBootCrc 0;
BA_ "Confidence" SG_ 1555 CMP_udsResponseData 1;
VAL_ 946 BMS_log2MuxId 95 "MUX_95" 94 "SOC_IMBALANCE_BY_DV_DSOC" 93 "MUX_93" 92 "BANDOLIER_MODEL_THERMISTOR_TEMPS_2" 91 "MUX_91" 90 "MUX_90" 89 "MUX_89" 88 "MUX_88" 87 "MUX_87" 86 "MUX_86" 85 "MUX_85" 84 "MUX_84" 83 "MUX_83" 82 "MUX_82" 81 "MUX_81" 80 "MUX_80" 79 "MUX_79" 78 "BANDOLIER_MODEL_THERMISTOR_TEMPS_1" 77 "MUX_77" 76 "MUX_76" 75 "MUX_75" 74 "MUX_74" 73 "MUX_73" 72 "MUX_72" 71 "MUX_71" 70 "MUX_70" 69 "MUX_69" 68 "MUX_68" 67 "MUX_67" 66 "MUX_66" 65 "MUX_65" 64 "MUX_64" 63 "MUX_63" 62 "MUX_62" 61 "MUX_61" 60 "MUX_60" 59 "MUX_59" 58 "MUX_58" 57 "MUX_57" 56 "MUX_56" 55 "LIFE_MODEL_HIST_SUMMARY_DATA" 54 "LIFE_MODEL_STORAGE_HIST_DATA" 53 "SPME_MAX_SOC_BRICK_DATA" 52 "SPME_MIN_SOC_BRICK_DATA" 51 "SPME_DATA_3" 50 "SPME_BRICK_1_DATA_2" 49 "SPME_BRICK_1_DATA_1" 48 "SPME_PACK_LEVEL" 47 "BRICK_BLEED_TIMES_5" 46 "HISTOGRAMS_SUMMARY" 45 "SOH" 44 "CAC4" 43 "ISOLATION" 42 "BRICK_BLEED_TIMES_4" 41 "BRICK_BLEED_TIMES_3" 40 "BRICK_BLEED_TIMES_2" 39 "BRICK_BLEED_TIMES_1" 38 "LIFE_MODEL" 37 "BRICK_BALANCE_4" 36 "BRICK_BALANCE_3" 35 "BRICK_BALANCE_2" 34 "BRICK_BALANCE_1" 33 "ALPHA_1" 32 "HISTOGRAMS_4" 31 "HISTOGRAMS_3" 30 "HISTOGRAMS_2" 29 "HISTOGRAMS_1" 28 "HISTOGRAMS_0" 27 "VSH_RES_3" 26 "VSH_RES_2" 25 "VSH_RES_1" 24 "SOC_BY_OCV_CORRECTION" 23 "BRICK_VOLTAGE_CHANGE" 22 "CAC3" 21 "ENERGY_AND_REST_DATA" 20 "FC_LINK_LEAKAGE_TEST" 19 "ENERGY_RESERVE" 18 "HV_CHAIN_MODEL" 17 "NEG_CTR_HEALTH_4" 16 "NEG_CTR_HEALTH_3" 15 "NEG_CTR_HEALTH_2" 14 "NEG_CTR_HEALTH_1" 13 "POS_CTR_HEALTH_4" 12 "POS_CTR_HEALTH_3" 11 "POS_CTR_HEALTH_2" 10 "POS_CTR_HEALTH_1" 9 "CTR_RESISTANCE" 8 "100HZ_1KHZ_TASK_STATS" 7 "10HZ_TASK_STATS" 6 "1HZ_TASK_STATS" 5 "AHR_COUNTER" 4 "CHARGING" 3 "VSH_TEST" 2 "FLOOD_PORT" 1 "CAC2" 0 "CAC1" ;
VAL_ 946 BMS_hvChain_iLimit 16383 "SNA" ;
VAL_ 946 BMS_hvChain_limitingState 511 "SNA" ;
VAL_ 946 BMS_hvChain_limitingStateTempera -4096 "SNA" ;
VAL_ 946 BMS_fcLinkTestDecayTime 1023 "SNA" ;
VAL_ 946 BMS_pcsPrechargeRequest 2 "LV_DISCHARGE" 1 "FC_LINK_TEST" 0 "PRECHARGE_INACTIVE" ;
VAL_ 946 BMS_idealEnergyFloor 1023 "SNA" ;
VAL_ 946 BMS_dynamicEnergyBuffer 1023 "SNA" ;
VAL_ 946 BMS_dSocNormalizedMin 4095 "SNA" ;
VAL_ 946 BMS_dSocNormalizedFiltMin 4095 "SNA" ;
VAL_ 946 BMS_dSocMinAlpha 4095 "SNA" ;
VAL_ 946 BMS_dSocCacMargin 511 "SNA" ;
VAL_ 946 BMS_lifeModelNoCurrentStorageCap 511 "SNA" ;
VAL_ 946 BMS_lifeModelShortDcr 255 "SNA" ;
VAL_ 946 BMS_lifeModelLongDcr -4096 "SNA" ;
VAL_ 946 BMS_lifeModelStorageCapacityLoss 511 "SNA" ;
VAL_ 946 BMS_lifeModelThroughputCapacityL 511 "SNA" ;
VAL_ 946 BMS_lifeModelAvgTempSeverity 31 "SNA" ;
VAL_ 946 BMS_lifeModelDepthOfDischargeSev 255 "SNA" ;
VAL_ 946 BMS_lifeModelHistogramCapacityLo 511 "SNA" ;
VAL_ 946 BMS_lifeModelHistogramBrickCapac 8191 "SNA" ;
VAL_ 946 BMS_lifeModelDcrGrowthPercent -8192 "SNA" ;
VAL_ 946 BMS_nominalFullPackEnergyRaw 65535 "SNA" ;
VAL_ 946 BMS_nominalEnergyRemainingBuffer 65535 "SNA" ;
VAL_ 946 BMS_idealEnergyRemainingBuffered 65535 "SNA" ;
VAL_ 946 BMS_largestSynchronizedCacErrorP 255 "SNA" ;
VAL_ 946 BMS_lifeModelSpreadMinOffset -512 "SNA" ;
VAL_ 946 BMS_lifeModelSpreadMaxOffset -512 "SNA" ;
VAL_ 946 BMS_largestCacSpreadErrorLower 4095 "SNA" ;
VAL_ 946 BMS_lifeModelAverageCac 4095 "SNA" ;
VAL_ 946 BMS_lifeModelCacBrick1 4095 "SNA" ;
VAL_ 946 BMS_lifeModelAverageOffset -512 "SNA" ;
VAL_ 946 BMS_lifeModelMaxCacBrickId 255 "SNA" ;
VAL_ 946 BMS_lifeModelMaxCac 4095 "SNA" ;
VAL_ 946 BMS_lifeModelMinCacBrickId 255 "SNA" ;
VAL_ 946 BMS_lifeModelMinCac 4095 "SNA" ;
VAL_ 946 BMS_restingPointCacAvg 4095 "SNA" ;
VAL_ 946 BMS_cacEstimationSource 2 "CAC_SOURCE_LIFE_MODEL" 1 "CAC_SOURCE_RESTING_POINT_CAC" 0 "CAC_SOURCE_UNKNOWN" ;
VAL_ 946 BMS_synchronizedCacMaxRaw 4095 "SNA" ;
VAL_ 946 BMS_synchronizedCacMinRaw 4095 "SNA" ;
VAL_ 946 BMS_sohEnergy 2047 "SNA" ;
VAL_ 946 BMS_fullCapacitySohEnergy 2047 "SNA" ;
VAL_ 946 BMS_calibratedCapacitySohEnergy 2047 "SNA" ;
VAL_ 946 BMS_estimatedCapacitySohEnergy 2047 "SNA" ;
VAL_ 946 BMS_prevUserFacingSohEnergy 2047 "SNA" ;
VAL_ 946 BMS_stateOfHealthMinCac 8191 "SNA" ;
VAL_ 946 BMS_lifeModelStorageLossPackAge 16383 "SNA" ;
VAL_ 946 BMS_lifeModelThroughputDcrCycleC 4095 "SNA" ;
VAL_ 946 BMS_stateOfHealthMinCacLowerBoun 8191 "SNA" ;
VAL_ 946 BMS_stateOfHealth 1023 "SNA" ;
VAL_ 946 BMS_avgShuntAsicCurrentOffset -16384 "SNA" ;
VAL_ 946 BMS_cellAttributesGeneralAttribu 0 "SNA" ;
VAL_ 946 BMS_cellAttributesPackManufactur 0 "SNA" ;
VAL_ 946 BMS_cellAttributesCellType 0 "SNA" ;
VAL_ 946 BMS_lifeModelThroughputCycleCoun 4095 "SNA" ;
VAL_ 946 BMS_limpChargeCurrentLimit 1023 "SNA" ;
VAL_ 946 BMS_maxModelThermistorTempDelta -512 "SNA" ;
VAL_ 946 BMS_cellTempTargetMode 11 "V2X_SESSION" 10 "PASSIVE_COOL_ON_NAV" 9 "ACTIVE_COOL_ON_NAV" 8 "SOH_HEAT_PACK" 7 "DRAGSTRIP" 6 "PASSIVE_HEAT_ON_NAV" 5 "ACTIVE_HEAT_ON_NAV" 4 "DISCONNECTED_PRECONDITION" 3 "CONNECTED_PRECONDITION" 2 "HIGH_POWER_CHARGE" 1 "LOW_POWER_CHARGE" 0 "DEFAULT" ;
VAL_ 914 BMS_packConfigMultiplexer 1 "Mux1" 0 "Mux0" ;
VAL_ 914 BMS_reservedConfig_0 36 "BMS_CONFIG_36" 35 "BMS_CONFIG_35" 34 "BMS_CONFIG_34" 33 "BMS_CONFIG_33" 32 "BMS_CONFIG_32" 31 "BMS_CONFIG_31" 30 "BMS_CONFIG_30" 29 "BMS_CONFIG_29" 28 "BMS_CONFIG_28" 27 "BMS_CONFIG_27" 26 "BMS_CONFIG_26" 25 "BMS_CONFIG_25" 24 "BMS_CONFIG_24" 23 "BMS_CONFIG_23" 22 "BMS_CONFIG_22" 21 "BMS_CONFIG_21" 20 "BMS_CONFIG_20" 19 "BMS_CONFIG_19" 18 "BMS_CONFIG_18" 17 "BMS_CONFIG_17" 16 "BMS_CONFIG_16" 15 "BMS_CONFIG_15" 14 "BMS_CONFIG_14" 13 "BMS_CONFIG_13" 12 "BMS_CONFIG_12" 11 "BMS_CONFIG_11" 10 "BMS_CONFIG_10" 9 "BMS_CONFIG_9" 8 "BMS_CONFIG_8" 7 "BMS_CONFIG_7" 6 "BMS_CONFIG_6" 5 "BMS_CONFIG_5" 4 "BMS_CONFIG_4" 3 "BMS_CONFIG_3" 2 "BMS_CONFIG_2" 1 "BMS_CONFIG_1" 0 "BMS_CONFIG_0" ;
VAL_ 914 BMS_moduleType 5 "BMS_MOD_TYPE_5" 4 "BMS_MOD_TYPE_4" 3 "BMS_MOD_TYPE_3" 2 "BMS_MOD_TYPE_2" 1 "BMS_MOD_TYPE_1" 0 "BMS_MOD_TYPE_UNKNOWN" ;
VAL_ 914 BMS_thermalPackType 9 "E3D_40P" 8 "E3D" 7 "BLADERUNNER_E1" 6 "BFF00S" 5 "P2" 4 "BFF00_E1" 3 "CATL_E1" 2 "E3" 1 "E1" 0 "UNKNOWN" ;
VAL_ 914 BMS_standbySupplyContinuousPower 3 "17W" 2 "16W" 1 "4W" 0 "0W" ;
VAL_ 914 BMS_beginningOfLifePackEnergy 1023 "SNA" ;
VAL_ 1810 BMS_packTemperatureMultiplexer 5 "Mux5" 4 "Mux4" 3 "Mux3" 2 "Mux2" 1 "Mux1" 0 "Mux0" ;
VAL_ 1810 BMS_packTemperatureStatus1 3 "SENSOR_BYPASSED" 2 "SENSOR_NOMINAL" 1 "SENSOR_BAD" 0 "SENSOR_MISSING" ;
VAL_ 1810 BMS_packTemperatureStatus2 3 "SENSOR_BYPASSED" 2 "SENSOR_NOMINAL" 1 "SENSOR_BAD" 0 "SENSOR_MISSING" ;
VAL_ 1810 BMS_packTemperatureStatus3 3 "SENSOR_BYPASSED" 2 "SENSOR_NOMINAL" 1 "SENSOR_BAD" 0 "SENSOR_MISSING" ;
VAL_ 1810 BMS_packTemperatureStatus4 3 "SENSOR_BYPASSED" 2 "SENSOR_NOMINAL" 1 "SENSOR_BAD" 0 "SENSOR_MISSING" ;
VAL_ 1810 BMS_packTemperatureStatus5 3 "SENSOR_BYPASSED" 2 "SENSOR_NOMINAL" 1 "SENSOR_BAD" 0 "SENSOR_MISSING" ;
VAL_ 1810 BMS_packTemperatureStatus6 3 "SENSOR_BYPASSED" 2 "SENSOR_NOMINAL" 1 "SENSOR_BAD" 0 "SENSOR_MISSING" ;
VAL_ 1810 BMS_packTemperatureStatus7 3 "SENSOR_BYPASSED" 2 "SENSOR_NOMINAL" 1 "SENSOR_BAD" 0 "SENSOR_MISSING" ;
VAL_ 1810 BMS_packTemperatureStatus8 3 "SENSOR_BYPASSED" 2 "SENSOR_NOMINAL" 1 "SENSOR_BAD" 0 "SENSOR_MISSING" ;
VAL_ 1810 BMS_packTemperatureStatus9 3 "SENSOR_BYPASSED" 2 "SENSOR_NOMINAL" 1 "SENSOR_BAD" 0 "SENSOR_MISSING" ;
VAL_ 1810 BMS_packTemperatureStatus10 3 "SENSOR_BYPASSED" 2 "SENSOR_NOMINAL" 1 "SENSOR_BAD" 0 "SENSOR_MISSING" ;
VAL_ 1810 BMS_packTemperatureStatus11 3 "SENSOR_BYPASSED" 2 "SENSOR_NOMINAL" 1 "SENSOR_BAD" 0 "SENSOR_MISSING" ;
VAL_ 1810 BMS_packTemperatureStatus12 3 "SENSOR_BYPASSED" 2 "SENSOR_NOMINAL" 1 "SENSOR_BAD" 0 "SENSOR_MISSING" ;
VAL_ 1810 BMS_packTemperatureStatus13 3 "SENSOR_BYPASSED" 2 "SENSOR_NOMINAL" 1 "SENSOR_BAD" 0 "SENSOR_MISSING" ;
VAL_ 1810 BMS_packTemperatureStatus14 3 "SENSOR_BYPASSED" 2 "SENSOR_NOMINAL" 1 "SENSOR_BAD" 0 "SENSOR_MISSING" ;
VAL_ 1810 BMS_packTemperatureStatus15 3 "SENSOR_BYPASSED" 2 "SENSOR_NOMINAL" 1 "SENSOR_BAD" 0 "SENSOR_MISSING" ;
VAL_ 1810 BMS_packTemperatureStatus16 3 "SENSOR_BYPASSED" 2 "SENSOR_NOMINAL" 1 "SENSOR_BAD" 0 "SENSOR_MISSING" ;
VAL_ 1810 BMS_packTemperatureStatus17 3 "SENSOR_BYPASSED" 2 "SENSOR_NOMINAL" 1 "SENSOR_BAD" 0 "SENSOR_MISSING" ;
VAL_ 1810 BMS_packTemperatureStatus18 3 "SENSOR_BYPASSED" 2 "SENSOR_NOMINAL" 1 "SENSOR_BAD" 0 "SENSOR_MISSING" ;
VAL_ 594 BMS_powerLimitsState 1 "POWER_CALCULATED_FOR_DRIVE" 0 "POWER_NOT_CALCULATED_FOR_DRIVE" ;
VAL_ 674 BMS_acRippleFrequencyRequest 1023 "SNA" ;
VAL_ 674 BMS_acRippleRequest 4 "RIPPLE_FAULTED" 3 "RIPPLE_ON" 2 "RIPPLE_STANDBY" 1 "RIPPLE_OFF" 0 "RIPPLE_NOT_SUPPORTED" ;
VAL_ 1834 BMS_serialNumberMultiplexer 2 "BMS_SERIAL_MUX2" 1 "BMS_SERIAL_MUX1" 0 "BMS_SERIAL_MUX0" ;
VAL_ 658 BMS_instantChargePowerCapability 65535 "SNA" ;
VAL_ 1170 BMS_sohEnergyPercent 1023 "SNA" ;
VAL_ 1170 BMS_userFacingSohTestState 5 "CHARGE_REST" 4 "CHARGE" 3 "DISCHARGE_REST" 2 "DISCHARGE" 1 "HEAT_PACK" 0 "NOT_RUNNING" ;
VAL_ 1170 BMS_userFacingSohTestEndMode 5 "TEST_COMPLETE_WITH_SOC_IMBALANCE" 4 "TEST_COMPLETE" 3 "FAILED" 2 "REQUEST_DROPPED" 1 "RUNNING" 0 "NONE" ;
VAL_ 1170 BMS_timeSinceSohUpdate 4095 "SNA" ;
VAL_ 1170 BMS_requiredEvsePowerForSoh 255 "SNA" ;
VAL_ 1170 BMS_distanceSinceSohUpdate 65535 "SNA" ;
VAL_ 530 BMS_contactorState 6 "BMS_CTRSET_BLOCKED" 5 "BMS_CTRSET_WELDED" 4 "BMS_CTRSET_CLOSED" 3 "BMS_CTRSET_CLOSING" 2 "BMS_CTRSET_OPENING" 1 "BMS_CTRSET_OPEN" 0 "BMS_CTRSET_SNA" ;
VAL_ 530 BMS_userChargeStatus 6 "BMS_CALIBRATING" 5 "BMS_CHARGE_STOPPED" 4 "BMS_CHARGE_COMPLETE" 3 "BMS_CHARGING" 2 "BMS_ABOUT_TO_CHARGE" 1 "BMS_NO_POWER" 0 "BMS_DISCONNECTED" ;
VAL_ 530 BMS_batteryInputPower 65535 "SNA" ;
VAL_ 530 BMS_state 10 "BMS_DIAG" 9 "BMS_SNA" 8 "BMS_TEST" 7 "BMS_WELD" 6 "BMS_FAULT" 5 "BMS_CLEAR_FAULT" 4 "BMS_FEIM" 3 "BMS_CHARGE" 2 "BMS_SUPPORT" 1 "BMS_DRIVE" 0 "BMS_STANDBY" ;
VAL_ 530 BMS_diLimpRequest 1 "LIMP_REQUEST_WELDED" 0 "LIMP_REQUEST_NONE" ;
VAL_ 530 BMS_chgPowerAvailable 4095 "SNA" ;
VAL_ 530 BMS_acManagerState 11 "FAULTED" 10 "OPEN_AC_RELAYS" 9 "DISABLE_PCS" 8 "GRID_FORM_ACTIVE" 7 "GRID_FOLLOW_ACTIVE" 6 "TETHERING_ACTIVE" 5 "CHARGING_ACTIVE" 4 "ENABLE_PCS" 3 "ENABLE_FC_LINK_FOR_AC" 2 "REQUEST_POWER_TRANSFER" 1 "STANDBY" 0 "INACTIVE" ;
VAL_ 530 BMS_smStateRequest 10 "BMS_DIAG" 9 "BMS_SNA" 8 "BMS_TEST" 7 "BMS_WELD" 6 "BMS_FAULT" 5 "BMS_CLEAR_FAULT" 4 "BMS_FEIM" 3 "BMS_CHARGE" 2 "BMS_SUPPORT" 1 "BMS_DRIVE" 0 "BMS_STANDBY" ;
VAL_ 530 BMS_hvState 6 "HV_UP" 5 "HV_UP_FOR_DC_CHARGE" 4 "HV_UP_FOR_CHARGE" 3 "HV_UP_FOR_DRIVE" 2 "HV_GOING_DOWN" 1 "HV_COMING_UP" 0 "HV_DOWN" ;
VAL_ 786 BMS_thermalStatusMultiplexer 1 "Mux1" 0 "Mux0" ;
VAL_ 1071 BMS_v2xSoe 65535 "SNA" ;
VAL_ 1071 BMS_v2xFullEnergy 4095 "SNA" ;
VAL_ 1071 BMS_v2xPackPower 511 "SNA" ;
VAL_ 1071 BMS_acDischargeBlockedReason 41 "PRECHARGE_NOT_COMPLETE" 40 "EVSE_OUTPUT_CURRENT_NOT_LOW" 39 "ALL_RETRIES_EXHAUSTED" 38 "TEMP_TOO_LOW" 37 "FEATURE_DISABLED" 36 "SOE_TOO_LOW" 35 "AC_RELAYS_NOT_OPEN" 34 "PCS_NOT_DISABLED" 33 "CP_INLET_STILL_ENERGIZED" 32 "PCS_NOT_ENABLED" 31 "CP_NOT_ENABLED" 30 "CP_NOT_READY" 29 "SYSTEM_NOT_ENABLED" 28 "PCS_DISALLOWS" 27 "CP_DISALLOWS" 26 "SYSTEM_NOT_ALLOWED" 25 "SYSTEM_NOT_POSSIBLE" 24 "PCS_GRACEFUL_SHUTDOWN_REQUESTED" 23 "CP_GRACEFUL_SHUTDOWN_REQUESTED" 22 "NOT_NEEDED_OR_WANTED" 21 "EVSE_NOT_READY" 20 "EVSE_NOT_PRESENT" 19 "STATE_TIMEOUT_EXPIRED" 18 "FC_LINK_NOT_READY" 17 "FC_CONTACTORS_NOT_CLOSED" 16 "FC_CONTACTORS_NOT_OPEN" 15 "EVSE_NOT_COMPATIBLE" 14 "FC_LINK_NOT_ALLOWED_TO_ENERGIZE" 13 "ABORT_SUPERDISCHARGE_ALERT_SET" 12 "ABORT_CHARGE_ALERT_SET" 11 "PCS_ESCALATED_SHUTDOWN_REQUESTED" 10 "CP_ESCALATED_SHUTDOWN_REQUESTED" 7 "POWERSHARE_PROTECTION_TRIPPED" 6 "SYSTEM_DIRECTOR_FAULT_REQUESTED" 5 "CP_FAULT_LINE_ASSERTED" 4 "PCS_EMERGENCY_SHUTDOWN_REQUESTED" 3 "CP_EMERGENCY_SHUTDOWN_REQUESTED" 2 "PCS_MIA" 1 "CP_MIA" 0 "COND_NONE" ;
VAL_ 1071 BMS_backupTimeRemaining 255 "SNA" ;
VAL_ 754 BMS_nmKeepAwakeReason 8 "BMS_KEEPAWAKE_REASON_OTA" 7 "BMS_KEEPAWAKE_REASON_PRECONDITIONING" 6 "BMS_KEEPAWAKE_REASON_CP_ACTIVE" 5 "BMS_KEEPAWAKE_REASON_BMS_ACTIVE" 4 "BMS_KEEPAWAKE_REASON_HVP_ACTIVE" 3 "BMS_KEEPAWAKE_REASON_FC_CTR_CLEANING" 2 "BMS_KEEPAWAKE_REASON_CRITICAL_ALERT" 1 "BMS_KEEPAWAKE_REASON_CTRS_CLOSED" 0 "BMS_KEEPAWAKE_REASON_NONE_SNA" ;
VAL_ 754 BMS_nmWakeUpReason 4 "BMS_WAKEUP_REASON_CRITICALALERT" 3 "BMS_WAKEUP_REASON_WANTTOCHARGE" 2 "BMS_WAKEUP_REASON_CAN_HVS" 1 "BMS_WAKEUP_REASON_CAN_VEH" 0 "BMS_WAKEUP_REASON_NONE" ;
VAL_ 810 BMS_isolationResistance 1023 "SNA" ;
VAL_ 810 BMS_chgTimeToFull 4095 "SNA" ;
VAL_ 1116 CC_alertID 61 "a061_unfinishedCommissioning" 60 "a060_persistenceFault" 57 "a057_chcVitalsRequestFailure" 52 "a052_vRefOutOfRangePWM" 51 "a051_chcCriticalFault" 50 "a050_eFuseFault" 49 "a049_rs485Fault" 48 "a048_ACMDAdapterFault" 47 "a047_MDMotorContFault" 46 "a046_GFCIConfigInvalid" 45 "a045_ACPowerLoss" 44 "a044_relayCoilVoltageRationality" 43 "a043_configurationRequired" 42 "a042_pcbaTempFoldback" 41 "a041_inputWiringFoldback" 40 "a040_handleTempFoldback" 39 "a039_internalModuleOverTemp" 38 "a038_internalModuleMia" 37 "a037_internalModuleWatchdogExpired" 36 "a036_contactorStuckOpen" 35 "a035_CCIDCalibration" 34 "a034_bootAlert" 33 "a033_vRefOutOfRange" 32 "a032_meteringFailure" 31 "a031_pllLockLost" 30 "a030_masterSlaveMismatch" 29 "a029_PilotFFault" 28 "a028_CB_rotarySelect" 27 "a027_vehicleHandleTemp" 26 "a026_wallPlugTemp" 25 "a025_evseTemp" 24 "a024_CB_masterISetTooLow" 23 "a023_CB_tooManySlaves" 22 "a022_CB_tooManyMasters" 21 "a021_CB_noMaster" 20 "a020_3vRailIncorrect" 19 "a019_proxDisconnected" 18 "a018_PilotDFault" 17 "a017_PilotCFault" 16 "a016_PilotBFault" 15 "a015_PilotAFault" 14 "a014_mcuSelfTestFault" 13 "a013_vehConnOT" 12 "a012_wallPlugOT" 11 "a011_ambientOT" 10 "a010_contactorWelded" 9 "a009_inputMiswired" 8 "a008_inputUnderVoltage" 7 "a007_inputOverVoltage" 6 "a006_inputOverCurrent" 5 "a005_groundedNeutral" 4 "a004_CCIDSelfTestFault" 3 "a003_CCIDTripped" 2 "a002_gndMonIntrptLoadSide" 1 "a001_gndMonIntrptLineSide" 0 "ALERT_DO_NOT_USE_ZERO" ;
VAL_ 1116 CC_alertType 1 "SET" 0 "CLEARED" ;
VAL_ 1116 CC_a001_groundResistance 4095 "SNA" 4094 "NO_GROUND" ;
VAL_ 1116 CC_a003_gfciFaultReason 4 "DC_PEAK" 3 "DC_LPF" 2 "AC_PEAK" 1 "AC_LPF" 0 "SNA" ;
VAL_ 1116 CC_a004_gfciErrorReason 5 "TEST_SIGNAL_ERROR" 4 "AC_OFFSET_ERROR" 3 "DC_OFFSET_ERROR" 2 "ASIC_REASON" 1 "IO_ERROR" 0 "SNA" ;
VAL_ 1116 CC_a014_failureCause 4 "DCGFCI_INIT_FAILED" 3 "METER_INIT_FAILED" 2 "CONFIG_NOT_RECEIVED" 1 "OTHER" ;
VAL_ 1116 CC_a027_handleTempFaultReason 5 "CHC_OPEN_CIRCUIT" 4 "CHC_SHORT_CIRCUIT" 3 "CHC_INVALID_VITAL" 2 "NTC_BUTTON_PRESSED" 1 "NTC_OPEN_CIRCUIT" 0 "TEMP_GOOD" ;
VAL_ 796 CC_currentLimit 255 "SNA" ;
VAL_ 796 CC_pilotState 3 "CC_PILOT_STATE_SNA" 2 "CC_PILOT_STATE_FAULTED" 1 "CC_PILOT_STATE_IDLE" 0 "CC_PILOT_STATE_READY" ;
VAL_ 796 CC_numPhases 0 "SNA" ;
VAL_ 796 CC_line1Voltage 511 "SNA" ;
VAL_ 796 CC_gridGrounding 2 "CC_GRID_GROUNDING_SNA" 1 "CC_GRID_GROUNDING_IT_SplitPhase" 0 "CC_GRID_GROUNDING_TN_TT" ;
VAL_ 796 CC_line2Voltage 511 "SNA" ;
VAL_ 796 CC_line3Voltage 511 "SNA" ;
VAL_ 796 CC_groundResistance 4095 "SNA" 4094 "NO_GROUND" ;
VAL_ 797 CC_chgStatus2Index 0 "Mux0" ;
VAL_ 797 CC_buttonState 1 "CC_BUTTON_PRESSED" 0 "CC_BUTTON_RELEASED" ;
VAL_ 797 EVSE_v2xSupport 2 "V2X_OVER_SWCAN" 1 "V2X_OVER_PLC" 0 "V2X_NOT_SUPPORTED" ;
VAL_ 797 EVSE_v2xSessionType 0 "SESSION_TYPE_SNA" ;
VAL_ 812 CC_logIndex 13 "Mux13" 12 "Mux12" 11 "Mux11" 10 "Mux10" 4 "Mux4" 3 "Mux3" 2 "Mux2" 1 "Mux1" 0 "Mux0" ;
VAL_ 812 CC_activeConnectorID 255 "SNA" ;
VAL_ 812 CC_temperature1 127 "SNA" ;
VAL_ 812 CC_temperature2 127 "SNA" ;
VAL_ 812 CC_temperature3 127 "SNA" ;
VAL_ 812 CC_contactor1Closed 3 "CC_CONTACTOR_SNA" 1 "CC_CONTACTOR_CLOSED" 0 "CC_CONTACTOR_OPEN" ;
VAL_ 812 CC_contactor2Closed 3 "CC_CONTACTOR_SNA" 1 "CC_CONTACTOR_CLOSED" 0 "CC_CONTACTOR_OPEN" ;
VAL_ 812 CC_temperature4 127 "SNA" ;
VAL_ 812 CC_conn1Current 255 "SNA" ;
VAL_ 812 CC_conn2Current 255 "SNA" ;
VAL_ 812 CC_conn3Current 255 "SNA" ;
VAL_ 812 CC_conn4Current 255 "SNA" ;
VAL_ 870 CMPD_infoIndex 255 "END" 31 "SUBCOMPONENT_GITHASH" 30 "PACKAGE_SN_8_14" 29 "PACKAGE_SN_1_7" 27 "PACKAGE_PN_15_20" 26 "PACKAGE_PN_8_14" 25 "PACKAGE_PN_1_7" 23 "SUBCOMPONENT2" 22 "VARIANTCRC" 20 "UDS_PROTOCOL_BOOTCRC" 19 "VERSION_DEPRECATED" 18 "BOOTLOADER_GITHASH" 17 "APP_GITHASH" 16 "SUBCOMPONENT" 15 "BOOTLOADER_CRC" 14 "BOOTLOADER_SVN" 13 "APP_CRC" 11 "PCBAID_ASSYID_USAGEID" 10 "BUILD_HWID_COMPONENTID" 9 "DEPRECATED_9" 8 "DEPRECATED_8" 7 "DEPRECATED_7" 6 "DEPRECATED_6" 5 "DEPRECATED_5" 4 "DEPRECATED_4" 3 "DEPRECATED_3" 2 "DEPRECATED_2" 1 "DEPRECATED_1" 0 "DEPRECATED_0" ;
VAL_ 870 CMPD_infoBuildType 4 "INFO_MFG_BUILD" 3 "INFO_TRACEABLE_CI_BUILD" 2 "INFO_LOCAL_BUILD" 1 "INFO_PLATFORM_BUILD" 0 "INFO_UNKNOWN_BUILD" ;
VAL_ 870 CMPD_infoAssemblyId 255 "ASSEMBLY_SNA" 1 "ASSEMBLY1" ;
VAL_ 679 CMPD_state 15 "CMPD_STATE_SNA" 4 "CMPD_STATE_IDLE" 3 "CMPD_STATE_FAULT" 2 "CMPD_STATE_STANDBY" 1 "CMPD_STATE_RUNNING" 0 "CMPD_STATE_INIT" ;
VAL_ 679 CMPD_wasteHeatState 3 "CMPD_WASTE_HEAT_STATE_UNUSED" 2 "CMPD_WASTE_HEAT_STATE_NOT_AVAILABLE" 1 "CMPD_WASTE_HEAT_STATE_ACTIVE" 0 "CMPD_WASTE_HEAT_STATE_OFF" ;
VAL_ 867 CMP_infoIndex 255 "END" 31 "SUBCOMPONENT_GITHASH" 30 "PACKAGE_SN_8_14" 29 "PACKAGE_SN_1_7" 27 "PACKAGE_PN_15_20" 26 "PACKAGE_PN_8_14" 25 "PACKAGE_PN_1_7" 23 "SUBCOMPONENT2" 22 "VARIANTCRC" 20 "UDS_PROTOCOL_BOOTCRC" 19 "VERSION_DEPRECATED" 18 "BOOTLOADER_GITHASH" 17 "APP_GITHASH" 16 "SUBCOMPONENT" 15 "BOOTLOADER_CRC" 14 "BOOTLOADER_SVN" 13 "APP_CRC" 11 "PCBAID_ASSYID_USAGEID" 10 "BUILD_HWID_COMPONENTID" 9 "DEPRECATED_9" 8 "DEPRECATED_8" 7 "DEPRECATED_7" 6 "DEPRECATED_6" 5 "DEPRECATED_5" 4 "DEPRECATED_4" 3 "DEPRECATED_3" 2 "DEPRECATED_2" 1 "DEPRECATED_1" 0 "DEPRECATED_0" ;
VAL_ 867 CMP_infoBuildType 4 "INFO_MFG_BUILD" 3 "INFO_TRACEABLE_CI_BUILD" 2 "INFO_LOCAL_BUILD" 1 "INFO_PLATFORM_BUILD" 0 "INFO_UNKNOWN_BUILD" ;
VAL_ 867 CMP_infoAssemblyId 255 "ASSEMBLY_SNA" 1 "ASSEMBLY1" ;
